[part 2 of 15: package /Cluster]
AUTOSAR XML (schema 4-3-0)
package /Cluster
  can cluster WU_HCP3_CANFD: baudrate=500000, protocol-name=CAN, protocol-version=2.0, bus-off-recovery={bor-counter-l-1-to-l-2=1, bor-time-l-1=0.05, bor-time-l-2=0.2}, can-fd-baudrate=2000000
    can physical channel CHNL: comm-connectors=CN_WU_HCP3_CANFD
      frame KN_Gateway_XIX_WU_HCP3_CANFD: id 0x17F00010, to HCP3_IONode, frame-length=16, can-addressing-mode=EXTENDED, can-frame-rx-behavior=CAN-FD, can-frame-tx-behavior=CAN-FD
        pdu KN_Gateway_XIX_WU_HCP3_CANFD: length=16, transmission-mode-true-timing=cyclic-timing={time-offset=0.0, time-period=0.5}, unused-bit-pattern=0
          signal NM_GW_KompSchutz_XIX_KN_Gateway_XIX_WU_HCP3_CANFD: start 0, 1 bit, little-endian, data-type-policy=OVERRIDE, i-signal-type=PRIMITIVE, init-value=0, base-type=BT_NM_GW_KompSchutz, compu {0=Cx0_inaktiv (CM_NM_GW_KompSchutz_Cx0_inaktiv), 1=Cx1_aktiv (CM_NM_GW_KompSchutz_Cx1_aktiv)}, range raw 0..1, transfer-property=PENDING  # Funktionseinschränung aufgrund Komponentenschutz aktiv
          signal NM_GW_Abschaltstufe_aktiv_XIX_KN_Gateway_XIX_WU_HCP3_CANFD: start 1, 1 bit, little-endian, data-type-policy=OVERRIDE, i-signal-type=PRIMITIVE, init-value=0, base-type=BT_NM_GW_Abschaltstufe_aktiv, compu {1=Cx1_Abschaltstufe_aktiv (CM_NM_GW_Abschaltstufe_aktiv_Cx1_Abschaltstufe_aktiv) (Abschaltstufe aktiv)}, range raw 1, transfer-property=PENDING  # Funktionsabschaltung wegen Abschaltschaltstufe
          signal NM_GW_Transport_Mode_XIX_KN_Gateway_XIX_WU_HCP3_CANFD: start 2, 1 bit, little-endian, data-type-policy=OVERRIDE, i-signal-type=PRIMITIVE, init-value=0, base-type=BT_NM_GW_Transport_Mode, compu {1=Cx1_Transportmodus_aktiv (CM_NM_GW_Transport_Mode_Cx1_Transportmodus_aktiv) (Transportmodus aktiv)}, range raw 1, transfer-property=PENDING  # Funktionseinschränung aufgrund Transport Mode aktiv
          signal Gateway_Nachlauftyp_XIX_KN_Gateway_XIX_WU_HCP3_CANFD: start 4, 4 bit, little-endian, data-type-policy=OVERRIDE, i-signal-type=PRIMITIVE, init-value=2, base-type=BT_Gateway_Nachlauftyp, compu {2=Cx2_Komm_bei_KL15_AUS (CM_Gateway_Nachlauftyp_Cx2_Komm_bei_KL15_AUS), 1=Cx1_Komm_nach_KL15_AUS (CM_Gateway_Nachlauftyp_Cx1_Komm_nach_KL15_AUS), 0=Cx0_Komm_bei_KL15_EIN (CM_Gateway_Nachlauftyp_Cx0_Komm_bei_KL15_EIN)}, range raw 0..2, transfer-property=PENDING, to HCP3_IONode(timeout 5 s)  # Abgebildet wird die von der Hardware vorgegebene Möglichkeit, die Kommunikation nach Klemme 15 = AUS aufrecht zu erhalten. Es wird ein Init-Wert gesendet.
          signal Gateway_SNI_10_XIX_KN_Gateway_XIX_WU_HCP3_CANFD: start 8, 10 bit, little-endian, data-type-policy=OVERRIDE, i-signal-type=PRIMITIVE, init-value=16, base-type=BT_Gateway_SNI_10, compu {phys=raw for raw 0..1023}, range phys 0..1023, raw 0..1023, transfer-property=PENDING  # Source Node-Identifier (SNI) identifiziert den Sender der NM-Botschaft (Knotenadresse) eindeutig im Fahrzeug
          signal KN_Gateway_ECUKnockOut_XIX_KN_Gateway_XIX_WU_HCP3_CANFD: start 18, 2 bit, little-endian, data-type-policy=OVERRIDE, i-signal-type=PRIMITIVE, init-value=0, base-type=BT_KN_Gateway_ECUKnockOut, compu {1=Cx1_Veto_war_aktiv (CM_KN_Gateway_ECUKnockOut_Cx1_Veto_war_aktiv), 3=Cx3_Funktion_deaktiviert (CM_KN_Gateway_ECUKnockOut_Cx3_Funktion_deaktiviert), 0=Cx0_Funktion_nicht_ausgeloest (CM_KN_Gateway_ECUKnockOut_Cx0_Funktion_nicht_ausgeloest), 2=Cx2_Funktion_ausgeloest (CM_KN_Gateway_ECUKnockOut_Cx2_Funktion_ausgeloest)}, range raw 0..3, transfer-property=PENDING  # Ausgabe des ECUKnockout-Status
          signal KN_Gateway_DiagPfad_V12_XIX_KN_Gateway_XIX_WU_HCP3_CANFD: start 20, 1 bit, little-endian, data-type-policy=OVERRIDE, i-signal-type=PRIMITIVE, base-type=BT_KN_Gateway_DiagPfad_V12, compu {0=Cx0_Aktiv (CM_KN_Gateway_DiagPfad_V12_Cx0_Aktiv), 1=Cx1_inaktiv (CM_KN_Gateway_DiagPfad_V12_Cx1_inaktiv)}, range raw 0..1, transfer-property=PENDING  # Kennzeichnung der Diagnosefaehigkeit des BusInterfaces eines Steuergeraetes (Knoten) Umfang LAH 80127 Bei Nutzung des Signal explizit pro angebundenem BusInterface zu setzen
          signal NM_Gateway_Lokalaktiv_XIX_KN_Gateway_XIX_WU_HCP3_CANFD: start 21, 1 bit, little-endian, data-type-policy=OVERRIDE, i-signal-type=PRIMITIVE, init-value=0, base-type=BT_NM_Gateway_Lokalaktiv, compu {1=Cx1_war_lokal_aktiv (CM_NM_Gateway_Lokalaktiv_Cx1_war_lokal_aktiv), 0=Cx0_war_nicht_lokal_aktiv (CM_NM_Gateway_Lokalaktiv_Cx0_war_nicht_lokal_aktiv)}, range raw 0..1, transfer-property=PENDING  # Zeigt an ob das SG nach Klemme15 AUS und nach entsprechender MAX Aktivzeit noch aktiv war.
          signal NM_Gateway_Subsystemaktiv_XIX_KN_Gateway_XIX_WU_HCP3_CANFD: start 22, 1 bit, little-endian, data-type-policy=OVERRIDE, i-signal-type=PRIMITIVE, init-value=0, base-type=BT_NM_Gateway_Subsystemaktiv, compu {0=Cx0_Subsystem_war_nicht_lokalaktiv (CM_NM_Gateway_Subsystemaktiv_Cx0_Subsystem_war_nicht_lokalaktiv), 1=Cx1_war_lokalaktiv (CM_NM_Gateway_Subsystemaktiv_Cx1_war_lokalaktiv)}, range raw 0..1, transfer-property=PENDING  # Zeigt an ob ein Subsystem des SGs nach Klemme15 AUS und nach entsprechender MAX Aktivzeit noch aktiv war
          signal GW_KD_Fehler_XIX_KN_Gateway_XIX_WU_HCP3_CANFD: start 23, 1 bit, little-endian, data-type-policy=OVERRIDE, i-signal-type=PRIMITIVE, init-value=0, base-type=BT_GW_KD_Fehler, compu {0=Cx0_kein_KD_Fehler (CM_GW_KD_Fehler_Cx0_kein_KD_Fehler), 1=Cx1_KD_Fehler (CM_GW_KD_Fehler_Cx1_KD_Fehler)}, range raw 0..1, transfer-property=PENDING  # Kundendienstfehlerbit Gateway zur Anzeige eines im Gateway abgelegten Fehlerspeichereintrages.
          signal KN_Gateway_ECUKnockOutTimer_XIX_KN_Gateway_XIX_WU_HCP3_CANFD: start 24, 6 bit, little-endian, data-type-policy=OVERRIDE, i-signal-type=PRIMITIVE, init-value=15, base-type=BT_KN_Gateway_ECUKnockOutTimer, compu {phys=raw for raw 0..62, 63=Cx3f_ECUKnockOut_deaktiviert (CM_KN_Gateway_ECUKnockOutTimer_Cx3f_ECUKnockOut_deaktiviert); unit Unit_Minut}, range phys 0..62 Unit_Minut, raw 0..63, unit=Unit_Minut, transfer-property=PENDING  # Ausgabe des ECUKnockOut-Timer
          signal KN_Gateway_BusKnockOut_XIX_KN_Gateway_XIX_WU_HCP3_CANFD: start 30, 2 bit, little-endian, data-type-policy=OVERRIDE, i-signal-type=PRIMITIVE, init-value=0, base-type=BT_KN_Gateway_BusKnockOut, compu {2=Cx2_Funktion_ausgeloest (CM_KN_Gateway_BusKnockOut_Cx2_Funktion_ausgeloest), 3=Cx3_Funktion_deaktiviert (CM_KN_Gateway_BusKnockOut_Cx3_Funktion_deaktiviert), 0=Cx0_Funktion_nicht_ausgeloest (CM_KN_Gateway_BusKnockOut_Cx0_Funktion_nicht_ausgeloest), 1=Cx1_Veto_aktiv (CM_KN_Gateway_BusKnockOut_Cx1_Veto_aktiv)}, range raw 0..3, transfer-property=PENDING  # Ausgabe des BusKnockout-Status
          signal KN_Gateway_BusKnockOutTimer_XIX_KN_Gateway_XIX_WU_HCP3_CANFD: start 32, 8 bit, little-endian, data-type-policy=OVERRIDE, i-signal-type=PRIMITIVE, init-value=15, base-type=BT_KN_Gateway_BusKnockOutTimer, compu {phys=raw for raw 0..254, 255=Cxff_BusKnockOut_deaktiviert (CM_KN_Gateway_BusKnockOutTimer_Cxff_BusKnockOut_deaktiviert); unit Unit_Minut}, range phys 0..254 Unit_Minut, raw 0..255, unit=Unit_Minut, transfer-property=PENDING  # Ausgabe des BusKnockOut-Timer
          signal NM_Gateway_FCIB_XIX_KN_Gateway_XIX_WU_HCP3_CANFD: start 40, 56 bit, opaque, data-type-policy=OVERRIDE, i-signal-type=ARRAY, init-value=[65, 0, 0, 70, 0, 0, 0], base-type=BT_NM_Gateway_FCIB, compu {9007199254740992=Cx20000000000000_54_reserved (CM_NM_Gateway_FCIB_Cx20000000000000_54_reserved) (54_<reserved>), 32768=Cx8000_16_InfotainmentDisplay (CM_NM_Gateway_FCIB_Cx8000_16_InfotainmentDisplay), 8=Cx8_04_Basefunction_DrivingAssistance (CM_NM_Gateway_FCIB_Cx8_04_Basefunction_DrivingAssistance), 549755813888=Cx8000000000_40_Diagnosis_Energy (CM_NM_Gateway_FCIB_Cx8000000000_40_Diagnosis_Energy), 8388608=Cx800000_24_ThermoManagement (CM_NM_Gateway_FCIB_Cx800000_24_ThermoManagement), 4=Cx4_03_Basefunction_Chassis (CM_NM_Gateway_FCIB_Cx4_03_Basefunction_Chassis), 17179869184=Cx400000000_35_ExteriorSound (CM_NM_Gateway_FCIB_Cx400000000_35_ExteriorSound), 4096=Cx1000_13_Airbag (CM_NM_Gateway_FCIB_Cx1000_13_Airbag), 1073741824=Cx40000000_31_MultifunctionalSteeringWheel (CM_NM_Gateway_FCIB_Cx40000000_31_MultifunctionalSteeringWheel), 34359738368=Cx800000000_36_Preheater (CM_NM_Gateway_FCIB_Cx800000000_36_Preheater), 68719476736=Cx1000000000_37_HighVoltage_WirelessChargingStation (CM_NM_Gateway_FCIB_Cx1000000000_37_HighVoltage_WirelessChargingStation), 17592186044416=Cx100000000000_45_Diagnosis_Comfort (CM_NM_Gateway_FCIB_Cx100000000000_45_Diagnosis_Comfort), 8796093022208=Cx80000000000_44_Diagnosis_Infotainment (CM_NM_Gateway_FCIB_Cx80000000000_44_Diagnosis_Infotainment), 524288=Cx80000_20_OptionalComfort (CM_NM_Gateway_FCIB_Cx80000_20_OptionalComfort), 33554432=Cx2000000_26_HighVoltage_Charging (CM_NM_Gateway_FCIB_Cx2000000_26_HighVoltage_Charging), 18014398509481984=Cx40000000000000_55_Dimming (CM_NM_Gateway_FCIB_Cx40000000000000_55_Dimming), 16777216=Cx1000000_25_AccessSystemSensors (CM_NM_Gateway_FCIB_Cx1000000_25_AccessSystemSensors), 16=Cx10_05_Basefunction_Infotainment (CM_NM_Gateway_FCIB_Cx10_05_Basefunction_Infotainment), 2147483648=Cx80000000_32_OnlineAccess (CM_NM_Gateway_FCIB_Cx80000000_32_OnlineAccess), 1024=Cx400_11_Chassis (CM_NM_Gateway_FCIB_Cx400_11_Chassis), 536870912=Cx20000000_30_EnergyManagement (CM_NM_Gateway_FCIB_Cx20000000_30_EnergyManagement), 512=Cx200_10_Powertrain (CM_NM_Gateway_FCIB_Cx200_10_Powertrain), 2097152=Cx200000_22_ExteriorLights (CM_NM_Gateway_FCIB_Cx200000_22_ExteriorLights), 35184372088832=Cx200000000000_46_Diagnosis_Light (CM_NM_Gateway_FCIB_Cx200000000000_46_Diagnosis_Light), 281474976710656=Cx1000000000000_49_reserved (CM_NM_Gateway_FCIB_Cx1000000000000_49_reserved) (49_<reserved>), 1=Cx1_01_CarWakeUp (CM_NM_Gateway_FCIB_Cx1_01_CarWakeUp), 65536=Cx10000_17_Audio (CM_NM_Gateway_FCIB_Cx10000_17_Audio), 32=Cx20_06_Basefunction_ComfortLight (CM_NM_Gateway_FCIB_Cx20_06_Basefunction_ComfortLight), 268435456=Cx10000000_29_SteeringColumnLock (CM_NM_Gateway_FCIB_Cx10000000_29_SteeringColumnLock), 2048=Cx800_12_GearSelector (CM_NM_Gateway_FCIB_Cx800_12_GearSelector), 4194304=Cx400000_23_Climate (CM_NM_Gateway_FCIB_Cx400000_23_Climate), 70368744177664=Cx400000000000_47_Diagnosis_ComfortLINs (CM_NM_Gateway_FCIB_Cx400000000000_47_Diagnosis_ComfortLINs), 67108864=Cx4000000_27_Timemaster_Timer (CM_NM_Gateway_FCIB_Cx4000000_27_Timemaster_Timer), 256=Cx100_09_reserved (CM_NM_Gateway_FCIB_Cx100_09_reserved) (09_<reserved>), 1174405185=Cx46000041_InitValueFCIB (CM_NM_Gateway_FCIB_Cx46000041_InitValueFCIB), 140737488355328=Cx800000000000_48_Diagnosis_ClimateTmeLINs (CM_NM_Gateway_FCIB_Cx800000000000_48_Diagnosis_ClimateTmeLINs), 131072=Cx20000_18_VirtualSideMirrors (CM_NM_Gateway_FCIB_Cx20000_18_VirtualSideMirrors), 2=Cx2_02_Basefunction_Powertrain (CM_NM_Gateway_FCIB_Cx2_02_Basefunction_Powertrain), 2199023255552=Cx20000000000_42_Diagnosis_FlexRay (CM_NM_Gateway_FCIB_Cx20000000000_42_Diagnosis_FlexRay), 36028797018963968=Cx80000000000000_56_ChargingStatus (CM_NM_Gateway_FCIB_Cx80000000000000_56_ChargingStatus), 8589934592=Cx200000000_34_GPS_Localization (CM_NM_Gateway_FCIB_Cx200000000_34_GPS_Localization), 134217728=Cx8000000_28_OnboardTester_DataCollector (CM_NM_Gateway_FCIB_Cx8000000_28_OnboardTester_DataCollector), 128=Cx80_08_Basefunction_Connectivity (CM_NM_Gateway_FCIB_Cx80_08_Basefunction_Connectivity), 1099511627776=Cx10000000000_41_Diagnosis_Powertrain (CM_NM_Gateway_FCIB_Cx10000000000_41_Diagnosis_Powertrain), 8192=Cx2000_14_InfotainmentExtensions (CM_NM_Gateway_FCIB_Cx2000_14_InfotainmentExtensions), 4503599627370496=Cx10000000000000_53_Lock_Unlock (CM_NM_Gateway_FCIB_Cx10000000000000_53_Lock_Unlock), 1048576=Cx100000_21_AirSuspension (CM_NM_Gateway_FCIB_Cx100000_21_AirSuspension), 262144=Cx40000_19_Doors_Hatches (CM_NM_Gateway_FCIB_Cx40000_19_Doors_Hatches), 64=Cx40_07_Basefunction_CrossSection (CM_NM_Gateway_FCIB_Cx40_07_Basefunction_CrossSection), 4294967296=Cx100000000_33_ExternalWirelessCommunication (CM_NM_Gateway_FCIB_Cx100000000_33_ExternalWirelessCommunication), 4398046511104=Cx40000000000_43_Diagnosis_DrivingAssistance (CM_NM_Gateway_FCIB_Cx40000000000_43_Diagnosis_DrivingAssistance), 16384=Cx4000_15_InstrumentclusterDisplay (CM_NM_Gateway_FCIB_Cx4000_15_InstrumentclusterDisplay)}, range raw 1..36028797018963968, transfer-property=PENDING, to HCP3_IONode(timeout 5 s)  # FCIB = Funktions-Cluster-Initialisierungs-Bits
          signal Gateway_Matrix_Version_XIX_KN_Gateway_XIX_WU_HCP3_CANFD: start 96, 6 bit, little-endian, data-type-policy=OVERRIDE, i-signal-type=PRIMITIVE, init-value=0, base-type=BT_Gateway_Matrix_Version, compu {phys=raw for raw 0..63; unit Unit_None}, range phys 0..63 Unit_None, raw 0..63, unit=Unit_None, transfer-property=PENDING  # Signal gibt an welche Matrix-Version des Baukasten umgesetzt ist. z.B. V.08.xx, das Signal gibt den Wert für xx an
          signal Gateway_Matrix_Generation_XIX_KN_Gateway_XIX_WU_HCP3_CANFD: start 102, 3 bit, little-endian, data-type-policy=OVERRIDE, i-signal-type=PRIMITIVE, init-value=0, base-type=BT_Gateway_Matrix_Generation, compu {phys=raw for raw 0..7; unit Unit_None}, range phys 0..7 Unit_None, raw 0..7, unit=Unit_None, transfer-property=PENDING  # Signal gibt an welche Matrix-Generation umgesetzt ist
      frame KN_Info_El_XIX_WU_HCP3_CANFD: id 0x17F00073, from HCP3_IONode, frame-length=16, can-addressing-mode=EXTENDED, can-frame-rx-behavior=CAN-FD, can-frame-tx-behavior=CAN-FD
        pdu KN_Info_El_XIX_WU_HCP3_CANFD: length=16, transmission-mode-true-timing=cyclic-timing={time-offset=0.0, time-period=0.5}, unused-bit-pattern=0
          signal Info_El_Nachlauftyp_XIX_KN_Info_El_XIX_WU_HCP3_CANFD: start 4, 4 bit, little-endian, data-type-policy=OVERRIDE, i-signal-type=PRIMITIVE, init-value=2, base-type=BT_Info_El_Nachlauftyp, compu {0=Cx0_Komm_bei_KL15_EIN (CM_Info_El_Nachlauftyp_Cx0_Komm_bei_KL15_EIN), 2=Cx2_Komm_bei_KL15_AUS (CM_Info_El_Nachlauftyp_Cx2_Komm_bei_KL15_AUS), 1=Cx1_Komm_nach_KL15_AUS (CM_Info_El_Nachlauftyp_Cx1_Komm_nach_KL15_AUS)}, range raw 0..2, transfer-property=PENDING  # Abgebildet wird die von der Hardware vorgegebene Möglichkeit, die Kommunikation nach Klemme 15 = AUS aufrecht zu erhalten. Es wird ein Init-Wert gesendet.
          signal Info_El_SNI_10_XIX_KN_Info_El_XIX_WU_HCP3_CANFD: start 8, 10 bit, little-endian, data-type-policy=OVERRIDE, i-signal-type=PRIMITIVE, init-value=115, base-type=BT_Info_El_SNI_10, compu {phys=raw for raw 0..1023}, range phys 0..1023, raw 0..1023, transfer-property=PENDING  # Source Node-Identifier (SNI) identifiziert den Sender der NM-Botschaft (Knotenadresse) eindeutig im Fahrzeug
          signal KN_Info_El_ECUKnockOut_XIX_KN_Info_El_XIX_WU_HCP3_CANFD: start 18, 2 bit, little-endian, data-type-policy=OVERRIDE, i-signal-type=PRIMITIVE, init-value=0, base-type=BT_KN_Info_El_ECUKnockOut, compu {2=Cx2_Funktion_ausgeloest (CM_KN_Info_El_ECUKnockOut_Cx2_Funktion_ausgeloest), 1=Cx1_Veto_war_aktiv (CM_KN_Info_El_ECUKnockOut_Cx1_Veto_war_aktiv), 0=Cx0_Funktion_nicht_ausgeloest (CM_KN_Info_El_ECUKnockOut_Cx0_Funktion_nicht_ausgeloest), 3=Cx3_Funktion_deaktiviert (CM_KN_Info_El_ECUKnockOut_Cx3_Funktion_deaktiviert)}, range raw 0..3, transfer-property=PENDING  # Ausgabe des ECUKnockout-Status
          signal KN_Info_El_DiagPfad_V12_XIX_KN_Info_El_XIX_WU_HCP3_CANFD: start 20, 1 bit, little-endian, data-type-policy=OVERRIDE, i-signal-type=PRIMITIVE, base-type=BT_KN_Info_El_DiagPfad_V12, compu {0=Cx0_Aktiv (CM_KN_Info_El_DiagPfad_V12_Cx0_Aktiv), 1=Cx1_inaktiv (CM_KN_Info_El_DiagPfad_V12_Cx1_inaktiv)}, range raw 0..1, transfer-property=PENDING  # Kennzeichnung der Diagnosefaehigkeit des BusInterfaces eines Steuergeraetes (Knoten) Umfang LAH 80127 Bei Nutzung des Signal explizit pro angebundenem BusInterface zu setzen
          signal Info_El_KD_Fehler_XIX_KN_Info_El_XIX_WU_HCP3_CANFD: start 23, 1 bit, little-endian, data-type-policy=OVERRIDE, i-signal-type=PRIMITIVE, init-value=0, base-type=BT_Info_El_KD_Fehler, compu {0=Cx0_Kein_KD_Fehler (CM_Info_El_KD_Fehler_Cx0_Kein_KD_Fehler), 1=Cx1_KD_Fehler (CM_Info_El_KD_Fehler_Cx1_KD_Fehler)}, range raw 0..1, transfer-property=PENDING  # Bei gesetztem Bit ist mindestens ein Kundendienstfehler eingetragen
          signal KN_Info_El_ECUKnockOutTimer_XIX_KN_Info_El_XIX_WU_HCP3_CANFD: start 24, 6 bit, little-endian, data-type-policy=OVERRIDE, i-signal-type=PRIMITIVE, init-value=15, base-type=BT_KN_Info_El_ECUKnockOutTimer, compu {phys=raw for raw 0..62, 63=Cx3f_ECUKnockOut_deaktiviert (CM_KN_Info_El_ECUKnockOutTimer_Cx3f_ECUKnockOut_deaktiviert); unit Unit_Minut}, range phys 0..62 Unit_Minut, raw 0..63, unit=Unit_Minut, transfer-property=PENDING  # Ausgabe des ECUKnockOut-Timer
          signal KN_Info_El_BusKnockOut_XIX_KN_Info_El_XIX_WU_HCP3_CANFD: start 30, 2 bit, little-endian, data-type-policy=OVERRIDE, i-signal-type=PRIMITIVE, init-value=0, base-type=BT_KN_Info_El_BusKnockOut, compu {0=Cx0_Funktion_nicht_ausgeloest (CM_KN_Info_El_BusKnockOut_Cx0_Funktion_nicht_ausgeloest), 2=Cx2_Funktion_ausgeloest (CM_KN_Info_El_BusKnockOut_Cx2_Funktion_ausgeloest), 1=Cx1_Veto_aktiv (CM_KN_Info_El_BusKnockOut_Cx1_Veto_aktiv), 3=Cx3_Funktion_deaktiviert (CM_KN_Info_El_BusKnockOut_Cx3_Funktion_deaktiviert)}, range raw 0..3, transfer-property=PENDING  # Ausgabe des BusKnockout-Status
          signal KN_Info_El_BusKnockOutTimer_XIX_KN_Info_El_XIX_WU_HCP3_CANFD: start 32, 8 bit, little-endian, data-type-policy=OVERRIDE, i-signal-type=PRIMITIVE, init-value=15, base-type=BT_KN_Info_El_BusKnockOutTimer, compu {phys=raw for raw 0..254, 255=Cxff_BusKnockOut_deaktiviert (CM_KN_Info_El_BusKnockOutTimer_Cxff_BusKnockOut_deaktiviert); unit Unit_Minut}, range phys 0..254 Unit_Minut, raw 0..255, unit=Unit_Minut, transfer-property=PENDING  # Ausgabe des BusKnockOut-Timer
          signal NM_Info_El_FCIB_XIX_KN_Info_El_XIX_WU_HCP3_CANFD: start 40, 56 bit, opaque, data-type-policy=OVERRIDE, i-signal-type=ARRAY, init-value=[17, 0, 0, 0, 0, 0, 0], base-type=BT_NM_Info_El_FCIB, compu {256=Cx100_09_reserved (CM_NM_Info_El_FCIB_Cx100_09_reserved) (09_<reserved>), 16=Cx10_05_Basefunction_Infotainment (CM_NM_Info_El_FCIB_Cx10_05_Basefunction_Infotainment), 4503599627370496=Cx10000000000000_53_Lock_Unlock (CM_NM_Info_El_FCIB_Cx10000000000000_53_Lock_Unlock), 17=Cx11_InitValueFCIB (CM_NM_Info_El_FCIB_Cx11_InitValueFCIB), 536870912=Cx20000000_30_EnergyManagement (CM_NM_Info_El_FCIB_Cx20000000_30_EnergyManagement), 16777216=Cx1000000_25_AccessSystemSensors (CM_NM_Info_El_FCIB_Cx1000000_25_AccessSystemSensors), 1=Cx1_01_CarWakeUp (CM_NM_Info_El_FCIB_Cx1_01_CarWakeUp), 2199023255552=Cx20000000000_42_Diagnosis_FlexRay (CM_NM_Info_El_FCIB_Cx20000000000_42_Diagnosis_FlexRay), 34359738368=Cx800000000_36_Preheater (CM_NM_Info_El_FCIB_Cx800000000_36_Preheater), 268435456=Cx10000000_29_SteeringColumnLock (CM_NM_Info_El_FCIB_Cx10000000_29_SteeringColumnLock), 2048=Cx800_12_GearSelector (CM_NM_Info_El_FCIB_Cx800_12_GearSelector), 128=Cx80_08_Basefunction_Connectivity (CM_NM_Info_El_FCIB_Cx80_08_Basefunction_Connectivity), 4=Cx4_03_Basefunction_Chassis (CM_NM_Info_El_FCIB_Cx4_03_Basefunction_Chassis), 1048576=Cx100000_21_AirSuspension (CM_NM_Info_El_FCIB_Cx100000_21_AirSuspension), 16384=Cx4000_15_InstrumentclusterDisplay (CM_NM_Info_El_FCIB_Cx4000_15_InstrumentclusterDisplay), 2=Cx2_02_Basefunction_Powertrain (CM_NM_Info_El_FCIB_Cx2_02_Basefunction_Powertrain), 134217728=Cx8000000_28_OnboardTester_DataCollector (CM_NM_Info_El_FCIB_Cx8000000_28_OnboardTester_DataCollector), 17179869184=Cx400000000_35_ExteriorSound (CM_NM_Info_El_FCIB_Cx400000000_35_ExteriorSound), 70368744177664=Cx400000000000_47_Diagnosis_ComfortLINs (CM_NM_Info_El_FCIB_Cx400000000000_47_Diagnosis_ComfortLINs), 4194304=Cx400000_23_Climate (CM_NM_Info_El_FCIB_Cx400000_23_Climate), 281474976710656=Cx1000000000000_49_reserved (CM_NM_Info_El_FCIB_Cx1000000000000_49_reserved) (49_<reserved>), 4096=Cx1000_13_Airbag (CM_NM_Info_El_FCIB_Cx1000_13_Airbag), 140737488355328=Cx800000000000_48_Diagnosis_ClimateTmeLINs (CM_NM_Info_El_FCIB_Cx800000000000_48_Diagnosis_ClimateTmeLINs), 36028797018963968=Cx80000000000000_56_ChargingStatus (CM_NM_Info_El_FCIB_Cx80000000000000_56_ChargingStatus), 2147483648=Cx80000000_32_OnlineAccess (CM_NM_Info_El_FCIB_Cx80000000_32_OnlineAccess), 4398046511104=Cx40000000000_43_Diagnosis_DrivingAssistance (CM_NM_Info_El_FCIB_Cx40000000000_43_Diagnosis_DrivingAssistance), 65536=Cx10000_17_Audio (CM_NM_Info_El_FCIB_Cx10000_17_Audio), 17592186044416=Cx100000000000_45_Diagnosis_Comfort (CM_NM_Info_El_FCIB_Cx100000000000_45_Diagnosis_Comfort), 33554432=Cx2000000_26_HighVoltage_Charging (CM_NM_Info_El_FCIB_Cx2000000_26_HighVoltage_Charging), 549755813888=Cx8000000000_40_Diagnosis_Energy (CM_NM_Info_El_FCIB_Cx8000000000_40_Diagnosis_Energy), 4294967296=Cx100000000_33_ExternalWirelessCommunication (CM_NM_Info_El_FCIB_Cx100000000_33_ExternalWirelessCommunication), 262144=Cx40000_19_Doors_Hatches (CM_NM_Info_El_FCIB_Cx40000_19_Doors_Hatches), 9007199254740992=Cx20000000000000_54_reserved (CM_NM_Info_El_FCIB_Cx20000000000000_54_reserved) (54_<reserved>), 18014398509481984=Cx40000000000000_55_Dimming (CM_NM_Info_El_FCIB_Cx40000000000000_55_Dimming), 32768=Cx8000_16_InfotainmentDisplay (CM_NM_Info_El_FCIB_Cx8000_16_InfotainmentDisplay), 524288=Cx80000_20_OptionalComfort (CM_NM_Info_El_FCIB_Cx80000_20_OptionalComfort), 1073741824=Cx40000000_31_MultifunctionalSteeringWheel (CM_NM_Info_El_FCIB_Cx40000000_31_MultifunctionalSteeringWheel), 512=Cx200_10_Powertrain (CM_NM_Info_El_FCIB_Cx200_10_Powertrain), 1024=Cx400_11_Chassis (CM_NM_Info_El_FCIB_Cx400_11_Chassis), 8388608=Cx800000_24_ThermoManagement (CM_NM_Info_El_FCIB_Cx800000_24_ThermoManagement), 32=Cx20_06_Basefunction_ComfortLight (CM_NM_Info_El_FCIB_Cx20_06_Basefunction_ComfortLight), 35184372088832=Cx200000000000_46_Diagnosis_Light (CM_NM_Info_El_FCIB_Cx200000000000_46_Diagnosis_Light), 8589934592=Cx200000000_34_GPS_Localization (CM_NM_Info_El_FCIB_Cx200000000_34_GPS_Localization), 8=Cx8_04_Basefunction_DrivingAssistance (CM_NM_Info_El_FCIB_Cx8_04_Basefunction_DrivingAssistance), 8192=Cx2000_14_InfotainmentExtensions (CM_NM_Info_El_FCIB_Cx2000_14_InfotainmentExtensions), 68719476736=Cx1000000000_37_HighVoltage_WirelessChargingStation (CM_NM_Info_El_FCIB_Cx1000000000_37_HighVoltage_WirelessChargingStation), 67108864=Cx4000000_27_Timemaster_Timer (CM_NM_Info_El_FCIB_Cx4000000_27_Timemaster_Timer), 64=Cx40_07_Basefunction_CrossSection (CM_NM_Info_El_FCIB_Cx40_07_Basefunction_CrossSection), 8796093022208=Cx80000000000_44_Diagnosis_Infotainment (CM_NM_Info_El_FCIB_Cx80000000000_44_Diagnosis_Infotainment), 131072=Cx20000_18_VirtualSideMirrors (CM_NM_Info_El_FCIB_Cx20000_18_VirtualSideMirrors), 2097152=Cx200000_22_ExteriorLights (CM_NM_Info_El_FCIB_Cx200000_22_ExteriorLights), 1099511627776=Cx10000000000_41_Diagnosis_Powertrain (CM_NM_Info_El_FCIB_Cx10000000000_41_Diagnosis_Powertrain)}, range raw 1..36028797018963968, transfer-property=PENDING  # FCIB = Funktions-Cluster-Initialisierungs-Bits
      frame NM_Gateway_XIX_WU_HCP3_CANFD: id 0x1B000010, to HCP3_IONode, frame-length=24, can-addressing-mode=EXTENDED, can-frame-rx-behavior=CAN-FD, can-frame-tx-behavior=CAN-FD, rx-identifier-range={lower-can-id=452984832, upper-can-id=452985855}
        nm pdu NM_Gateway_XIX_WU_HCP3_CANFD: length=24, unused-bit-pattern=0
          signal NM_Gateway_CBV_AWB_XIX_NM_Gateway_XIX_WU_HCP3_CANFD: start 4, 1 bit, little-endian, data-type-policy=OVERRIDE, i-signal-type=PRIMITIVE, init-value=0, base-type=BT_NM_Gateway_CBV_AWB, compu {0=Cx0_Passiver_WakeUp (CM_NM_Gateway_CBV_AWB_Cx0_Passiver_WakeUp), 1=Cx1_Aktiver_WakeUp (CM_NM_Gateway_CBV_AWB_Cx1_Aktiver_WakeUp)}, range raw 0..1, transfer-property=TRIGGERED  # Das Signal ist zu setzen, wenn das SG aktiv den Bus geweckt hat 0 = Passiver_WakeUp = SG hat das Netzwerk nicht aktiv geweckt 1 = Akitiver_WakeUp = SG hat das Netzwerk aktiv geweckt
          signal NM_Gateway_CBV_CRI_XIX_NM_Gateway_XIX_WU_HCP3_CANFD: start 6, 1 bit, little-endian, data-type-policy=OVERRIDE, i-signal-type=PRIMITIVE, init-value=1, base-type=BT_NM_Gateway_CBV_CRI, compu {0=Cx0_NM_ohne_Clusteranforderungen (CM_NM_Gateway_CBV_CRI_Cx0_NM_ohne_Clusteranforderungen), 1=Cx1_NM_mit_Clusteranforderungen (CM_NM_Gateway_CBV_CRI_Cx1_NM_mit_Clusteranforderungen)}, range raw 0..1, transfer-property=TRIGGERED  # Das Signal ist dauerhaft gesetzt, wenn das NM-Layout Cluster- Anforderungen enthält
          signal NM_Gateway_FCAB_XIX_NM_Gateway_XIX_WU_HCP3_CANFD: start 8, 56 bit, opaque, data-type-policy=OVERRIDE, i-signal-type=ARRAY, init-value=7 x 0b00000000, base-type=BT_NM_Gateway_FCAB, compu {36028797018963968=Cx80000000000000_56_ChargingStatus (CM_NM_Gateway_FCAB_Cx80000000000000_56_ChargingStatus), 18014398509481984=Cx40000000000000_55_Dimming (CM_NM_Gateway_FCAB_Cx40000000000000_55_Dimming), 128=Cx80_08_Basefunction_Connectivity (CM_NM_Gateway_FCAB_Cx80_08_Basefunction_Connectivity), 32=Cx20_06_Basefunction_ComfortLight (CM_NM_Gateway_FCAB_Cx20_06_Basefunction_ComfortLight), 268435456=Cx10000000_29_SteeringColumnLock (CM_NM_Gateway_FCAB_Cx10000000_29_SteeringColumnLock), 8388608=Cx800000_24_ThermoManagement (CM_NM_Gateway_FCAB_Cx800000_24_ThermoManagement), 1=Cx1_01_CarWakeUp (CM_NM_Gateway_FCAB_Cx1_01_CarWakeUp), 2=Cx2_02_Basefunction_Powertrain (CM_NM_Gateway_FCAB_Cx2_02_Basefunction_Powertrain), 70368744177664=Cx400000000000_47_Diagnosis_ComfortLINs (CM_NM_Gateway_FCAB_Cx400000000000_47_Diagnosis_ComfortLINs), 256=Cx100_09_reserved (CM_NM_Gateway_FCAB_Cx100_09_reserved) (09_<reserved>), 35184372088832=Cx200000000000_46_Diagnosis_Light (CM_NM_Gateway_FCAB_Cx200000000000_46_Diagnosis_Light), 2097152=Cx200000_22_ExteriorLights (CM_NM_Gateway_FCAB_Cx200000_22_ExteriorLights), 262144=Cx40000_19_Doors_Hatches (CM_NM_Gateway_FCAB_Cx40000_19_Doors_Hatches), 8=Cx8_04_Basefunction_DrivingAssistance (CM_NM_Gateway_FCAB_Cx8_04_Basefunction_DrivingAssistance), 536870912=Cx20000000_30_EnergyManagement (CM_NM_Gateway_FCAB_Cx20000000_30_EnergyManagement), 524288=Cx80000_20_OptionalComfort (CM_NM_Gateway_FCAB_Cx80000_20_OptionalComfort), 8796093022208=Cx80000000000_44_Diagnosis_Infotainment (CM_NM_Gateway_FCAB_Cx80000000000_44_Diagnosis_Infotainment), 9007199254740992=Cx20000000000000_54_reserved (CM_NM_Gateway_FCAB_Cx20000000000000_54_reserved) (54_<reserved>), 32768=Cx8000_16_InfotainmentDisplay (CM_NM_Gateway_FCAB_Cx8000_16_InfotainmentDisplay), 4194304=Cx400000_23_Climate (CM_NM_Gateway_FCAB_Cx400000_23_Climate), 512=Cx200_10_Powertrain (CM_NM_Gateway_FCAB_Cx200_10_Powertrain), 65536=Cx10000_17_Audio (CM_NM_Gateway_FCAB_Cx10000_17_Audio), 0=Cx0_Init (CM_NM_Gateway_FCAB_Cx0_Init), 16777216=Cx1000000_25_AccessSystemSensors (CM_NM_Gateway_FCAB_Cx1000000_25_AccessSystemSensors), 4=Cx4_03_Basefunction_Chassis (CM_NM_Gateway_FCAB_Cx4_03_Basefunction_Chassis), 4398046511104=Cx40000000000_43_Diagnosis_DrivingAssistance (CM_NM_Gateway_FCAB_Cx40000000000_43_Diagnosis_DrivingAssistance), 67108864=Cx4000000_27_Timemaster_Timer (CM_NM_Gateway_FCAB_Cx4000000_27_Timemaster_Timer), 140737488355328=Cx800000000000_48_Diagnosis_ClimateTmeLINs (CM_NM_Gateway_FCAB_Cx800000000000_48_Diagnosis_ClimateTmeLINs), 8589934592=Cx200000000_34_GPS_Localization (CM_NM_Gateway_FCAB_Cx200000000_34_GPS_Localization), 131072=Cx20000_18_VirtualSideMirrors (CM_NM_Gateway_FCAB_Cx20000_18_VirtualSideMirrors), 68719476736=Cx1000000000_37_HighVoltage_WirelessChargingStation (CM_NM_Gateway_FCAB_Cx1000000000_37_HighVoltage_WirelessChargingStation), 1024=Cx400_11_Chassis (CM_NM_Gateway_FCAB_Cx400_11_Chassis), 8192=Cx2000_14_InfotainmentExtensions (CM_NM_Gateway_FCAB_Cx2000_14_InfotainmentExtensions), 4503599627370496=Cx10000000000000_53_Lock_Unlock (CM_NM_Gateway_FCAB_Cx10000000000000_53_Lock_Unlock), 2048=Cx800_12_GearSelector (CM_NM_Gateway_FCAB_Cx800_12_GearSelector), 1048576=Cx100000_21_AirSuspension (CM_NM_Gateway_FCAB_Cx100000_21_AirSuspension), 1099511627776=Cx10000000000_41_Diagnosis_Powertrain (CM_NM_Gateway_FCAB_Cx10000000000_41_Diagnosis_Powertrain), 2199023255552=Cx20000000000_42_Diagnosis_FlexRay (CM_NM_Gateway_FCAB_Cx20000000000_42_Diagnosis_FlexRay), 16=Cx10_05_Basefunction_Infotainment (CM_NM_Gateway_FCAB_Cx10_05_Basefunction_Infotainment), 17592186044416=Cx100000000000_45_Diagnosis_Comfort (CM_NM_Gateway_FCAB_Cx100000000000_45_Diagnosis_Comfort), 4294967296=Cx100000000_33_ExternalWirelessCommunication (CM_NM_Gateway_FCAB_Cx100000000_33_ExternalWirelessCommunication), 64=Cx40_07_Basefunction_CrossSection (CM_NM_Gateway_FCAB_Cx40_07_Basefunction_CrossSection), 2147483648=Cx80000000_32_OnlineAccess (CM_NM_Gateway_FCAB_Cx80000000_32_OnlineAccess), 4096=Cx1000_13_Airbag (CM_NM_Gateway_FCAB_Cx1000_13_Airbag), 1073741824=Cx40000000_31_MultifunctionalSteeringWheel (CM_NM_Gateway_FCAB_Cx40000000_31_MultifunctionalSteeringWheel), 17179869184=Cx400000000_35_ExteriorSound (CM_NM_Gateway_FCAB_Cx400000000_35_ExteriorSound), 549755813888=Cx8000000000_40_Diagnosis_Energy (CM_NM_Gateway_FCAB_Cx8000000000_40_Diagnosis_Energy), 134217728=Cx8000000_28_OnboardTester_DataCollector (CM_NM_Gateway_FCAB_Cx8000000_28_OnboardTester_DataCollector), 34359738368=Cx800000000_36_Preheater (CM_NM_Gateway_FCAB_Cx800000000_36_Preheater), 281474976710656=Cx1000000000000_49_reserved (CM_NM_Gateway_FCAB_Cx1000000000000_49_reserved) (49_<reserved>), 16384=Cx4000_15_InstrumentclusterDisplay (CM_NM_Gateway_FCAB_Cx4000_15_InstrumentclusterDisplay), 33554432=Cx2000000_26_HighVoltage_Charging (CM_NM_Gateway_FCAB_Cx2000000_26_HighVoltage_Charging)}, range raw 0..36028797018963968, transfer-property=TRIGGERED-ON-CHANGE  # FCAB = Funktions-Cluster-Aktiv-Bits
          signal NM_aktiv_ConnectVerbund_UseCase1_XIX_NM_Gateway_XIX_WU_HCP3_CANFD: start 114, 1 bit, little-endian, data-type-policy=OVERRIDE, i-signal-type=PRIMITIVE, init-value=0, base-type=BT_NM_aktiv_ConnectVerbund_UseCase1, compu {0=Cx0_Inaktiv (CM_NM_aktiv_ConnectVerbund_UseCase1_Cx0_Inaktiv), 1=Cx1_Aktiv (CM_NM_aktiv_ConnectVerbund_UseCase1_Cx1_Aktiv)}, range raw 0..1, transfer-property=TRIGGERED  # Die Connect Steuergeräte HCP3, HCP5 und ConMod sind über einen zusätzlichen Wecknachlauf, inkl. Bus Kommunikation und Backend Verbindung aufgeweckt. Der Kunde hat davor die Funktion "Verlängerte Wachphase An" in der HCP3 Goodbye Screen bestätigt. Die Funktion hat Dauer und Max Werte Analog VoKo oder Prädektives VoKo Funktionalität und darf nur aktiv bleiben solange VoKo an ist (NM_aktiv_Scheibenheizung). Um diese Funktionalität zu ermöglichen sind bestehenden Funktionscluster zu steuern
          signal NM_aktiv_ConnectVerbund_UseCase2_XIX_NM_Gateway_XIX_WU_HCP3_CANFD: start 115, 1 bit, little-endian, data-type-policy=OVERRIDE, i-signal-type=PRIMITIVE, init-value=0, base-type=BT_NM_aktiv_ConnectVerbund_UseCase2, compu {1=Cx1_Aktiv (CM_NM_aktiv_ConnectVerbund_UseCase2_Cx1_Aktiv), 0=Cx0_Inaktiv (CM_NM_aktiv_ConnectVerbund_UseCase2_Cx0_Inaktiv)}, range raw 0..1, transfer-property=TRIGGERED  # Die Connect Steuergeräte HCP3, HCP5 und ConMod bleiben über einen zusätzlichen Wecknachlauf wach, inkl. Bus Kommunikation und Backend Verbindung wenn der Kunde die Funktion "Verlängerte Wachphase An" in der HU Goodbye Screen die Funktion bestätigt. Um diese Funktionalität zu ermöglichen sind bestehenden Funktionscluster zu steuern Die HVEM soll zwischen 5-10 Minuten nachlaufen damit die Connect Verbund die NVEM Batterie optimal ausnutzt
          signal NM_aktiv_ConnectVerbund_UseCase3_XIX_NM_Gateway_XIX_WU_HCP3_CANFD: start 116, 1 bit, little-endian, data-type-policy=OVERRIDE, i-signal-type=PRIMITIVE, init-value=0, base-type=BT_NM_aktiv_ConnectVerbund_UseCase3, compu {1=Cx1_Aktiv (CM_NM_aktiv_ConnectVerbund_UseCase3_Cx1_Aktiv), 0=Cx0_Inaktiv (CM_NM_aktiv_ConnectVerbund_UseCase3_Cx0_Inaktiv)}, range raw 0..1, transfer-property=TRIGGERED  # Die ORU Steuergeräte sind länger wach inkl. Bus Kommunikation und Backend Verbindung wenn der Kunde die Funktion in der HU Goodbye Screen die Funktion "Verlängerte Wachphase An" bestätigt hat. Flash Umfänge bei denen den HV-System aus sein muss, darf nicht länger als 30 Minuten ORU Flashzeit. Andere Umfänge dürfen längere ORU Flashzeit (bis 180 Minuten) anfodern. NM_aktivgrund verfügbar NM_aktiv_OnlineRemoteUpdate
          signal NM_aktiv_ConnectVerbund_UseCase4_XIX_NM_Gateway_XIX_WU_HCP3_CANFD: start 117, 1 bit, little-endian, data-type-policy=OVERRIDE, i-signal-type=PRIMITIVE, init-value=0, base-type=BT_NM_aktiv_ConnectVerbund_UseCase4, compu {1=Cx1_Aktiv (CM_NM_aktiv_ConnectVerbund_UseCase4_Cx1_Aktiv), 0=Cx0_Inaktiv (CM_NM_aktiv_ConnectVerbund_UseCase4_Cx0_Inaktiv)}, range raw 0..1, transfer-property=TRIGGERED  # Die Connect Steuergeräte HCP3, HCP5, HCP4 und ConMod werden geweckt und bleiben wach, inkl. Bus Kommunikation und Backend Verbindung wenn der Kunde die Funktion "Verlängerte Wachphase An" in der Head Unit Goodbye Screen bestätigt hat während das Fahrzeug am DC Ladesäule geladen wird. Um diese Funktionalität zu ermöglichen sind bestehenden Funktionscluster zu steuern
          signal NM_aktiv_ConnectVerbund_UseCase5_XIX_NM_Gateway_XIX_WU_HCP3_CANFD: start 118, 1 bit, little-endian, data-type-policy=OVERRIDE, i-signal-type=PRIMITIVE, init-value=0, base-type=BT_NM_aktiv_ConnectVerbund_UseCase5, compu {0=Cx0_Inaktiv (CM_NM_aktiv_ConnectVerbund_UseCase5_Cx0_Inaktiv), 1=Cx1_Aktiv (CM_NM_aktiv_ConnectVerbund_UseCase5_Cx1_Aktiv)}, range raw 0..1, transfer-property=TRIGGERED  # Die Connect Steuergeräte HCP3, HCP5 und ConMod sind über einen zusätzlichen Wecknachlauf, inkl. Bus Kommunikation und Backend Verbindung aufgeweckt. Der Kunde hat davor die Funktion "Verlängerte Wachphase An" in der HCP3 Goodbye Screen bestätigt. Um diese Funktionalität zu ermöglichen sind bestehenden Funktionscluster zu steuern
          signal NM_aktiv_ConnectVerbund_UseCase6_XIX_NM_Gateway_XIX_WU_HCP3_CANFD: start 119, 1 bit, little-endian, data-type-policy=OVERRIDE, i-signal-type=PRIMITIVE, init-value=0, base-type=BT_NM_aktiv_ConnectVerbund_UseCase6, compu {1=Cx1_Aktiv (CM_NM_aktiv_ConnectVerbund_UseCase6_Cx1_Aktiv), 0=Cx0_Inaktiv (CM_NM_aktiv_ConnectVerbund_UseCase6_Cx0_Inaktiv)}, range raw 0..1, transfer-property=TRIGGERED  # Die Connect Steuergeräte HCP3, HCP5 und ConMod sind über einen zusätzlichen Wecknachlauf, inkl. Bus Kommunikation und Backend Verbindung aufgeweckt während das Fahrzeug am AC Ladesäule geladen wird. Trigger ist eine Anfrage über die App/Backend ins Auto. Der Kunde hat davor die Funktion "Verlängerte Wachphase An" in der HCP3 Goodbye Screen bestätigt. Um diese Funktionalität zu ermöglichen sind bestehenden Funktionscluster zu steuern
          signal NM_aktiv_AutomotiveEdge_1_XIX_NM_Gateway_XIX_WU_HCP3_CANFD: start 120, 1 bit, little-endian, data-type-policy=OVERRIDE, i-signal-type=PRIMITIVE, init-value=0, base-type=BT_NM_aktiv_AutomotiveEdge_1, compu {1=Cx1_Aktiv (CM_NM_aktiv_AutomotiveEdge_1_Cx1_Aktiv), 0=Cx0_Inaktiv (CM_NM_aktiv_AutomotiveEdge_1_Cx0_Inaktiv)}, range raw 0..1, transfer-property=TRIGGERED  # Vorhalt VNSM_UsrId und NM-Aktivgrund-Signal für künftig möglichen Funktionshub ohne erforderlichen K-Matrix Update
          signal NM_aktiv_AutomotiveEdge_2_XIX_NM_Gateway_XIX_WU_HCP3_CANFD: start 121, 1 bit, little-endian, data-type-policy=OVERRIDE, i-signal-type=PRIMITIVE, init-value=0, base-type=BT_NM_aktiv_AutomotiveEdge_2, compu {1=Cx1_Aktiv (CM_NM_aktiv_AutomotiveEdge_2_Cx1_Aktiv), 0=Cx0_Inaktiv (CM_NM_aktiv_AutomotiveEdge_2_Cx0_Inaktiv)}, range raw 0..1, transfer-property=TRIGGERED  # Vorhalt VNSM_UsrId und NM-Aktivgrund-Signal für künftig möglichen Funktionshub ohne erforderlichen K-Matrix Update
          signal NM_aktiv_AutomotiveEdge_3_XIX_NM_Gateway_XIX_WU_HCP3_CANFD: start 122, 1 bit, little-endian, data-type-policy=OVERRIDE, i-signal-type=PRIMITIVE, init-value=0, base-type=BT_NM_aktiv_AutomotiveEdge_3, compu {0=Cx0_Inaktiv (CM_NM_aktiv_AutomotiveEdge_3_Cx0_Inaktiv), 1=Cx1_Aktiv (CM_NM_aktiv_AutomotiveEdge_3_Cx1_Aktiv)}, range raw 0..1, transfer-property=TRIGGERED  # Vorhalt VNSM_UsrId und NM-Aktivgrund-Signal für künftig möglichen Funktionshub ohne erforderlichen K-Matrix Update
          signal NM_aktiv_AutomotiveEdge_4_XIX_NM_Gateway_XIX_WU_HCP3_CANFD: start 123, 1 bit, little-endian, data-type-policy=OVERRIDE, i-signal-type=PRIMITIVE, init-value=0, base-type=BT_NM_aktiv_AutomotiveEdge_4, compu {0=Cx0_Inaktiv (CM_NM_aktiv_AutomotiveEdge_4_Cx0_Inaktiv), 1=Cx1_Aktiv (CM_NM_aktiv_AutomotiveEdge_4_Cx1_Aktiv)}, range raw 0..1, transfer-property=TRIGGERED  # Vorhalt VNSM_UsrId und NM-Aktivgrund-Signal für künftig möglichen Funktionshub ohne erforderlichen K-Matrix Update
          signal NM_aktiv_AutomotiveEdge_5_XIX_NM_Gateway_XIX_WU_HCP3_CANFD: start 124, 1 bit, little-endian, data-type-policy=OVERRIDE, i-signal-type=PRIMITIVE, init-value=0, base-type=BT_NM_aktiv_AutomotiveEdge_5, compu {1=Cx1_Aktiv (CM_NM_aktiv_AutomotiveEdge_5_Cx1_Aktiv), 0=Cx0_Inaktiv (CM_NM_aktiv_AutomotiveEdge_5_Cx0_Inaktiv)}, range raw 0..1, transfer-property=TRIGGERED  # Vorhalt VNSM_UsrId und NM-Aktivgrund-Signal für künftig möglichen Funktionshub ohne erforderlichen K-Matrix Update
          signal NM_aktiv_MVEM_Fremdladung_XIX_NM_Gateway_XIX_WU_HCP3_CANFD: start 125, 1 bit, little-endian, data-type-policy=OVERRIDE, i-signal-type=PRIMITIVE, init-value=0, base-type=BT_NM_aktiv_MVEM_Fremdladung, compu {0=Cx0_Inaktiv (CM_NM_aktiv_MVEM_Fremdladung_Cx0_Inaktiv), 1=Cx1_Aktiv (CM_NM_aktiv_MVEM_Fremdladung_Cx1_Aktiv)}, range raw 0..1, transfer-property=TRIGGERED  # Nach Ausschalten der Kl.15 soll bei 12V-Fremdladungsfreigabe durch das NvEM das MV-Netz noch aktiv gehalten werden oder bei ausgeschalteter Kl.15 aktiviert werden, dazu muss der HCP5 wach sein, der DcDc-Wandler und das BMS mit den jeweiligen Bussen. - 12V-Fremdladung (Fremdladegerät an der 12V-Batterie), damit die 48V-Batterie über den DcDc-Wandler noch geladen werden kann => wachhalten/aufwecken
          signal NM_Gateway_SNI_10_XIX_NM_Gateway_XIX_WU_HCP3_CANFD: start 128, 10 bit, little-endian, data-type-policy=OVERRIDE, i-signal-type=PRIMITIVE, init-value=16, base-type=BT_NM_Gateway_SNI_10, compu {16=Cx10_Gateway_SNI (CM_NM_Gateway_SNI_10_Cx10_Gateway_SNI)}, range raw 16, transfer-property=TRIGGERED  # Source Node-Identifier (SNI) identifiziert den Sender der NM-Botschaft (Knotenadresse) eindeutig im Fahrzeug
          signal NM_Gateway_NM_State_XIX_NM_Gateway_XIX_WU_HCP3_CANFD: start 144, 6 bit, little-endian, data-type-policy=OVERRIDE, i-signal-type=PRIMITIVE, init-value=0, base-type=BT_NM_Gateway_NM_State, compu {8=Cx8_NM_NO_aus_RS (CM_NM_Gateway_NM_State_Cx8_NM_NO_aus_RS), 1=Cx1_NM_RM_aus_BSM (CM_NM_Gateway_NM_State_Cx1_NM_RM_aus_BSM), 4=Cx4_NM_NO_aus_RM (CM_NM_Gateway_NM_State_Cx4_NM_NO_aus_RM), 0=Cx0_Init (CM_NM_Gateway_NM_State_Cx0_Init), 2=Cx2_NM_RM_aus_PBSM (CM_NM_Gateway_NM_State_Cx2_NM_RM_aus_PBSM), 16=Cx10_reserved (CM_NM_Gateway_NM_State_Cx10_reserved), 32=Cx20_reserved (CM_NM_Gateway_NM_State_Cx20_reserved)}, range raw 0..32, transfer-property=TRIGGERED  # 1 = Zustand Repeat Message (<-- Bus-Sleep Mode) 2 = Zustand Repeat Message (<-- Prepare Bus-Sleep Mode) 4 = Zustand Normal Operation (<-- Repeat Message) 8 = Zustand Normal Operation (<-- Ready Sleep)
          signal NM_Gateway_UDS_CC_XIX_NM_Gateway_XIX_WU_HCP3_CANFD: start 151, 1 bit, little-endian, data-type-policy=OVERRIDE, i-signal-type=PRIMITIVE, init-value=0, base-type=BT_NM_Gateway_UDS_CC, compu {0=Cx0_Inaktiv (CM_NM_Gateway_UDS_CC_Cx0_Inaktiv), 1=Cx1_CC_aktiv (CM_NM_Gateway_UDS_CC_Cx1_CC_aktiv)}, range raw 0..1, transfer-property=TRIGGERED  # Funktionseinschränkung aufgrund aktivem UDS-Communication Control, siehe VW80124
          signal NM_Gateway_Wakeup_V12_XIX_NM_Gateway_XIX_WU_HCP3_CANFD: start 152, 8 bit, little-endian, data-type-policy=OVERRIDE, i-signal-type=PRIMITIVE, init-value=0, base-type=BT_NM_Gateway_Wakeup_V12, compu {16=Cx10_WU_ConMod_CANFD (CM_NM_Gateway_Wakeup_V12_Cx10_WU_ConMod_CANFD), 168=Cxa8_AutomotiveEdge_1 (CM_NM_Gateway_Wakeup_V12_Cxa8_AutomotiveEdge_1), 9=Cx9_Buswakeup_HCP5_CANFD02 (CM_NM_Gateway_Wakeup_V12_Cx9_Buswakeup_HCP5_CANFD02), 167=Cxa7_Gefahreninfo (CM_NM_Gateway_Wakeup_V12_Cxa7_Gefahreninfo), 128=Cx80_VNSM_Anforderung (CM_NM_Gateway_Wakeup_V12_Cx80_VNSM_Anforderung), 139=Cx8b_Ladevorbedingung_pruefen (CM_NM_Gateway_Wakeup_V12_Cx8b_Ladevorbedingung_pruefen), 175=Cxaf_WarnblinkerStatusAenderung (CM_NM_Gateway_Wakeup_V12_Cxaf_WarnblinkerStatusAenderung), 148=Cx94_Key_Authentifiz_SMS (CM_NM_Gateway_Wakeup_V12_Cx94_Key_Authentifiz_SMS), 154=Cx9a_E3_SW_Plattform_5 (CM_NM_Gateway_Wakeup_V12_Cx9a_E3_SW_Plattform_5), 169=Cxa9_AutomotiveEdge_2 (CM_NM_Gateway_Wakeup_V12_Cxa9_AutomotiveEdge_2), 137=Cx89_Niveauverstellung_Anfordern (CM_NM_Gateway_Wakeup_V12_Cx89_Niveauverstellung_Anfordern), 172=Cxac_AutomotiveEdge_5 (CM_NM_Gateway_Wakeup_V12_Cxac_AutomotiveEdge_5), 162=Cxa2_SOC_Abfrage (CM_NM_Gateway_Wakeup_V12_Cxa2_SOC_Abfrage), 171=Cxab_AutomotiveEdge_4 (CM_NM_Gateway_Wakeup_V12_Cxab_AutomotiveEdge_4), 6=Cx6_Buswakeup_WU_HCP3_CANFD (CM_NM_Gateway_Wakeup_V12_Cx6_Buswakeup_WU_HCP3_CANFD), 134=Cx86_Start_HV_Grundladen (CM_NM_Gateway_Wakeup_V12_Cx86_Start_HV_Grundladen), 8=Cx8_Buswakeup_HCP5_CANFD01 (CM_NM_Gateway_Wakeup_V12_Cx8_Buswakeup_HCP5_CANFD01), 170=Cxaa_AutomotiveEdge_3 (CM_NM_Gateway_Wakeup_V12_Cxaa_AutomotiveEdge_3), 12=Cxc_Buswakeup_HCP5_CANFD05 (CM_NM_Gateway_Wakeup_V12_Cxc_Buswakeup_HCP5_CANFD05), 136=Cx88_Erw_HV_Laden_Planen (CM_NM_Gateway_Wakeup_V12_Cx88_Erw_HV_Laden_Planen), 138=Cx8a_MOD_Update_Ladevorgang (CM_NM_Gateway_Wakeup_V12_Cx8a_MOD_Update_Ladevorgang), 0=Cx0_Peripherie_Wakeup_Ursache_nicht_bekannt (CM_NM_Gateway_Wakeup_V12_Cx0_Peripherie_Wakeup_Ursache_nicht_bekannt), 156=Cx9c_Remote_Lock_Unlock (CM_NM_Gateway_Wakeup_V12_Cx9c_Remote_Lock_Unlock), 152=Cx98_E3_SW_Plattform_3 (CM_NM_Gateway_Wakeup_V12_Cx98_E3_SW_Plattform_3), 173=Cxad_RemoteVehicleTracking (CM_NM_Gateway_Wakeup_V12_Cxad_RemoteVehicleTracking), 158=Cx9e_OnlineRemoteUpdate (CM_NM_Gateway_Wakeup_V12_Cx9e_OnlineRemoteUpdate), 13=Cxd_Buswakeup_HCP5_CANFD06 (CM_NM_Gateway_Wakeup_V12_Cxd_Buswakeup_HCP5_CANFD06), 155=Cx9b_Remote_Honk_Flash (CM_NM_Gateway_Wakeup_V12_Cx9b_Remote_Honk_Flash), 131=Cx83_Timer_pTMM_abgelaufen (CM_NM_Gateway_Wakeup_V12_Cx83_Timer_pTMM_abgelaufen), 18=Cx12_Buswakeup_Diag_ETH (CM_NM_Gateway_Wakeup_V12_Cx12_Buswakeup_Diag_ETH), 161=Cxa1_VehicleStatusReport_Daten_Erfassen (CM_NM_Gateway_Wakeup_V12_Cxa1_VehicleStatusReport_Daten_Erfassen), 14=Cxe_reserviert (CM_NM_Gateway_Wakeup_V12_Cxe_reserviert), 133=Cx85_Ladezustand (CM_NM_Gateway_Wakeup_V12_Cx85_Ladezustand), 11=Cxb_Buswakeup_HCP5_CANFD04 (CM_NM_Gateway_Wakeup_V12_Cxb_Buswakeup_HCP5_CANFD04), 166=Cxa6_RemoteStart (CM_NM_Gateway_Wakeup_V12_Cxa6_RemoteStart), 151=Cx97_E3_SW_Plattform_2 (CM_NM_Gateway_Wakeup_V12_Cx97_E3_SW_Plattform_2), 132=Cx84_Batteriekonditionierung (CM_NM_Gateway_Wakeup_V12_Cx84_Batteriekonditionierung), 4=Cx4_Buswakeup_WU_HCP1_CANFD (CM_NM_Gateway_Wakeup_V12_Cx4_Buswakeup_WU_HCP1_CANFD), 160=Cxa0_Displayanzeige (CM_NM_Gateway_Wakeup_V12_Cxa0_Displayanzeige), 142=Cx8e_SubbusSteuerung_HCP5 (CM_NM_Gateway_Wakeup_V12_Cx8e_SubbusSteuerung_HCP5), 165=Cxa5_Abschaltstufe (CM_NM_Gateway_Wakeup_V12_Cxa5_Abschaltstufe), 140=Cx8c_NiedervoltEnergieMgmt (CM_NM_Gateway_Wakeup_V12_Cx8c_NiedervoltEnergieMgmt), 164=Cxa4_Ladeanforderung_Erweitert (CM_NM_Gateway_Wakeup_V12_Cxa4_Ladeanforderung_Erweitert), 5=Cx5_Buswakeup_WU_HCP2_CANFD (CM_NM_Gateway_Wakeup_V12_Cx5_Buswakeup_WU_HCP2_CANFD), 153=Cx99_E3_SW_Plattform_4 (CM_NM_Gateway_Wakeup_V12_Cx99_E3_SW_Plattform_4), 146=Cx92_Ladeanforderung (CM_NM_Gateway_Wakeup_V12_Cx92_Ladeanforderung), 141=Cx8d_Timer_HVLM_abgelaufen (CM_NM_Gateway_Wakeup_V12_Cx8d_Timer_HVLM_abgelaufen), 157=Cx9d_Remote_PreKlimatisierung (CM_NM_Gateway_Wakeup_V12_Cx9d_Remote_PreKlimatisierung), 150=Cx96_E3_SW_Plattform_1 (CM_NM_Gateway_Wakeup_V12_Cx96_E3_SW_Plattform_1), 143=Cx8f_CommunicationControl (CM_NM_Gateway_Wakeup_V12_Cx8f_CommunicationControl), 10=Cxa_Buswakeup_HCP5_CAN03 (CM_NM_Gateway_Wakeup_V12_Cxa_Buswakeup_HCP5_CAN03), 135=Cx87_Erw_HV_Laden_Anfordern (CM_NM_Gateway_Wakeup_V12_Cx87_Erw_HV_Laden_Anfordern), 7=Cx7_Buswakeup_WU_HCP4_CANFD (CM_NM_Gateway_Wakeup_V12_Cx7_Buswakeup_WU_HCP4_CANFD), 2=Cx2_KL15_HW (CM_NM_Gateway_Wakeup_V12_Cx2_KL15_HW), 145=Cx91_HV_Anforderung (CM_NM_Gateway_Wakeup_V12_Cx91_HV_Anforderung), 17=Cx11_Buswakeup_Diag_CANFD (CM_NM_Gateway_Wakeup_V12_Cx11_Buswakeup_Diag_CANFD), 144=Cx90_Ladezugang_ansteuern (CM_NM_Gateway_Wakeup_V12_Cx90_Ladezugang_ansteuern), 163=Cxa3_LHW_eventAirBagDeployment (CM_NM_Gateway_Wakeup_V12_Cxa3_LHW_eventAirBagDeployment), 3=Cx3_KL30_Reset (CM_NM_Gateway_Wakeup_V12_Cx3_KL30_Reset), 159=Cx9f_OnlineRemoteUpdate_PrePost (CM_NM_Gateway_Wakeup_V12_Cx9f_OnlineRemoteUpdate_PrePost), 147=Cx93_HV_Aktivieren (CM_NM_Gateway_Wakeup_V12_Cx93_HV_Aktivieren), 174=Cxae_OnlinePannenruf (CM_NM_Gateway_Wakeup_V12_Cxae_OnlinePannenruf), 129=Cx81_Timer_TME_abgelaufen (CM_NM_Gateway_Wakeup_V12_Cx81_Timer_TME_abgelaufen), 1=Cx1_Bus_Wakeup (CM_NM_Gateway_Wakeup_V12_Cx1_Bus_Wakeup), 130=Cx82_Timer_ELF_abgelaufen (CM_NM_Gateway_Wakeup_V12_Cx82_Timer_ELF_abgelaufen), 176=Cxb0_ConnectVerbund_UseCase1 (CM_NM_Gateway_Wakeup_V12_Cxb0_ConnectVerbund_UseCase1), 181=Cxb5_ConnectVerbund_UseCase6 (CM_NM_Gateway_Wakeup_V12_Cxb5_ConnectVerbund_UseCase6), 178=Cxb2_ConnectVerbund_UseCase3 (CM_NM_Gateway_Wakeup_V12_Cxb2_ConnectVerbund_UseCase3), 180=Cxb4_ConnectVerbund_UseCase5 (CM_NM_Gateway_Wakeup_V12_Cxb4_ConnectVerbund_UseCase5), 179=Cxb3_ConnectVerbund_UseCase4 (CM_NM_Gateway_Wakeup_V12_Cxb3_ConnectVerbund_UseCase4), 177=Cxb1_ConnectVerbund_UseCase2 (CM_NM_Gateway_Wakeup_V12_Cxb1_ConnectVerbund_UseCase2)}, range raw 0..181, transfer-property=TRIGGERED  # enthält die Weckursache; stehen mehrere Weckursachen parallel an, dann muss der kleinste Wert übertragen werden
          signal NM_Gateway_NM_aktiv_KL15_XIX_NM_Gateway_XIX_WU_HCP3_CANFD: start 160, 1 bit, little-endian, data-type-policy=OVERRIDE, i-signal-type=PRIMITIVE, init-value=0, base-type=BT_NM_Gateway_NM_aktiv_KL15, compu {0=Cx0_Inaktiv (CM_NM_Gateway_NM_aktiv_KL15_Cx0_Inaktiv), 1=Cx1_KL15_EIN (CM_NM_Gateway_NM_aktiv_KL15_Cx1_KL15_EIN)}, range raw 0..1, transfer-property=TRIGGERED  # Steuergerät hat KL15-EIN erkannt
          signal NM_Gateway_NM_aktiv_Diag_XIX_NM_Gateway_XIX_WU_HCP3_CANFD: start 161, 1 bit, little-endian, data-type-policy=OVERRIDE, i-signal-type=PRIMITIVE, init-value=0, base-type=BT_NM_Gateway_NM_aktiv_Diag, compu {1=Cx1_Diagnose_aktiv (CM_NM_Gateway_NM_aktiv_Diag_Cx1_Diagnose_aktiv), 0=Cx0_Inaktiv (CM_NM_Gateway_NM_aktiv_Diag_Cx0_Inaktiv)}, range raw 0..1, transfer-property=TRIGGERED  # Diagnose befindet sich nach VW80124 in einer NonDefaultDiagnostic-Session, z.B. ExtendedDiagnostic-Session
          signal NM_Gateway_NM_aktiv_Tmin_XIX_NM_Gateway_XIX_WU_HCP3_CANFD: start 162, 1 bit, little-endian, data-type-policy=OVERRIDE, i-signal-type=PRIMITIVE, init-value=0, base-type=BT_NM_Gateway_NM_aktiv_Tmin, compu {1=Cx1_Mindestaktivzeit (CM_NM_Gateway_NM_aktiv_Tmin_Cx1_Mindestaktivzeit), 0=Cx0_Inaktiv (CM_NM_Gateway_NM_aktiv_Tmin_Cx0_Inaktiv)}, range raw 0..1, transfer-property=TRIGGERED  # Mindestaktivzeit ist noch nicht abgelaufen (bei jedem Weckereignis wird die Mindestaktivzeit neu gestartet)
          signal NM_Gateway_NM_aktiv_CABaktiv_XIX_NM_Gateway_XIX_WU_HCP3_CANFD: start 163, 1 bit, little-endian, data-type-policy=OVERRIDE, i-signal-type=PRIMITIVE, init-value=0, base-type=BT_NM_Gateway_NM_aktiv_CABaktiv, compu {1=Cx1_Cluster_Min_Req_TimeOfVNSM (CM_NM_Gateway_NM_aktiv_CABaktiv_Cx1_Cluster_Min_Req_TimeOfVNSM), 0=Cx0_Inaktiv (CM_NM_Gateway_NM_aktiv_CABaktiv_Cx0_Inaktiv)}, range raw 0..1, transfer-property=TRIGGERED  # Nachlauf aufgrund Funktionscluster Anforderung
          signal NM_aktiv_Gefahreninfo_XIX_NM_Gateway_XIX_WU_HCP3_CANFD: start 164, 1 bit, little-endian, data-type-policy=OVERRIDE, i-signal-type=PRIMITIVE, init-value=0, base-type=BT_NM_aktiv_Gefahreninfo, compu {1=Cx1_aktiv (CM_NM_aktiv_Gefahreninfo_Cx1_aktiv), 0=Cx0_inaktiv (CM_NM_aktiv_Gefahreninfo_Cx0_inaktiv)}, range raw 0..1, transfer-property=TRIGGERED  # Nach dem Ausschalten der Zündung soll eine Veränderung der Position des FZGs, bzw. eine Bewegung des FZGs erkannt werden und ein zuvor detektiertes Pannen oder Unfall Event gecanncelt werden. Das versenden des Cancel-Events ans Backend muss noch sichergestellt sein. Allerdings tritt der Fall nur auf, wenn davor ein Unfall oder eine Panne detektiert wurde, also sehr selten.
          signal NM_aktiv_MVEM_Pos_RSG_XIX_NM_Gateway_XIX_WU_HCP3_CANFD: start 165, 1 bit, little-endian, data-type-policy=OVERRIDE, i-signal-type=PRIMITIVE, init-value=0, base-type=BT_NM_aktiv_MVEM_Pos_RSG, compu {0=Cx0_Inaktiv (CM_NM_aktiv_MVEM_Pos_RSG_Cx0_Inaktiv), 1=Cx1_Aktiv (CM_NM_aktiv_MVEM_Pos_RSG_Cx1_Aktiv)}, range raw 0..1, transfer-property=TRIGGERED  # Nach Ausschalten der Kl.15 soll der HCP5 noch für eine gewisse Zeit wachgehalten werden für Stalling Help/Positionierung vom RSG .
          signal NM_aktiv_Timer_abgelaufen_XIX_NM_Gateway_XIX_WU_HCP3_CANFD: start 166, 1 bit, little-endian, data-type-policy=OVERRIDE, i-signal-type=PRIMITIVE, init-value=0, base-type=BT_NM_aktiv_Timer_abgelaufen, compu {0=Cx0_Inaktiv (CM_NM_aktiv_Timer_abgelaufen_Cx0_Inaktiv), 1=Cx1_Aktiv (CM_NM_aktiv_Timer_abgelaufen_Cx1_Aktiv)}, range raw 0..1, transfer-property=TRIGGERED  # Timer des Basisdienst Zeitmaster::Timemaster_OBD hat ausgelöst
          signal NM_aktiv_Batteriekonditionierung_XIX_NM_Gateway_XIX_WU_HCP3_CANFD: start 167, 1 bit, little-endian, data-type-policy=OVERRIDE, i-signal-type=PRIMITIVE, init-value=0, base-type=BT_NM_aktiv_Batteriekonditionierung, compu {1=Cx1_Aktiv (CM_NM_aktiv_Batteriekonditionierung_Cx1_Aktiv), 0=Cx0_Inaktiv (CM_NM_aktiv_Batteriekonditionierung_Cx0_Inaktiv)}, range raw 0..1, transfer-property=TRIGGERED  # Zur Reduzierung der Ladezeit, Steigerung der Abfahrtsperfomance und Erhöhung der Reichweite durch Nutzung der HV-Batterie als Wärmequelle muss die HV-Batterie in einen Temperaturbereich konditioniert werden. Das prädiktive Thermomanagement ermittelt mittels Ladeplanung bzw. Abfahrtimer die notwendige Konditionierungsdauer und stellt in der Timerverwaltung einen Weckevorgang ein.
          signal NM_aktiv_HV_Laden_XIX_NM_Gateway_XIX_WU_HCP3_CANFD: start 168, 1 bit, little-endian, data-type-policy=OVERRIDE, i-signal-type=PRIMITIVE, init-value=0, base-type=BT_NM_aktiv_HV_Laden, compu {1=Cx1_Aktiv (CM_NM_aktiv_HV_Laden_Cx1_Aktiv), 0=Cx0_Inaktiv (CM_NM_aktiv_HV_Laden_Cx0_Inaktiv)}, range raw 0..1, transfer-property=TRIGGERED  # CMS-SWC fordert AC/DC-Laden
          signal NM_aktiv_Backend_KomGW_XIX_NM_Gateway_XIX_WU_HCP3_CANFD: start 169, 1 bit, little-endian, data-type-policy=OVERRIDE, i-signal-type=PRIMITIVE, init-value=0, base-type=BT_NM_aktiv_Backend_KomGW, compu {1=Cx1_Aktiv (CM_NM_aktiv_Backend_KomGW_Cx1_Aktiv), 0=Cx0_Inaktiv (CM_NM_aktiv_Backend_KomGW_Cx0_Inaktiv)}, range raw 0..1, transfer-property=TRIGGERED  # Der Nachlauf wird benötigt um eine Online Kommunikation zwischen dem Fahrzeug und dem Backend zu ermöglichen.
          signal NM_aktiv_Erw_HV_Ladefunktion_XIX_NM_Gateway_XIX_WU_HCP3_CANFD: start 170, 1 bit, little-endian, data-type-policy=OVERRIDE, i-signal-type=PRIMITIVE, init-value=0, base-type=BT_NM_aktiv_Erw_HV_Ladefunktion, compu {0=Cx0_Inaktiv (CM_NM_aktiv_Erw_HV_Ladefunktion_Cx0_Inaktiv), 1=Cx1_Aktiv (CM_NM_aktiv_Erw_HV_Ladefunktion_Cx1_Aktiv)}, range raw 0..1, transfer-property=TRIGGERED  # Anhand von Eingaben durch den Kunden wie z.b. einer Abfahrtszeit oder aufgrund von Preisleistungsinformationen werden Ladepläne berechnet und Zeitversetzt ggf. mit Unterbrechungen geladen.
          signal NM_aktiv_E3_SW_Plattform_1_XIX_NM_Gateway_XIX_WU_HCP3_CANFD: start 171, 1 bit, little-endian, data-type-policy=OVERRIDE, i-signal-type=PRIMITIVE, init-value=0, base-type=BT_NM_aktiv_E3_SW_Plattform_1, compu {1=Cx1_Aktiv (CM_NM_aktiv_E3_SW_Plattform_1_Cx1_Aktiv), 0=Cx0_Inaktiv (CM_NM_aktiv_E3_SW_Plattform_1_Cx0_Inaktiv)}, range raw 0..1, transfer-property=TRIGGERED  # Busaktivität wird durch Applikation 1 auf der E3 SW Plattform angefordert
          signal NM_aktiv_E3_SW_Plattform_2_XIX_NM_Gateway_XIX_WU_HCP3_CANFD: start 172, 1 bit, little-endian, data-type-policy=OVERRIDE, i-signal-type=PRIMITIVE, init-value=0, base-type=BT_NM_aktiv_E3_SW_Plattform_2, compu {0=Cx0_Inaktiv (CM_NM_aktiv_E3_SW_Plattform_2_Cx0_Inaktiv), 1=Cx1_Aktiv (CM_NM_aktiv_E3_SW_Plattform_2_Cx1_Aktiv)}, range raw 0..1, transfer-property=TRIGGERED  # Busaktivität wird durch Applikation 2 auf der E3 SW Plattform angefordert
          signal NM_aktiv_E3_SW_Plattform_3_XIX_NM_Gateway_XIX_WU_HCP3_CANFD: start 173, 1 bit, little-endian, data-type-policy=OVERRIDE, i-signal-type=PRIMITIVE, init-value=0, base-type=BT_NM_aktiv_E3_SW_Plattform_3, compu {0=Cx0_Inaktiv (CM_NM_aktiv_E3_SW_Plattform_3_Cx0_Inaktiv), 1=Cx1_Aktiv (CM_NM_aktiv_E3_SW_Plattform_3_Cx1_Aktiv)}, range raw 0..1, transfer-property=TRIGGERED  # Busaktivität wird durch Applikation 3 auf der E3 SW Plattform angefordert
          signal NM_aktiv_E3_SW_Plattform_4_XIX_NM_Gateway_XIX_WU_HCP3_CANFD: start 174, 1 bit, little-endian, data-type-policy=OVERRIDE, i-signal-type=PRIMITIVE, init-value=0, base-type=BT_NM_aktiv_E3_SW_Plattform_4, compu {0=Cx0_Inaktiv (CM_NM_aktiv_E3_SW_Plattform_4_Cx0_Inaktiv), 1=Cx1_Aktiv (CM_NM_aktiv_E3_SW_Plattform_4_Cx1_Aktiv)}, range raw 0..1, transfer-property=TRIGGERED  # Busaktivität wird durch Applikation 4 auf der E3 SW Plattform angefordert
          signal NM_aktiv_E3_SW_Plattform_5_XIX_NM_Gateway_XIX_WU_HCP3_CANFD: start 175, 1 bit, little-endian, data-type-policy=OVERRIDE, i-signal-type=PRIMITIVE, init-value=0, base-type=BT_NM_aktiv_E3_SW_Plattform_5, compu {1=Cx1_Aktiv (CM_NM_aktiv_E3_SW_Plattform_5_Cx1_Aktiv), 0=Cx0_Inaktiv (CM_NM_aktiv_E3_SW_Plattform_5_Cx0_Inaktiv)}, range raw 0..1, transfer-property=TRIGGERED  # Busaktivität wird durch Applikation 5 auf der E3 SW Plattform angefordert
          signal NM_aktiv_Key_Authentifiz_SMS_XIX_NM_Gateway_XIX_WU_HCP3_CANFD: start 176, 1 bit, little-endian, data-type-policy=OVERRIDE, i-signal-type=PRIMITIVE, init-value=0, base-type=BT_NM_aktiv_Key_Authentifiz_SMS, compu {0=Cx0_Inaktiv (CM_NM_aktiv_Key_Authentifiz_SMS_Cx0_Inaktiv), 1=Cx1_Aktiv (CM_NM_aktiv_Key_Authentifiz_SMS_Cx1_Aktiv)}, range raw 0..1, transfer-property=TRIGGERED  # Im Rahmen der Funktion MDK 2.0 müssen zu bestimmten Zeitpunkten Daten mit dem Backend ausgetauscht werden, um z.B. digitale Schlüssel im Fahrzeug zu löschen oder Zertifikate und Konfigurationsdaten zu aktualisieren
          signal NM_aktiv_HVK_XIX_NM_Gateway_XIX_WU_HCP3_CANFD: start 177, 1 bit, little-endian, data-type-policy=OVERRIDE, i-signal-type=PRIMITIVE, init-value=0, base-type=BT_NM_aktiv_HVK, compu {0=Cx0_Inaktiv (CM_NM_aktiv_HVK_Cx0_Inaktiv), 1=Cx1_Aktiv (CM_NM_aktiv_HVK_Cx1_Aktiv)}, range raw 0..1, transfer-property=TRIGGERED  # Der HV-Koordinator stellt den Fahrzeugfunktionen ein aktives HV-System im benötigten Betriebszustand zur Verfügung. Da es insbesondere für HV-Laden und für die Vorkonditionierung HV-Betriebszustände ohne KL15 Ein gibt, muss der Hochvolt-Koordinator benötigte Funktionen und HV-Komponenten aktiv anfordern.
          signal NM_aktiv_HVLM_XIX_NM_Gateway_XIX_WU_HCP3_CANFD: start 178, 1 bit, little-endian, data-type-policy=OVERRIDE, i-signal-type=PRIMITIVE, init-value=0, base-type=BT_NM_aktiv_HVLM, compu {0=Cx0_Inaktiv (CM_NM_aktiv_HVLM_Cx0_Inaktiv), 1=Cx1_Aktiv (CM_NM_aktiv_HVLM_Cx1_Aktiv)}, range raw 0..1, transfer-property=TRIGGERED  # HV-Lademanager bzw CMS-SWC fordert AC/DC-Laden
          signal NM_aktiv_NVEM_XIX_NM_Gateway_XIX_WU_HCP3_CANFD: start 179, 1 bit, little-endian, data-type-policy=OVERRIDE, i-signal-type=PRIMITIVE, init-value=0, base-type=BT_NM_aktiv_NVEM, compu {1=Cx1_Aktiv (CM_NM_aktiv_NVEM_Cx1_Aktiv), 0=Cx0_Inaktiv (CM_NM_aktiv_NVEM_Cx0_Inaktiv)}, range raw 0..1, transfer-property=TRIGGERED  # Niedervolt-Energiemanagement startet bei Unterschreitung eines bestimmten Ladungsinhalts der Niedervoltbatteri selbstständig den Nachlade-Prozess.
          signal NM_aktiv_OnlineRemoteUpdate_XIX_NM_Gateway_XIX_WU_HCP3_CANFD: start 180, 1 bit, little-endian, data-type-policy=OVERRIDE, i-signal-type=PRIMITIVE, init-value=0, base-type=BT_NM_aktiv_OnlineRemoteUpdate, compu {1=Cx1_Aktiv (CM_NM_aktiv_OnlineRemoteUpdate_Cx1_Aktiv), 0=Cx0_Inaktiv (CM_NM_aktiv_OnlineRemoteUpdate_Cx0_Inaktiv)}, range raw 0..1, transfer-property=TRIGGERED  # Im ORU Fall muss nach Kundenzustimmung des Updates geweckt wecken, um Vorbedinungungen für das Update zu prüfen sowie die Verbindung zu den betroffenen Steuergeräten aufzubauen und aufrechtzuerhalten.
          signal NM_aktiv_RemoteDiensteGW_XIX_NM_Gateway_XIX_WU_HCP3_CANFD: start 181, 1 bit, little-endian, data-type-policy=OVERRIDE, i-signal-type=PRIMITIVE, init-value=0, base-type=BT_NM_aktiv_RemoteDiensteGW, compu {1=Cx1_Aktiv (CM_NM_aktiv_RemoteDiensteGW_Cx1_Aktiv), 0=Cx0_Inaktiv (CM_NM_aktiv_RemoteDiensteGW_Cx0_Inaktiv)}, range raw 0..1, transfer-property=TRIGGERED  # Das Fahrzeug wird bei einem Smart-Phone-App Aufruf über die ConMod für einen Job geweckt. Der empfangene Job wird an das BCM bzw TME gesendet, welche die weiteren Services anbieten.
          signal NM_aktiv_SubbusSteuerung_HCP5_XIX_NM_Gateway_XIX_WU_HCP3_CANFD: start 182, 1 bit, little-endian, data-type-policy=OVERRIDE, i-signal-type=PRIMITIVE, init-value=0, base-type=BT_NM_aktiv_SubbusSteuerung_HCP5, compu {0=Cx0_Inaktiv (CM_NM_aktiv_SubbusSteuerung_HCP5_Cx0_Inaktiv), 1=Cx1_Aktiv (CM_NM_aktiv_SubbusSteuerung_HCP5_Cx1_Aktiv)}, range raw 0..1, transfer-property=TRIGGERED  # Steuerung des MFL_CAN sowie der Ethernet-Links HCP5_MFK_ETH, HCP5_MRR_ETH und HCP5_xView_ETH
          signal NM_aktiv_VehicleStatReport_Main_XIX_NM_Gateway_XIX_WU_HCP3_CANFD: start 183, 1 bit, little-endian, data-type-policy=OVERRIDE, i-signal-type=PRIMITIVE, init-value=0, base-type=BT_NM_aktiv_VehicleStatReport_Main, compu {1=Cx1_Aktiv (CM_NM_aktiv_VehicleStatReport_Main_Cx1_Aktiv), 0=Cx0_Inaktiv (CM_NM_aktiv_VehicleStatReport_Main_Cx0_Inaktiv)}, range raw 0..1, transfer-property=TRIGGERED  # Die Funktion zeigt Daten wie Türen und Fensterstatus oder Reichweiten in der App oder dem Portal an.
          signal NM_aktiv_Remote_Unlock_Lock_XIX_NM_Gateway_XIX_WU_HCP3_CANFD: start 184, 1 bit, little-endian, data-type-policy=OVERRIDE, i-signal-type=PRIMITIVE, init-value=0, base-type=BT_NM_aktiv_Remote_Unlock_Lock, compu {1=Cx1_Aktiv (CM_NM_aktiv_Remote_Unlock_Lock_Cx1_Aktiv), 0=Cx0_Inaktiv (CM_NM_aktiv_Remote_Unlock_Lock_Cx0_Inaktiv)}, range raw 0..1, transfer-property=TRIGGERED  # Über Smartphone App kann Nutzer ferngesteuert die Türen ver- und entriegeln: Fahrzeug wird für einen solchen Job geweckt über Online-Verbindung (conMod > HCP5; abgedeckt durch CoreServices Wakeup 85.3); empfangener Job wird von HCP5 an HCP4 gesendet (dieser Weck-/ Nachlaufgrund); HCP4 führt die Lock/Unlock Funktionalität dann aus, braucht dazu Backend-Kommunikation (HCP5 + ConMod), Türsteuergeräte, Zentralverriegelung und Powertrain (HCP1 + Gearbox) (weiterer Antrag/ Update von 67.2 )
          signal NM_aktiv_HVEM_XIX_NM_Gateway_XIX_WU_HCP3_CANFD: start 185, 1 bit, little-endian, data-type-policy=OVERRIDE, i-signal-type=PRIMITIVE, init-value=0, base-type=BT_NM_aktiv_HVEM, compu {0=Cx0_Inaktiv (CM_NM_aktiv_HVEM_Cx0_Inaktiv), 1=Cx1_Aktiv (CM_NM_aktiv_HVEM_Cx1_Aktiv)}, range raw 0..1, transfer-property=TRIGGERED  # Das Hochvolt-Energiemanagement (HVEM) ist für die Verteilung von Leistung und Energie in allen Betriebszuständen im HV-System zuständig.
          signal NM_aktiv_Call_XIX_NM_Gateway_XIX_WU_HCP3_CANFD: start 186, 1 bit, little-endian, data-type-policy=OVERRIDE, i-signal-type=PRIMITIVE, init-value=0, base-type=BT_NM_aktiv_Call, compu {0=Cx0_Inaktiv (CM_NM_aktiv_Call_Cx0_Inaktiv), 1=Cx1_Aktiv (CM_NM_aktiv_Call_Cx1_Aktiv)}, range raw 0..1, transfer-property=TRIGGERED  # Wird ein eCall oder Online Pannenruf durchgeführt und ist der Anruf zum Notruf oder Pannenruf Callcenter bereits aufgebaut, darf beim Ausschalten der KL15 der HCP3, ConMod und HCP5 nicht schlafen gehen
          signal NM_aktiv_RemoteStart_XIX_NM_Gateway_XIX_WU_HCP3_CANFD: start 187, 1 bit, little-endian, data-type-policy=OVERRIDE, i-signal-type=PRIMITIVE, init-value=0, base-type=BT_NM_aktiv_RemoteStart, compu {0=Cx0_Inaktiv (CM_NM_aktiv_RemoteStart_Cx0_Inaktiv), 1=Cx1_Aktiv (CM_NM_aktiv_RemoteStart_Cx1_Aktiv)}, range raw 0..1, transfer-property=TRIGGERED  # Zur Ausführung des Remote Motorstarts wird über den MOD eine Aktivierung durch den Fahrzeughalter über Smartphone getriggert
          signal NM_aktiv_Ladezustand_XIX_NM_Gateway_XIX_WU_HCP3_CANFD: start 188, 1 bit, little-endian, data-type-policy=OVERRIDE, i-signal-type=PRIMITIVE, init-value=0, base-type=BT_NM_aktiv_Ladezustand, compu {1=Cx1_Aktiv (CM_NM_aktiv_Ladezustand_Cx1_Aktiv), 0=Cx0_Inaktiv (CM_NM_aktiv_Ladezustand_Cx0_Inaktiv)}, range raw 0..1, transfer-property=TRIGGERED  # Über die App kann der Nutzer ferngesteuert zwischen Sofort und Zeitversetzten Laden wechseln. Weiterhin sendet das Fahrzeug wärend aktivem Ladevorgang zyklisch Updates zum Ladeverlauf.
          signal NM_aktiv_RemoteVehicleTracking_XIX_NM_Gateway_XIX_WU_HCP3_CANFD: start 189, 1 bit, little-endian, data-type-policy=OVERRIDE, i-signal-type=PRIMITIVE, init-value=0, base-type=BT_NM_aktiv_RemoteVehicleTracking, compu {1=Cx1_Aktiv (CM_NM_aktiv_RemoteVehicleTracking_Cx1_Aktiv), 0=Cx0_Inaktiv (CM_NM_aktiv_RemoteVehicleTracking_Cx0_Inaktiv)}, range raw 0..1, transfer-property=TRIGGERED  # Der RVT ist ein Diebstahlschutz, der remote das gestohlene Fahrzeug von einem Callcenter tracken kann. Dazu muss der Bus aufgeweckt werden.
          signal NM_aktiv_WarnblinkerInfo_XIX_NM_Gateway_XIX_WU_HCP3_CANFD: start 190, 1 bit, little-endian, data-type-policy=OVERRIDE, i-signal-type=PRIMITIVE, init-value=0, base-type=BT_NM_aktiv_WarnblinkerInfo, compu {0=Cx0_Inaktiv (CM_NM_aktiv_WarnblinkerInfo_Cx0_Inaktiv), 1=Cx1_Aktiv (CM_NM_aktiv_WarnblinkerInfo_Cx1_Aktiv)}, range raw 0..1, transfer-property=TRIGGERED  # - Der chinesische LTE-V2X Standard erfordert BSM Nachrichten. Das "Vehicle event flag" ist ein verpflichtender Teil dieser BSM Nachricht. Da die ConMod das nicht befüllen kann, soll diese SWC "LHWSenderChinaVehicleEventFlags" die Berechnung dieser Vehicle Event Flags übernehmen. Die Zusammensetzung und das Aussenden der vollständigen BSM-Nachrichten erfolgt nachgehend in der ConMod. - Eines dieser Vehicle Event Flags beschreibt das Verhalten bei aktiviertem Warnblinker. Ist der Warnblinker aktiviert sollen BSMs mit entsprechenden event flags auch bei inaktiver Klemme15 versendet werden. Hierfür ist ein Wecken der ConMod notwendig.
          signal NM_aktiv_NVEM2_XIX_NM_Gateway_XIX_WU_HCP3_CANFD: start 191, 1 bit, little-endian, data-type-policy=OVERRIDE, i-signal-type=PRIMITIVE, init-value=0, base-type=BT_NM_aktiv_NVEM2, compu {1=Cx1_Aktiv (CM_NM_aktiv_NVEM2_Cx1_Aktiv), 0=Cx0_Inaktiv (CM_NM_aktiv_NVEM2_Cx0_Inaktiv)}, range raw 0..1, transfer-property=TRIGGERED  # Niedervoltenergiemanagement 2 zur Sicherstellung der Versorgung sicherheitsrelevanter Verbraucher.
      frame NM_Info_El_XIX_WU_HCP3_CANFD: id 0x1B000073, from HCP3_IONode, frame-length=24, can-addressing-mode=EXTENDED, can-frame-rx-behavior=CAN-FD, can-frame-tx-behavior=CAN-FD, rx-identifier-range={lower-can-id=452984832, upper-can-id=452985855}
        nm pdu NM_Info_El_XIX_WU_HCP3_CANFD: length=24, unused-bit-pattern=0
          signal NM_Info_El_CBV_AWB_XIX_NM_Info_El_XIX_WU_HCP3_CANFD: start 4, 1 bit, little-endian, data-type-policy=OVERRIDE, i-signal-type=PRIMITIVE, init-value=0, base-type=BT_NM_Info_El_CBV_AWB, compu {1=Cx1_Aktiver_WakeUp (CM_NM_Info_El_CBV_AWB_Cx1_Aktiver_WakeUp), 0=Cx0_Passiver_WakeUp (CM_NM_Info_El_CBV_AWB_Cx0_Passiver_WakeUp)}, range raw 0..1, transfer-property=TRIGGERED  # Das Signal ist zu setzen, wenn das SG aktiv den Bus geweckt hat 0 = Passiver_WakeUp = SG hat das Netzwerk nicht aktiv geweckt 1 = Akitiver_WakeUp = SG hat das Netzwerk aktiv geweckt
          signal NM_Info_El_CBV_CRI_XIX_NM_Info_El_XIX_WU_HCP3_CANFD: start 6, 1 bit, little-endian, data-type-policy=OVERRIDE, i-signal-type=PRIMITIVE, init-value=1, base-type=BT_NM_Info_El_CBV_CRI, compu {0=Cx0_NM_ohne_Clusteranforderungen (CM_NM_Info_El_CBV_CRI_Cx0_NM_ohne_Clusteranforderungen), 1=Cx1_NM_mit_Clusteranforderungen (CM_NM_Info_El_CBV_CRI_Cx1_NM_mit_Clusteranforderungen)}, range raw 0..1, transfer-property=TRIGGERED  # Das Signal ist dauerhaft gesetzt, wenn das NM-Layout Cluster- Anforderungen enthält
          signal NM_Info_El_FCAB_XIX_NM_Info_El_XIX_WU_HCP3_CANFD: start 8, 56 bit, opaque, data-type-policy=OVERRIDE, i-signal-type=ARRAY, init-value=7 x 0b00000000, base-type=BT_NM_Info_El_FCAB, compu {34359738368=Cx800000000_36_Preheater (CM_NM_Info_El_FCAB_Cx800000000_36_Preheater), 131072=Cx20000_18_VirtualSideMirrors (CM_NM_Info_El_FCAB_Cx20000_18_VirtualSideMirrors), 140737488355328=Cx800000000000_48_Diagnosis_ClimateTmeLINs (CM_NM_Info_El_FCAB_Cx800000000000_48_Diagnosis_ClimateTmeLINs), 36028797018963968=Cx80000000000000_56_ChargingStatus (CM_NM_Info_El_FCAB_Cx80000000000000_56_ChargingStatus), 549755813888=Cx8000000000_40_Diagnosis_Energy (CM_NM_Info_El_FCAB_Cx8000000000_40_Diagnosis_Energy), 134217728=Cx8000000_28_OnboardTester_DataCollector (CM_NM_Info_El_FCAB_Cx8000000_28_OnboardTester_DataCollector), 18014398509481984=Cx40000000000000_55_Dimming (CM_NM_Info_El_FCAB_Cx40000000000000_55_Dimming), 1024=Cx400_11_Chassis (CM_NM_Info_El_FCAB_Cx400_11_Chassis), 9007199254740992=Cx20000000000000_54_reserved (CM_NM_Info_El_FCAB_Cx20000000000000_54_reserved) (54_<reserved>), 2=Cx2_02_Basefunction_Powertrain (CM_NM_Info_El_FCAB_Cx2_02_Basefunction_Powertrain), 17592186044416=Cx100000000000_45_Diagnosis_Comfort (CM_NM_Info_El_FCAB_Cx100000000000_45_Diagnosis_Comfort), 262144=Cx40000_19_Doors_Hatches (CM_NM_Info_El_FCAB_Cx40000_19_Doors_Hatches), 16384=Cx4000_15_InstrumentclusterDisplay (CM_NM_Info_El_FCAB_Cx4000_15_InstrumentclusterDisplay), 70368744177664=Cx400000000000_47_Diagnosis_ComfortLINs (CM_NM_Info_El_FCAB_Cx400000000000_47_Diagnosis_ComfortLINs), 8=Cx8_04_Basefunction_DrivingAssistance (CM_NM_Info_El_FCAB_Cx8_04_Basefunction_DrivingAssistance), 2048=Cx800_12_GearSelector (CM_NM_Info_El_FCAB_Cx800_12_GearSelector), 65536=Cx10000_17_Audio (CM_NM_Info_El_FCAB_Cx10000_17_Audio), 68719476736=Cx1000000000_37_HighVoltage_WirelessChargingStation (CM_NM_Info_El_FCAB_Cx1000000000_37_HighVoltage_WirelessChargingStation), 128=Cx80_08_Basefunction_Connectivity (CM_NM_Info_El_FCAB_Cx80_08_Basefunction_Connectivity), 1=Cx1_01_CarWakeUp (CM_NM_Info_El_FCAB_Cx1_01_CarWakeUp), 536870912=Cx20000000_30_EnergyManagement (CM_NM_Info_El_FCAB_Cx20000000_30_EnergyManagement), 2199023255552=Cx20000000000_42_Diagnosis_FlexRay (CM_NM_Info_El_FCAB_Cx20000000000_42_Diagnosis_FlexRay), 524288=Cx80000_20_OptionalComfort (CM_NM_Info_El_FCAB_Cx80000_20_OptionalComfort), 67108864=Cx4000000_27_Timemaster_Timer (CM_NM_Info_El_FCAB_Cx4000000_27_Timemaster_Timer), 512=Cx200_10_Powertrain (CM_NM_Info_El_FCAB_Cx200_10_Powertrain), 35184372088832=Cx200000000000_46_Diagnosis_Light (CM_NM_Info_El_FCAB_Cx200000000000_46_Diagnosis_Light), 8796093022208=Cx80000000000_44_Diagnosis_Infotainment (CM_NM_Info_El_FCAB_Cx80000000000_44_Diagnosis_Infotainment), 0=Cx0_Init (CM_NM_Info_El_FCAB_Cx0_Init), 8388608=Cx800000_24_ThermoManagement (CM_NM_Info_El_FCAB_Cx800000_24_ThermoManagement), 268435456=Cx10000000_29_SteeringColumnLock (CM_NM_Info_El_FCAB_Cx10000000_29_SteeringColumnLock), 17179869184=Cx400000000_35_ExteriorSound (CM_NM_Info_El_FCAB_Cx400000000_35_ExteriorSound), 32=Cx20_06_Basefunction_ComfortLight (CM_NM_Info_El_FCAB_Cx20_06_Basefunction_ComfortLight), 4503599627370496=Cx10000000000000_53_Lock_Unlock (CM_NM_Info_El_FCAB_Cx10000000000000_53_Lock_Unlock), 8192=Cx2000_14_InfotainmentExtensions (CM_NM_Info_El_FCAB_Cx2000_14_InfotainmentExtensions), 2147483648=Cx80000000_32_OnlineAccess (CM_NM_Info_El_FCAB_Cx80000000_32_OnlineAccess), 64=Cx40_07_Basefunction_CrossSection (CM_NM_Info_El_FCAB_Cx40_07_Basefunction_CrossSection), 16=Cx10_05_Basefunction_Infotainment (CM_NM_Info_El_FCAB_Cx10_05_Basefunction_Infotainment), 1073741824=Cx40000000_31_MultifunctionalSteeringWheel (CM_NM_Info_El_FCAB_Cx40000000_31_MultifunctionalSteeringWheel), 16777216=Cx1000000_25_AccessSystemSensors (CM_NM_Info_El_FCAB_Cx1000000_25_AccessSystemSensors), 8589934592=Cx200000000_34_GPS_Localization (CM_NM_Info_El_FCAB_Cx200000000_34_GPS_Localization), 1048576=Cx100000_21_AirSuspension (CM_NM_Info_El_FCAB_Cx100000_21_AirSuspension), 1099511627776=Cx10000000000_41_Diagnosis_Powertrain (CM_NM_Info_El_FCAB_Cx10000000000_41_Diagnosis_Powertrain), 4194304=Cx400000_23_Climate (CM_NM_Info_El_FCAB_Cx400000_23_Climate), 4294967296=Cx100000000_33_ExternalWirelessCommunication (CM_NM_Info_El_FCAB_Cx100000000_33_ExternalWirelessCommunication), 32768=Cx8000_16_InfotainmentDisplay (CM_NM_Info_El_FCAB_Cx8000_16_InfotainmentDisplay), 4=Cx4_03_Basefunction_Chassis (CM_NM_Info_El_FCAB_Cx4_03_Basefunction_Chassis), 2097152=Cx200000_22_ExteriorLights (CM_NM_Info_El_FCAB_Cx200000_22_ExteriorLights), 256=Cx100_09_reserved (CM_NM_Info_El_FCAB_Cx100_09_reserved) (09_<reserved>), 33554432=Cx2000000_26_HighVoltage_Charging (CM_NM_Info_El_FCAB_Cx2000000_26_HighVoltage_Charging), 4096=Cx1000_13_Airbag (CM_NM_Info_El_FCAB_Cx1000_13_Airbag), 4398046511104=Cx40000000000_43_Diagnosis_DrivingAssistance (CM_NM_Info_El_FCAB_Cx40000000000_43_Diagnosis_DrivingAssistance), 281474976710656=Cx1000000000000_49_reserved (CM_NM_Info_El_FCAB_Cx1000000000000_49_reserved) (49_<reserved>)}, range raw 0..36028797018963968, transfer-property=TRIGGERED-ON-CHANGE  # FCAB = Funktions-Cluster-Aktiv-Bits
          signal NM_Info_El_SNI_10_XIX_NM_Info_El_XIX_WU_HCP3_CANFD: start 128, 10 bit, little-endian, data-type-policy=OVERRIDE, i-signal-type=PRIMITIVE, init-value=115, base-type=BT_NM_Info_El_SNI_10, compu {115=Cx73_Info_El_SNI (CM_NM_Info_El_SNI_10_Cx73_Info_El_SNI)}, range raw 115, transfer-property=TRIGGERED  # Source Node-Identifier (SNI) identifiziert den Sender der NM-Botschaft (Knotenadresse) eindeutig im Fahrzeug
          signal NM_Info_El_NM_State_XIX_NM_Info_El_XIX_WU_HCP3_CANFD: start 144, 6 bit, little-endian, data-type-policy=OVERRIDE, i-signal-type=PRIMITIVE, init-value=0, base-type=BT_NM_Info_El_NM_State, compu {8=Cx8_NM_NO_aus_RS (CM_NM_Info_El_NM_State_Cx8_NM_NO_aus_RS), 2=Cx2_NM_RM_aus_PBSM (CM_NM_Info_El_NM_State_Cx2_NM_RM_aus_PBSM), 0=Cx0_Init (CM_NM_Info_El_NM_State_Cx0_Init), 4=Cx4_NM_NO_aus_RM (CM_NM_Info_El_NM_State_Cx4_NM_NO_aus_RM), 32=Cx20_reserved (CM_NM_Info_El_NM_State_Cx20_reserved), 1=Cx1_NM_RM_aus_BSM (CM_NM_Info_El_NM_State_Cx1_NM_RM_aus_BSM), 16=Cx10_reserved (CM_NM_Info_El_NM_State_Cx10_reserved)}, range raw 0..32, transfer-property=TRIGGERED  # 1 = Zustand Repeat Message (<-- Bus-Sleep Mode) 2 = Zustand Repeat Message (<-- Prepare Bus-Sleep Mode) 4 = Zustand Normal Operation (<-- Repeat Message) 8 = Zustand Normal Operation (<-- Ready Sleep)
          signal NM_Info_El_UDS_CC_XIX_NM_Info_El_XIX_WU_HCP3_CANFD: start 151, 1 bit, little-endian, data-type-policy=OVERRIDE, i-signal-type=PRIMITIVE, init-value=0, base-type=BT_NM_Info_El_UDS_CC, compu {0=Cx0_Inaktiv (CM_NM_Info_El_UDS_CC_Cx0_Inaktiv), 1=Cx1_CC_aktiv (CM_NM_Info_El_UDS_CC_Cx1_CC_aktiv)}, range raw 0..1, transfer-property=TRIGGERED  # Funktionseinschränkung aufgrund aktivem UDS-Communication Control, siehe VW80124
          signal NM_Info_El_Wakeup_V12_XIX_NM_Info_El_XIX_WU_HCP3_CANFD: start 152, 8 bit, little-endian, data-type-policy=OVERRIDE, i-signal-type=PRIMITIVE, init-value=0, base-type=BT_NM_Info_El_Wakeup_V12, compu {132=Cx84_IVIPartition_3 (CM_NM_Info_El_Wakeup_V12_Cx84_IVIPartition_3), 131=Cx83_IVIPartition_2 (CM_NM_Info_El_Wakeup_V12_Cx83_IVIPartition_2), 129=Cx81_ScreenUpdate (CM_NM_Info_El_Wakeup_V12_Cx81_ScreenUpdate), 135=Cx87_Systempartition_3 (CM_NM_Info_El_Wakeup_V12_Cx87_Systempartition_3), 2=Cx2_KL15_HW (CM_NM_Info_El_Wakeup_V12_Cx2_KL15_HW), 130=Cx82_IVIPartition_1 (CM_NM_Info_El_Wakeup_V12_Cx82_IVIPartition_1), 136=Cx88_User_Anmeldung (CM_NM_Info_El_Wakeup_V12_Cx88_User_Anmeldung), 0=Cx0_Peripherie_Wakeup_Ursache_nicht_bekannt (CM_NM_Info_El_Wakeup_V12_Cx0_Peripherie_Wakeup_Ursache_nicht_bekannt), 137=Cx89_BAP_Kommunikation_Klima (CM_NM_Info_El_Wakeup_V12_Cx89_BAP_Kommunikation_Klima), 1=Cx1_Bus_Wakeup (CM_NM_Info_El_Wakeup_V12_Cx1_Bus_Wakeup), 167=Cxa7_SOK_Master_Anforderung (CM_NM_Info_El_Wakeup_V12_Cxa7_SOK_Master_Anforderung), 4=Cx4_Buswakeup_WU_HCP3_CANFD (CM_NM_Info_El_Wakeup_V12_Cx4_Buswakeup_WU_HCP3_CANFD), 134=Cx86_Systempartition_2 (CM_NM_Info_El_Wakeup_V12_Cx86_Systempartition_2), 5=Cx5_Buswakeup_HCP3_CANFD01 (CM_NM_Info_El_Wakeup_V12_Cx5_Buswakeup_HCP3_CANFD01), 6=Cx6_Buswakeup_HCP3_CANFD02 (CM_NM_Info_El_Wakeup_V12_Cx6_Buswakeup_HCP3_CANFD02), 133=Cx85_Systempartition_1 (CM_NM_Info_El_Wakeup_V12_Cx85_Systempartition_1), 128=Cx80_VNSM_Anforderung (CM_NM_Info_El_Wakeup_V12_Cx80_VNSM_Anforderung)}, range raw 0..167, transfer-property=TRIGGERED  # enthält die Weckursache; stehen mehrere Weckursachen parallel an, dann muss der kleinste Wert übertragen werden
          signal NM_Info_El_NM_aktiv_KL15_XIX_NM_Info_El_XIX_WU_HCP3_CANFD: start 160, 1 bit, little-endian, data-type-policy=OVERRIDE, i-signal-type=PRIMITIVE, init-value=0, base-type=BT_NM_Info_El_NM_aktiv_KL15, compu {1=Cx1_KL15_EIN (CM_NM_Info_El_NM_aktiv_KL15_Cx1_KL15_EIN), 0=Cx0_Inaktiv (CM_NM_Info_El_NM_aktiv_KL15_Cx0_Inaktiv)}, range raw 0..1, transfer-property=TRIGGERED  # Steuergerät hat KL15-EIN erkannt
          signal NM_Info_El_NM_aktiv_Diag_XIX_NM_Info_El_XIX_WU_HCP3_CANFD: start 161, 1 bit, little-endian, data-type-policy=OVERRIDE, i-signal-type=PRIMITIVE, init-value=0, base-type=BT_NM_Info_El_NM_aktiv_Diag, compu {1=Cx1_Diagnose_aktiv (CM_NM_Info_El_NM_aktiv_Diag_Cx1_Diagnose_aktiv), 0=Cx0_Inaktiv (CM_NM_Info_El_NM_aktiv_Diag_Cx0_Inaktiv)}, range raw 0..1, transfer-property=TRIGGERED  # Diagnose befindet sich nach VW80124 in einer NonDefaultDiagnostic-Session, z.B. ExtendedDiagnostic-Session
          signal NM_Info_El_NM_aktiv_Tmin_XIX_NM_Info_El_XIX_WU_HCP3_CANFD: start 162, 1 bit, little-endian, data-type-policy=OVERRIDE, i-signal-type=PRIMITIVE, init-value=0, base-type=BT_NM_Info_El_NM_aktiv_Tmin, compu {1=Cx1_Mindestaktivzeit (CM_NM_Info_El_NM_aktiv_Tmin_Cx1_Mindestaktivzeit), 0=Cx0_Inaktiv (CM_NM_Info_El_NM_aktiv_Tmin_Cx0_Inaktiv)}, range raw 0..1, transfer-property=TRIGGERED  # Mindestaktivzeit ist noch nicht abgelaufen (bei jedem Weckereignis wird die Mindestaktivzeit neu gestartet)
          signal NM_Info_El_NM_aktiv_CABaktiv_XIX_NM_Info_El_XIX_WU_HCP3_CANFD: start 163, 1 bit, little-endian, data-type-policy=OVERRIDE, i-signal-type=PRIMITIVE, init-value=0, base-type=BT_NM_Info_El_NM_aktiv_CABaktiv, compu {1=Cx1_Cluster_Min_Req_TimeOfVNSM (CM_NM_Info_El_NM_aktiv_CABaktiv_Cx1_Cluster_Min_Req_TimeOfVNSM), 0=Cx0_Inaktiv (CM_NM_Info_El_NM_aktiv_CABaktiv_Cx0_Inaktiv)}, range raw 0..1, transfer-property=TRIGGERED  # Nachlauf aufgrund Funktionscluster Anforderung
          signal NM_aktiv_GoodbyeScreen_XIX_NM_Info_El_XIX_WU_HCP3_CANFD: start 164, 1 bit, little-endian, data-type-policy=OVERRIDE, i-signal-type=PRIMITIVE, init-value=0, base-type=BT_NM_aktiv_GoodbyeScreen, compu {1=Cx1_Aktiv (CM_NM_aktiv_GoodbyeScreen_Cx1_Aktiv), 0=Cx0_Inaktiv (CM_NM_aktiv_GoodbyeScreen_Cx0_Inaktiv)}, range raw 0..1, transfer-property=TRIGGERED  # Der Goodbye-Screen wird im Infotainment beim wechsel von KL15=ON zu KL15=OFF aufgeschalten und beinhaltet unterschiedliche Informationen die beim Aussteigen von Relevanz sind.
          signal NM_aktiv_SysPartition_1_XIX_NM_Info_El_XIX_WU_HCP3_CANFD: start 165, 1 bit, little-endian, data-type-policy=OVERRIDE, i-signal-type=PRIMITIVE, init-value=0, base-type=BT_NM_aktiv_SysPartition_1, compu {1=Cx1_Aktiv (CM_NM_aktiv_SysPartition_1_Cx1_Aktiv), 0=Cx0_Inaktiv (CM_NM_aktiv_SysPartition_1_Cx0_Inaktiv)}, range raw 0..1, transfer-property=TRIGGERED  # Vorhalt VNSM_UsrId und NM-Aktivgrund-Signal für künftig möglichen Funktionshub ohne erforderlichen K-Matrix Update
          signal NM_aktiv_SysPartition_2_XIX_NM_Info_El_XIX_WU_HCP3_CANFD: start 166, 1 bit, little-endian, data-type-policy=OVERRIDE, i-signal-type=PRIMITIVE, init-value=0, base-type=BT_NM_aktiv_SysPartition_2, compu {0=Cx0_Inaktiv (CM_NM_aktiv_SysPartition_2_Cx0_Inaktiv), 1=Cx1_Aktiv (CM_NM_aktiv_SysPartition_2_Cx1_Aktiv)}, range raw 0..1, transfer-property=PENDING  # Vorhalt VNSM_UsrId und NM-Aktivgrund-Signal für künftig möglichen Funktionshub ohne erforderlichen K-Matrix Update
          signal NM_aktiv_SysPartition_3_XIX_NM_Info_El_XIX_WU_HCP3_CANFD: start 167, 1 bit, little-endian, data-type-policy=OVERRIDE, i-signal-type=PRIMITIVE, init-value=0, base-type=BT_NM_aktiv_SysPartition_3, compu {0=Cx0_Inaktiv (CM_NM_aktiv_SysPartition_3_Cx0_Inaktiv), 1=Cx1_Aktiv (CM_NM_aktiv_SysPartition_3_Cx1_Aktiv)}, range raw 0..1, transfer-property=TRIGGERED  # Vorhalt VNSM_UsrId und NM-Aktivgrund-Signal für künftig möglichen Funktionshub ohne erforderlichen K-Matrix Update
          signal NM_aktiv_IVIPartition_1_XIX_NM_Info_El_XIX_WU_HCP3_CANFD: start 168, 1 bit, little-endian, data-type-policy=OVERRIDE, i-signal-type=PRIMITIVE, init-value=0, base-type=BT_NM_aktiv_IVIPartition_1, compu {0=Cx0_Inaktiv (CM_NM_aktiv_IVIPartition_1_Cx0_Inaktiv), 1=Cx1_Aktiv (CM_NM_aktiv_IVIPartition_1_Cx1_Aktiv)}, range raw 0..1, transfer-property=TRIGGERED  # Vorhalt VNSM_UsrId und NM-Aktivgrund-Signal für künftig möglichen Funktionshub ohne erforderlichen K-Matrix Update
          signal NM_aktiv_IVIPartition_2_XIX_NM_Info_El_XIX_WU_HCP3_CANFD: start 169, 1 bit, little-endian, data-type-policy=OVERRIDE, i-signal-type=PRIMITIVE, init-value=0, base-type=BT_NM_aktiv_IVIPartition_2, compu {0=Cx0_Inaktiv (CM_NM_aktiv_IVIPartition_2_Cx0_Inaktiv), 1=Cx1_Aktiv (CM_NM_aktiv_IVIPartition_2_Cx1_Aktiv)}, range raw 0..1, transfer-property=TRIGGERED  # Vorhalt VNSM_UsrId und NM-Aktivgrund-Signal für künftig möglichen Funktionshub ohne erforderlichen K-Matrix Update
          signal NM_aktiv_IVIPartition_3_XIX_NM_Info_El_XIX_WU_HCP3_CANFD: start 170, 1 bit, little-endian, data-type-policy=OVERRIDE, i-signal-type=PRIMITIVE, base-type=BT_NM_aktiv_IVIPartition_3, compu {0=Cx0_Inaktiv (CM_NM_aktiv_IVIPartition_3_Cx0_Inaktiv), 1=Cx1_Aktiv (CM_NM_aktiv_IVIPartition_3_Cx1_Aktiv)}, range raw 0..1, transfer-property=PENDING  # Vorhalt VNSM_UsrId und NM-Aktivgrund-Signal für künftig möglichen Funktionshub ohne erforderlichen K-Matrix Update
          signal NM_aktiv_Internetverbindung_XIX_NM_Info_El_XIX_WU_HCP3_CANFD: start 171, 1 bit, little-endian, data-type-policy=OVERRIDE, i-signal-type=PRIMITIVE, init-value=0, base-type=BT_NM_aktiv_Internetverbindung, compu {0=Cx0_Inaktiv (CM_NM_aktiv_Internetverbindung_Cx0_Inaktiv), 1=Cx1_Aktiv (CM_NM_aktiv_Internetverbindung_Cx1_Aktiv)}, range raw 0..1, transfer-property=TRIGGERED  # Nach Klemme 15 aus wird eine Anbindung an die ConMod benötigt, um Internet-Funktionalitäten sicherzustellen.
          signal NM_aktiv_Tankinhalt_ermitteln_XIX_NM_Info_El_XIX_WU_HCP3_CANFD: start 172, 1 bit, little-endian, data-type-policy=OVERRIDE, i-signal-type=PRIMITIVE, init-value=0, base-type=BT_NM_aktiv_Tankinhalt_ermitteln, compu {1=Cx1_Aktiv (CM_NM_aktiv_Tankinhalt_ermitteln_Cx1_Aktiv), 0=Cx0_Inaktiv (CM_NM_aktiv_Tankinhalt_ermitteln_Cx0_Inaktiv)}, range raw 0..1, transfer-property=TRIGGERED  # Der Tankalgorithmus bildet für die Nachtankerkennung beginnend mit Fahrzeugstillstand einen Referenzwert aus mindestens 8 gültigen Tankfüllstands- Messwerten. Fällt der Vorgang unmittelbar in eine KL15 Aus -phase, so muss der Bus wachgehalten werden bis die Referenzwertbildung abgeschlossen ist.
          signal NM_aktiv_SOK_Master_Anf_Info_El_XIX_NM_Info_El_XIX_WU_HCP3_CANFD: start 173, 1 bit, little-endian, data-type-policy=OVERRIDE, i-signal-type=PRIMITIVE, init-value=0, base-type=BT_NM_aktiv_SOK_Master_Anf_Info_El, compu {0=Cx0_Inaktiv (CM_NM_aktiv_SOK_Master_Anf_Info_El_Cx0_Inaktiv), 1=Cx1_Aktiv (CM_NM_aktiv_SOK_Master_Anf_Info_El_Cx1_Aktiv)}, range raw 0..1, transfer-property=TRIGGERED  # Für die korrekte Funktionsweise von SOK wird der sog. SOK Zeimtaster auf dem HCP5 µC benötigt.
          signal NM_aktiv_User_Anmeldung_XIX_NM_Info_El_XIX_WU_HCP3_CANFD: start 174, 1 bit, little-endian, data-type-policy=OVERRIDE, i-signal-type=PRIMITIVE, init-value=0, base-type=BT_NM_aktiv_User_Anmeldung, compu {0=Cx0_Inaktiv (CM_NM_aktiv_User_Anmeldung_Cx0_Inaktiv), 1=Cx1_Aktiv (CM_NM_aktiv_User_Anmeldung_Cx1_Aktiv)}, range raw 0..1, transfer-property=TRIGGERED  # Zur Nutzung des Nutzerlogins bzw. der Nutzerumschaltung auch bei KL15 Aus ist es notwendig, dass die beteiligten Steuergeräte wie HCP4, HCP5 und als Wecker HCP3 aufgeweckt und wachgehalten werden.
          signal NM_aktiv_Innenraumerlebnis_XIX_NM_Info_El_XIX_WU_HCP3_CANFD: start 175, 1 bit, little-endian, data-type-policy=OVERRIDE, i-signal-type=PRIMITIVE, init-value=0, base-type=BT_NM_aktiv_Innenraumerlebnis, compu {1=Cx1_Aktiv (CM_NM_aktiv_Innenraumerlebnis_Cx1_Aktiv), 0=Cx0_Inaktiv (CM_NM_aktiv_Innenraumerlebnis_Cx0_Inaktiv)}, range raw 0..1, transfer-property=TRIGGERED  # Erlebnis Innenraum (Inszenierungsmaster-App im HCP3) schaltet verschiedene Komfortfunktionen möglichst harmonisch zusammen um dem Kunden den Fahrzeuginnenraum zu inszenieren. Dabei überstimmt die Funktion für die Dauer der Inszenierung die Kundeneinstellungen, z.B. im Ambientelicht und am Ende der Inszenierung stellt die Funktion wieder die letzte Kundeneinstellung ein.
          signal NM_aktiv_BAP_Kommunikation_SYS_XIX_NM_Info_El_XIX_WU_HCP3_CANFD: start 176, 1 bit, little-endian, data-type-policy=OVERRIDE, i-signal-type=PRIMITIVE, init-value=0, base-type=BT_NM_aktiv_BAP_Kommunikation_SYS, compu {1=Cx1_Aktiv (CM_NM_aktiv_BAP_Kommunikation_SYS_Cx1_Aktiv), 0=Cx0_Inaktiv (CM_NM_aktiv_BAP_Kommunikation_SYS_Cx0_Inaktiv)}, range raw 0..1, transfer-property=PENDING  # Die Native BAP Business Logik ist eine SW Komponente die im HCP3 für die BAP Kommunikation zuständig ist. Da es funktionen gibt gibt die eine BAP Kommunikation bei KL15=OFF benötigen (Klima, TME) muss diese SW Komponente die Möglichkeit haben CABs anzufragen/wecken/wachzuhalten um die BAP Kommuniation für die betroffenen Funktionen auch bei KL15=OFF zu ermöglichen.
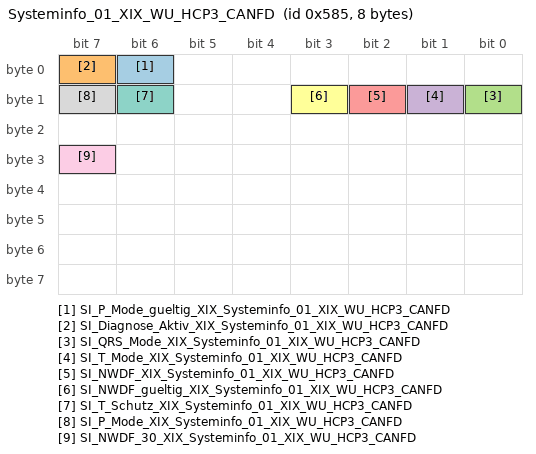
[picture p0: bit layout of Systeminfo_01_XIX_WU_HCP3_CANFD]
      frame Systeminfo_01_XIX_WU_HCP3_CANFD: id 0x585, to HCP3_IONode, frame-length=8, can-addressing-mode=STANDARD, can-frame-rx-behavior=CAN-FD, can-frame-tx-behavior=CAN-FD
        pdu Systeminfo_01_XIX_WU_HCP3_CANFD: length=8, minimum-delay=0.01, transmission-mode-true-timing={cyclic-timing={time-offset=0.0, time-period=1.0}, event-controlled-timing={number-of-repetitions=0, repetition-period=0.0}}, unused-bit-pattern=0  # MQB, MLBevo
          signal SI_P_Mode_gueltig_XIX_Systeminfo_01_XIX_WU_HCP3_CANFD: start 6, 1 bit, little-endian, data-type-policy=OVERRIDE, i-signal-type=PRIMITIVE, init-value=0, base-type=BT_SI_P_Mode_gueltig, compu {1=Cx1_zentraler_Produktionsmode (CM_SI_P_Mode_gueltig_Cx1_zentraler_Produktionsmode), 0=Cx0_dezentraler_Produktionsmode (CM_SI_P_Mode_gueltig_Cx0_dezentraler_Produktionsmode)}, range raw 0..1, transfer-property=PENDING, to HCP3_IONode(timeout 5 s)  # zeigt an, ob es sich um ein Fahrzeug mit zentraler oder dezentraler Steu-erung des Produktionsmodes handelt Siehe Q-LAH Produktionsmode (LAH.DUM.907.AS)
          signal SI_Diagnose_Aktiv_XIX_Systeminfo_01_XIX_WU_HCP3_CANFD: start 7, 1 bit, little-endian, data-type-policy=OVERRIDE, i-signal-type=PRIMITIVE, init-value=0, base-type=BT_SI_Diagnose_Aktiv, compu {0=Cx0_inaktiv (CM_SI_Diagnose_Aktiv_Cx0_inaktiv), 1=Cx1_aktiv (CM_SI_Diagnose_Aktiv_Cx1_aktiv)}, range raw 0..1, transfer-property=PENDING  # Gibt an ob Diagnose-Botschaften empfangen werden und somit eine Diagnose aktiv ist. MQB: Gibt an ob Diagnose-Bus Botschaften empfangen werden und somit eine Diagnose aktiv ist.
          signal SI_QRS_Mode_XIX_Systeminfo_01_XIX_WU_HCP3_CANFD: start 8, 1 bit, little-endian, data-type-policy=OVERRIDE, i-signal-type=PRIMITIVE, init-value=0, base-type=BT_SI_QRS_Mode, compu {0=Cx0_QRS_Messmodus_nicht_aktiv (CM_SI_QRS_Mode_Cx0_QRS_Messmodus_nicht_aktiv), 1=Cx1_QRS_Messmodus_aktiv (CM_SI_QRS_Mode_Cx1_QRS_Messmodus_aktiv)}, range raw 0..1, transfer-property=PENDING, to HCP3_IONode(timeout 5 s)  # Messmodus Quick-Ruhestrom
          signal SI_T_Mode_XIX_Systeminfo_01_XIX_WU_HCP3_CANFD: start 9, 1 bit, little-endian, data-type-policy=OVERRIDE, i-signal-type=PRIMITIVE, init-value=0, base-type=BT_SI_T_Mode, compu {0=Cx0_Transportmodus_nicht_aktiv (CM_SI_T_Mode_Cx0_Transportmodus_nicht_aktiv), 1=Cx1_Transportmodus_aktiv (CM_SI_T_Mode_Cx1_Transportmodus_aktiv)}, range raw 0..1, transfer-property=PENDING, to HCP3_IONode(timeout 5 s)  # 0x0: Transportmodus nicht aktiv 0x1: Transportmodus aktiv
          signal SI_NWDF_XIX_Systeminfo_01_XIX_WU_HCP3_CANFD: start 10, 1 bit, little-endian, data-type-policy=OVERRIDE, i-signal-type=PRIMITIVE, init-value=0, base-type=BT_SI_NWDF, compu {1=Cx1_Ueberwachung_freigegeben (CM_SI_NWDF_Cx1_Ueberwachung_freigegeben), 0=Cx0_Ueberwachung_nicht_freigegeben (CM_SI_NWDF_Cx0_Ueberwachung_nicht_freigegeben)}, range raw 0..1, transfer-property=TRIGGERED-ON-CHANGE-WITHOUT-REPETITION, to HCP3_IONode(timeout 5 s)  # Netzwerk-Diagnose Freigebe zur zentralen Aktivierung der Netzwerkdiagnose
          signal SI_NWDF_gueltig_XIX_Systeminfo_01_XIX_WU_HCP3_CANFD: start 11, 1 bit, little-endian, data-type-policy=OVERRIDE, i-signal-type=PRIMITIVE, init-value=1, base-type=BT_SI_NWDF_gueltig, compu {0=Cx0_NWDF_wird_nicht_unterstuetzt (CM_SI_NWDF_gueltig_Cx0_NWDF_wird_nicht_unterstuetzt), 1=Cx1_NWDF_wird_unterstuetzt (CM_SI_NWDF_gueltig_Cx1_NWDF_wird_unterstuetzt)}, range raw 0..1, transfer-property=PENDING, to HCP3_IONode(timeout 5 s)  # Gültigkeitsbit zu SI_NWDF gemäß Lastenheft: Zentrale Aktivierung Netzwerkdiagnose
          signal SI_T_Schutz_XIX_Systeminfo_01_XIX_WU_HCP3_CANFD: start 14, 1 bit, little-endian, data-type-policy=OVERRIDE, i-signal-type=PRIMITIVE, init-value=0, base-type=BT_SI_T_Schutz, compu {0=Cx0_Transportschutz_nicht_aktiv (CM_SI_T_Schutz_Cx0_Transportschutz_nicht_aktiv), 1=Cx1_Transportschutz_aktiv (CM_SI_T_Schutz_Cx1_Transportschutz_aktiv)}, range raw 0..1, transfer-property=PENDING, to HCP3_IONode(timeout 5 s)  # Transportschutz-Signal, das bei Transportmodus und Motorlauf aktiv bleibt 0x0: Transportschutz nicht aktiv 0x1: Transportschutz aktiv
          signal SI_P_Mode_XIX_Systeminfo_01_XIX_WU_HCP3_CANFD: start 15, 1 bit, little-endian, data-type-policy=OVERRIDE, i-signal-type=PRIMITIVE, init-value=0, base-type=BT_SI_P_Mode, compu {0=Cx0_inaktiv (CM_SI_P_Mode_Cx0_inaktiv), 1=Cx1_aktiv (CM_SI_P_Mode_Cx1_aktiv)}, range raw 0..1, transfer-property=PENDING, to HCP3_IONode(timeout 5 s)  # Zentrale Steuerung des Produktionsmodes gemäß Q-LAH-Produktionsmode (LAH.DUM.907.AS)
          signal SI_NWDF_30_XIX_Systeminfo_01_XIX_WU_HCP3_CANFD: start 31, 1 bit, little-endian, data-type-policy=OVERRIDE, i-signal-type=PRIMITIVE, init-value=0, base-type=BT_SI_NWDF_30, compu {0=Cx0_Ueberwachung_nicht_freigegeben (CM_SI_NWDF_30_Cx0_Ueberwachung_nicht_freigegeben), 1=Cx1_Ueberwachung_freigegeben (CM_SI_NWDF_30_Cx1_Ueberwachung_freigegeben)}, range raw 0..1, transfer-property=TRIGGERED-ON-CHANGE-WITHOUT-REPETITION, to HCP3_IONode(timeout 5 s)  # Netzwerk-Diagnose Freigabe zur zentralen Aktivierung der Netzwerkdiagnose (keine Ausblendbedingung aktiv)
  can cluster HCP3_CANFD01: baudrate=500000, protocol-name=CAN, protocol-version=2.0, bus-off-recovery={bor-counter-l-1-to-l-2=1, bor-time-l-1=0.05, bor-time-l-2=0.2}, can-fd-baudrate=1000000
    can physical channel CHNL: comm-connectors=CN_HCP3_CANFD01
      frame ARC_HUD_Req_FD_XIX_HCP3_CANFD01: id 0x1C403B1B, from HCP3_IONode, frame-length=64, can-addressing-mode=EXTENDED, can-frame-rx-behavior=CAN-FD, can-frame-tx-behavior=CAN-FD
        n pdu ARC_HUD_Req_FD_XIX_HCP3_CANFD01: length=64
      frame ARC_HUD_Resp_FD_XIX_HCP3_CANFD01: id 0x1C423B1B, to HCP3_IONode, frame-length=64, can-addressing-mode=EXTENDED, can-frame-rx-behavior=CAN-FD, can-frame-tx-behavior=CAN-FD
        n pdu ARC_HUD_Resp_FD_XIX_HCP3_CANFD01: length=64
      frame CID_01_XIX_HCP3_CANFD01: id 0x1A55556C, to HCP3_IONode, frame-length=48, can-addressing-mode=EXTENDED, can-frame-rx-behavior=CAN-FD, can-frame-tx-behavior=CAN-FD
        pdu CID_01_XIX_HCP3_CANFD01: length=48, minimum-delay=0.04, transmission-mode-true-timing={cyclic-timing={time-offset=0.0, time-period=1.0}, event-controlled-timing={number-of-repetitions=0, repetition-period=0.0}}, unused-bit-pattern=0
          signal CID_LVDS_Status_XIX_CID_01_XIX_HCP3_CANFD01: start 12, 1 bit, little-endian, data-type-policy=OVERRIDE, i-signal-type=PRIMITIVE, init-value=0, base-type=BT_CID_LVDS_Status, compu {0=Cx0_LVDS_Unlocked (CM_CID_LVDS_Status_Cx0_LVDS_Unlocked), 1=Cx1_LVDS_Lock (CM_CID_LVDS_Status_Cx1_LVDS_Lock)}, range raw 0..1, transfer-property=TRIGGERED-ON-CHANGE-WITHOUT-REPETITION, to HCP3_IONode(timeout 5 s)  # Statussignal im CID LVDS_Lock= 1 Ein valides Videosignal zum Anzeigen liegt an LVDS_Unlocked = 0 kein Videosignal liegt an
          signal CID_State_XIX_CID_01_XIX_HCP3_CANFD01: start 13, 3 bit, little-endian, data-type-policy=OVERRIDE, i-signal-type=PRIMITIVE, init-value=0, base-type=BT_CID_State, compu {1=Cx1_Disp_On (CM_CID_State_Cx1_Disp_On), 2=Cx2_LowPow (CM_CID_State_Cx2_LowPow), 0=Cx0_Disp_Off (CM_CID_State_Cx0_Disp_Off)}, range raw 0..2, transfer-property=TRIGGERED-ON-CHANGE-WITHOUT-REPETITION, to HCP3_IONode(timeout 5 s)  # Power state des CID
          signal CID_PCB_Temp_Error_XIX_CID_01_XIX_HCP3_CANFD01: start 16, 1 bit, little-endian, data-type-policy=OVERRIDE, i-signal-type=PRIMITIVE, init-value=0, base-type=BT_CID_PCB_Temp_Error, invalid-value=Invalid_CID_PCB_Temp_Error_XIX_CID_01_XIX_HCP3_CANFD01:1, compu {1=Cx1_Fehler (CM_CID_PCB_Temp_Error_Cx1_Fehler), 0=Cx0_normal (CM_CID_PCB_Temp_Error_Cx0_normal)}, range raw 0..1, transfer-property=TRIGGERED-ON-CHANGE-WITHOUT-REPETITION, to HCP3_IONode(timeout 5 s)  # Display unit has detected a temperature error of the PCB
          signal CID_Temp_Error_XIX_CID_01_XIX_HCP3_CANFD01: start 17, 1 bit, little-endian, data-type-policy=OVERRIDE, i-signal-type=PRIMITIVE, init-value=0, base-type=BT_CID_Temp_Error, invalid-value=Invalid_CID_Temp_Error_XIX_CID_01_XIX_HCP3_CANFD01:1, compu {1=Cx1_Fehler (CM_CID_Temp_Error_Cx1_Fehler), 0=Cx0_normal (CM_CID_Temp_Error_Cx0_normal)}, range raw 0..1, transfer-property=TRIGGERED-ON-CHANGE-WITHOUT-REPETITION, to HCP3_IONode(timeout 5 s)  # Display unit has detected a temperature error of the display panel
          signal CID_HDCP_Status_XIX_CID_01_XIX_HCP3_CANFD01: start 18, 1 bit, little-endian, data-type-policy=OVERRIDE, i-signal-type=PRIMITIVE, init-value=0, base-type=BT_CID_HDCP_Status, invalid-value=Invalid_CID_HDCP_Status_XIX_CID_01_XIX_HCP3_CANFD01:1, compu {1=Cx1_Fehler (CM_CID_HDCP_Status_Cx1_Fehler), 0=Cx0_Kein_Fehler (CM_CID_HDCP_Status_Cx0_Kein_Fehler)}, range raw 0..1, transfer-property=TRIGGERED-ON-CHANGE-WITHOUT-REPETITION, to HCP3_IONode(timeout 5 s)  # Current status of HDCP
          signal CID_SystemMode_XIX_CID_01_XIX_HCP3_CANFD01: start 19, 1 bit, little-endian, data-type-policy=OVERRIDE, i-signal-type=PRIMITIVE, init-value=0, base-type=BT_CID_SystemMode, compu {0=Cx0_bootloader (CM_CID_SystemMode_Cx0_bootloader), 1=Cx1_applikation (CM_CID_SystemMode_Cx1_applikation)}, range raw 0..1, transfer-property=TRIGGERED-ON-CHANGE-WITHOUT-REPETITION, to HCP3_IONode(timeout 5 s)  # Current system mode
          signal CID_LVDS_Errorstate_XIX_CID_01_XIX_HCP3_CANFD01: start 20, 2 bit, little-endian, data-type-policy=OVERRIDE, i-signal-type=PRIMITIVE, init-value=0, base-type=BT_CID_LVDS_Errorstate, compu {1=Cx1_SW_error (CM_CID_LVDS_Errorstate_Cx1_SW_error), 0=Cx0_no_error (CM_CID_LVDS_Errorstate_Cx0_no_error), 2=Cx2_HW_error (CM_CID_LVDS_Errorstate_Cx2_HW_error)}, range raw 0..2, transfer-property=PENDING, to HCP3_IONode(timeout 5 s)  # CID_LVDS_Errorstate = 0 no error detected CID_LVDS_Errorstate = 1 SW error detected CID_LVDS_Errorstate = 2 HW error detected
          signal CID_CL30_Overvolt_Error_XIX_CID_01_XIX_HCP3_CANFD01: start 22, 1 bit, little-endian, data-type-policy=OVERRIDE, i-signal-type=PRIMITIVE, init-value=0, base-type=BT_CID_CL30_Overvolt_Error, invalid-value=Invalid_CID_CL30_Overvolt_Error_XIX_CID_01_XIX_HCP3_CANFD01:1, compu {1=Cx1_Fehler (CM_CID_CL30_Overvolt_Error_Cx1_Fehler), 0=Cx0_normal (CM_CID_CL30_Overvolt_Error_Cx0_normal)}, range raw 0..1, transfer-property=TRIGGERED-ON-CHANGE-WITHOUT-REPETITION, to HCP3_IONode(timeout 5 s)  # Display unit detected overvoltage error
          signal CID_CL30_Undervolt_Error_XIX_CID_01_XIX_HCP3_CANFD01: start 23, 1 bit, little-endian, data-type-policy=OVERRIDE, i-signal-type=PRIMITIVE, init-value=0, base-type=BT_CID_CL30_Undervolt_Error, invalid-value=Invalid_CID_CL30_Undervolt_Error_XIX_CID_01_XIX_HCP3_CANFD01:1, compu {1=Cx1_Fehler (CM_CID_CL30_Undervolt_Error_Cx1_Fehler), 0=Cx0_normal (CM_CID_CL30_Undervolt_Error_Cx0_normal)}, range raw 0..1, transfer-property=TRIGGERED-ON-CHANGE-WITHOUT-REPETITION, to HCP3_IONode(timeout 5 s)  # Display unit detected undervoltage error
          signal CID_CL_30F_XIX_CID_01_XIX_HCP3_CANFD01: start 24, 8 bit, little-endian, data-type-policy=OVERRIDE, i-signal-type=PRIMITIVE, init-value=254, base-type=BT_CID_CL_30F, invalid-value=Invalid_CID_CL_30F_XIX_CID_01_XIX_HCP3_CANFD01:255, compu {phys=raw*0.1 for raw 0..253, 255=Cxff_Fehler (CM_CID_CL_30F_Cxff_Fehler), 254=Cxfe_Init (CM_CID_CL_30F_Cxfe_Init); unit Unit_Volt}, range phys 0..25.3 Unit_Volt, raw 0..255, unit=Unit_Volt, transfer-property=PENDING, to HCP3_IONode(timeout 5 s)  # Measured supply voltage of the display unit in volt
          signal CID_FanSpeed_XIX_CID_01_XIX_HCP3_CANFD01: start 32, 7 bit, little-endian, data-type-policy=OVERRIDE, i-signal-type=PRIMITIVE, init-value=126, base-type=BT_CID_FanSpeed, invalid-value=Invalid_CID_FanSpeed_XIX_CID_01_XIX_HCP3_CANFD01:127, compu {phys=raw for raw 0..100, 127=Cx7f_Fehler (CM_CID_FanSpeed_Cx7f_Fehler), 126=Cx7e_Init (CM_CID_FanSpeed_Cx7e_Init); unit Unit_PerCent}, range phys 0..100 Unit_PerCent, raw 0..127, unit=Unit_PerCent, transfer-property=PENDING, to HCP3_IONode(timeout 5 s)  # Speed of fan in display unit
          signal CID_Photosensor_XIX_CID_01_XIX_HCP3_CANFD01: start 39, 9 bit, little-endian, data-type-policy=OVERRIDE, i-signal-type=PRIMITIVE, init-value=510, base-type=BT_CID_Photosensor, invalid-value=Invalid_CID_Photosensor_XIX_CID_01_XIX_HCP3_CANFD01:511, compu {phys=raw*0.25 for raw 1..400, 511=Cx1ff_Fehler (CM_CID_Photosensor_Cx1ff_Fehler), 0=Cx0_Sensor_unbeleuchtet (CM_CID_Photosensor_Cx0_Sensor_unbeleuchtet), 510=Cx1fe_Initialwert (CM_CID_Photosensor_Cx1fe_Initialwert); unit Unit_PerCent}, range phys 0.25..100 Unit_PerCent, raw 0..511, unit=Unit_PerCent, transfer-property=PENDING, to HCP3_IONode(timeout 5 s)  # Measured value photosensor of the display unit (PCM or CDR) logarithmically distorted (see description of functions Nightdesign - according to Audi Spec) PCM/CDR_Signal
          signal CID_DispDerating_XIX_CID_01_XIX_HCP3_CANFD01: start 48, 8 bit, little-endian, data-type-policy=OVERRIDE, i-signal-type=PRIMITIVE, init-value=254, base-type=BT_CID_DispDerating, invalid-value=Invalid_CID_DispDerating_XIX_CID_01_XIX_HCP3_CANFD01:255, compu {phys=raw for raw 0..100, 255=Cxff_Fehler (CM_CID_DispDerating_Cxff_Fehler), 254=Cxfe_Init (CM_CID_DispDerating_Cxfe_Init); unit Unit_PerCent}, range phys 0..100 Unit_PerCent, raw 0..255, unit=Unit_PerCent, transfer-property=PENDING, to HCP3_IONode(timeout 5 s)  # Limitation of power dissipation depending on the temperature
          signal CID_TempSensor_XIX_CID_01_XIX_HCP3_CANFD01: start 56, 8 bit, little-endian, data-type-policy=OVERRIDE, i-signal-type=PRIMITIVE, init-value=254, base-type=BT_CID_TempSensor, invalid-value=Invalid_CID_TempSensor_XIX_CID_01_XIX_HCP3_CANFD01:255, compu {phys=raw-55 for raw 0..182, 255=Cxff_Fehler (CM_CID_TempSensor_Cxff_Fehler), 254=Cxfe_Init (CM_CID_TempSensor_Cxfe_Init); unit Unit_DegreCelsi}, range phys -55..127 Unit_DegreCelsi, raw 0..255, unit=Unit_DegreCelsi, transfer-property=PENDING, to HCP3_IONode(timeout 5 s)  # Display Unit current temperatur of the displaypanel
          signal CID_TempSensorMax_XIX_CID_01_XIX_HCP3_CANFD01: start 64, 8 bit, little-endian, data-type-policy=OVERRIDE, i-signal-type=PRIMITIVE, init-value=254, base-type=BT_CID_TempSensorMax, invalid-value=Invalid_CID_TempSensorMax_XIX_CID_01_XIX_HCP3_CANFD01:255, compu {phys=raw-55 for raw 0..182, 255=Cxff_Fehler (CM_CID_TempSensorMax_Cxff_Fehler), 254=Cxfe_Init (CM_CID_TempSensorMax_Cxfe_Init); unit Unit_DegreCelsi}, range phys -55..127 Unit_DegreCelsi, raw 0..255, unit=Unit_DegreCelsi, transfer-property=PENDING, to HCP3_IONode(timeout 5 s)  # Stored maximum sensor temperature of the display panel. Value remains over quiescent current
          signal CID_PCB_TempSensor_XIX_CID_01_XIX_HCP3_CANFD01: start 72, 8 bit, little-endian, data-type-policy=OVERRIDE, i-signal-type=PRIMITIVE, init-value=254, base-type=BT_CID_PCB_TempSensor, invalid-value=Invalid_CID_PCB_TempSensor_XIX_CID_01_XIX_HCP3_CANFD01:255, compu {phys=raw-55 for raw 0..182, 255=Cxff_Fehler (CM_CID_PCB_TempSensor_Cxff_Fehler), 254=Cxfe_Init (CM_CID_PCB_TempSensor_Cxfe_Init); unit Unit_DegreCelsi}, range phys -55..127 Unit_DegreCelsi, raw 0..255, unit=Unit_DegreCelsi, transfer-property=PENDING, to HCP3_IONode(timeout 5 s)  # Display Unit current temperatur of the PCB
          signal CID_PCB_TempSensorMax_XIX_CID_01_XIX_HCP3_CANFD01: start 80, 8 bit, little-endian, data-type-policy=OVERRIDE, i-signal-type=PRIMITIVE, init-value=254, base-type=BT_CID_PCB_TempSensorMax, invalid-value=Invalid_CID_PCB_TempSensorMax_XIX_CID_01_XIX_HCP3_CANFD01:255, compu {phys=raw-55 for raw 0..182, 255=Cxff_Fehler (CM_CID_PCB_TempSensorMax_Cxff_Fehler), 254=Cxfe_Init (CM_CID_PCB_TempSensorMax_Cxfe_Init); unit Unit_DegreCelsi}, range phys -55..127 Unit_DegreCelsi, raw 0..255, unit=Unit_DegreCelsi, transfer-property=PENDING, to HCP3_IONode(timeout 5 s)  # Stored maximum sensor temperature of the PCB (display unit). Value remains over quiescent current
          signal CID_OperatingTime_min_XIX_CID_01_XIX_HCP3_CANFD01: start 88, 8 bit, little-endian, data-type-policy=OVERRIDE, i-signal-type=PRIMITIVE, init-value=254, base-type=BT_CID_OperatingTime_min, invalid-value=Invalid_CID_OperatingTime_min_XIX_CID_01_XIX_HCP3_CANFD01:255, compu {phys=raw for raw 0..59, 255=Cxff_Fehler (CM_CID_OperatingTime_min_Cxff_Fehler), 254=Cxfe_Init (CM_CID_OperatingTime_min_Cxfe_Init); unit Unit_Minut}, range phys 0..59 Unit_Minut, raw 0..255, unit=Unit_Minut, transfer-property=PENDING, to HCP3_IONode(timeout 5 s)  # Display Unit operatingtime minutes share
          signal CID_OperatingTime_hr_XIX_CID_01_XIX_HCP3_CANFD01: start 96, 16 bit, little-endian, data-type-policy=OVERRIDE, i-signal-type=PRIMITIVE, init-value=65534, base-type=BT_CID_OperatingTime_hr, invalid-value=Invalid_CID_OperatingTime_hr_XIX_CID_01_XIX_HCP3_CANFD01:65535, compu {phys=raw for raw 0..65533, 65535=Cxffff_Fehler (CM_CID_OperatingTime_hr_Cxffff_Fehler), 65534=Cxfffe_Init (CM_CID_OperatingTime_hr_Cxfffe_Init); unit Unit_Hours}, range phys 0..65533 Unit_Hours, raw 0..65535, unit=Unit_Hours, transfer-property=PENDING, to HCP3_IONode(timeout 5 s)  # Display Unit operatingtime hours share
          signal CID_VW_SL_Spare_Part_Nr_Index_XIX_CID_01_XIX_HCP3_CANFD01: start 112, 16 bit, little-endian, data-type-policy=OVERRIDE, i-signal-type=PRIMITIVE, init-value=45, base-type=BT_CID_VW_SL_Spare_Part_Nr_Index, compu {phys=raw for raw 0..65534, 65535=Cxffff_Error (CM_CID_VW_SL_Spare_Part_Nr_Index_Cxffff_Error); unit Unit_None}, range phys 0..65534 Unit_None, raw 0..65535, unit=Unit_None, transfer-property=PENDING, to HCP3_IONode(timeout 5 s)  # Index der VW/Audi-Teilenummern des CID gemäß der VW 80127= Teilenummer gemäß Kennung Teilnummer aus DID F187 VW SparePartNumber
          signal CID_VW_SL_App_SW_Version_Nr_XIX_CID_01_XIX_HCP3_CANFD01: start 128, 32 bit, little-endian, data-type-policy=OVERRIDE, i-signal-type=PRIMITIVE, init-value=45, base-type=BT_CID_VW_SL_App_SW_Version_Nr, compu {phys=raw for raw 0..4294967294, 4294967295=Cxffffffff_Error (CM_CID_VW_SL_App_SW_Version_Nr_Cxffffffff_Error); unit Unit_None}, range phys 0..4294967294 Unit_None, raw 0..4294967295, unit=Unit_None, transfer-property=PENDING, to HCP3_IONode(timeout 5 s)  # SW-Version des CID gemäß VW80127= Entspricht Software-Version gemäß der DID F189 VW Software Version Number
          signal CID_VW_SL_HW_Version_Nr_XIX_CID_01_XIX_HCP3_CANFD01: start 160, 24 bit, little-endian, data-type-policy=OVERRIDE, i-signal-type=PRIMITIVE, init-value=45, base-type=BT_CID_VW_SL_HW_Version_Nr, compu {phys=raw for raw 0..16777214, 16777215=Cxffffff_Error (CM_CID_VW_SL_HW_Version_Nr_Cxffffff_Error); unit Unit_None}, range phys 0..16777214 Unit_None, raw 0..16777215, unit=Unit_None, transfer-property=PENDING, to HCP3_IONode(timeout 5 s)  # Slave-Hardware des CID gemäß VW80127= Entspricht Kennung Hardware Version gemäß DID F1A3 VW ECU Hardware Version Number
          signal CID_VW_SL_Spare_Part_Nr_EndNr_XIX_CID_01_XIX_HCP3_CANFD01: start 184, 24 bit, little-endian, data-type-policy=OVERRIDE, i-signal-type=PRIMITIVE, init-value=45, base-type=BT_CID_VW_SL_Spare_Part_Nr_EndNr, compu {phys=raw for raw 0..16777214, 16777215=Cxffffff_Error (CM_CID_VW_SL_Spare_Part_Nr_EndNr_Cxffffff_Error); unit Unit_None}, range phys 0..16777214 Unit_None, raw 0..16777215, unit=Unit_None, transfer-property=PENDING, to HCP3_IONode(timeout 5 s)  # Endnummer der VW/Audi-Teilenummern des CID gemäß der VW 80127= Teilenummer gemäß Kennung Teilnummer aus DID F187 VW SparePartNumber
          signal CID_VW_SL_Spare_Part_Nr_MittelNr_XIX_CID_01_XIX_HCP3_CANFD01: start 208, 24 bit, little-endian, data-type-policy=OVERRIDE, i-signal-type=PRIMITIVE, init-value=45, base-type=BT_CID_VW_SL_Spare_Part_Nr_MittelNr, compu {phys=raw for raw 0..16777214, 16777215=Cxffffff_Error (CM_CID_VW_SL_Spare_Part_Nr_MittelNr_Cxffffff_Error); unit Unit_None}, range phys 0..16777214 Unit_None, raw 0..16777215, unit=Unit_None, transfer-property=PENDING, to HCP3_IONode(timeout 5 s)  # Mittelnummer der VW/Audi-Teilenummern des CID gemäß der VW 80127= Teilenummer gemäß Kennung Teilnummer aus DID F187 VW SparePartNumber
          signal CID_VW_SL_Spare_Part_Nr_TMA_XIX_CID_01_XIX_HCP3_CANFD01: start 232, 24 bit, little-endian, data-type-policy=OVERRIDE, i-signal-type=PRIMITIVE, init-value=45, base-type=BT_CID_VW_SL_Spare_Part_Nr_TMA, compu {phys=raw for raw 0..16777214, 16777215=Cxffffff_Error (CM_CID_VW_SL_Spare_Part_Nr_TMA_Cxffffff_Error); unit Unit_None}, range phys 0..16777214 Unit_None, raw 0..16777215, unit=Unit_None, transfer-property=PENDING, to HCP3_IONode(timeout 5 s)  # TMA der VW/Audi-Teilenummern des CID gemäß der VW 80127= Teilenummer gemäß Kennung Teilnummer aus DID F187 VW SparePartNumber
          signal CID_Touch_Errorstate_XIX_CID_01_XIX_HCP3_CANFD01: start 256, 2 bit, little-endian, data-type-policy=OVERRIDE, i-signal-type=PRIMITIVE, init-value=0, base-type=BT_CID_Touch_Errorstate, compu {0=Cx0_no_error (CM_CID_Touch_Errorstate_Cx0_no_error), 1=Cx1_SW_error (CM_CID_Touch_Errorstate_Cx1_SW_error), 2=Cx2_HW_error (CM_CID_Touch_Errorstate_Cx2_HW_error)}, range raw 0..2, transfer-property=PENDING, to HCP3_IONode(timeout 5 s)  # CID_Touch_Errorstate = 0 no error detected CID_Touch_Errorstate = 1 SW error detected CID_Touch_Errorstate = 2 HW error detected
          signal CID_Haptik_Errorstate_XIX_CID_01_XIX_HCP3_CANFD01: start 258, 2 bit, little-endian, data-type-policy=OVERRIDE, i-signal-type=PRIMITIVE, init-value=0, base-type=BT_CID_Haptik_Errorstate, compu {2=Cx2_HW_error (CM_CID_Haptik_Errorstate_Cx2_HW_error), 0=Cx0_no_error (CM_CID_Haptik_Errorstate_Cx0_no_error), 1=Cx1_SW_error (CM_CID_Haptik_Errorstate_Cx1_SW_error)}, range raw 0..2, transfer-property=PENDING, to HCP3_IONode(timeout 5 s)  # CID_Haptik_Errorstate = 0 no error detected CID_Haptik_Errorstate = 1 SW error detected CID_Haptik_Errorstate = 2 HW error detected
          signal CID_LVDS_Splitter_Errorstate_XIX_CID_01_XIX_HCP3_CANFD01: start 260, 2 bit, little-endian, data-type-policy=OVERRIDE, i-signal-type=PRIMITIVE, init-value=0, base-type=BT_CID_LVDS_Splitter_Errorstate, compu {2=Cx2_HW_error (CM_CID_LVDS_Splitter_Errorstate_Cx2_HW_error), 0=Cx0_no_error (CM_CID_LVDS_Splitter_Errorstate_Cx0_no_error), 1=Cx1_SW_error (CM_CID_LVDS_Splitter_Errorstate_Cx1_SW_error)}, range raw 0..2, transfer-property=PENDING, to HCP3_IONode(timeout 5 s)  # CID_LVDS_Splitter_Errorstate = 0 no error detected CID_LVDS_Splitter_Errorstate = 1 SW error detected CID_LVDS_Splitter_Errorstate = 2 HW error detected
          signal CID_ShutterFoil_Errorstate_XIX_CID_01_XIX_HCP3_CANFD01: start 262, 2 bit, little-endian, data-type-policy=OVERRIDE, i-signal-type=PRIMITIVE, init-value=0, base-type=BT_CID_ShutterFoil_Errorstate, compu {2=Cx2_HW_error (CM_CID_ShutterFoil_Errorstate_Cx2_HW_error), 1=Cx1_SW_error (CM_CID_ShutterFoil_Errorstate_Cx1_SW_error), 0=Cx0_no_error (CM_CID_ShutterFoil_Errorstate_Cx0_no_error)}, range raw 0..2, transfer-property=PENDING, to HCP3_IONode(timeout 5 s)  # CID_ShutterFoil_Errorstate = 0 no error detected CID_ShutterFoil_Errorstate = 1 SW error detected CID_ShutterFoil_Errorstate = 2 HW error detected
          signal CID_Proximity_Errorstate_XIX_CID_01_XIX_HCP3_CANFD01: start 264, 2 bit, little-endian, data-type-policy=OVERRIDE, i-signal-type=PRIMITIVE, init-value=0, base-type=BT_CID_Proximity_Errorstate, compu {1=Cx1_SW_error (CM_CID_Proximity_Errorstate_Cx1_SW_error), 2=Cx2_HW_error (CM_CID_Proximity_Errorstate_Cx2_HW_error), 0=Cx0_no_error (CM_CID_Proximity_Errorstate_Cx0_no_error)}, range raw 0..2, transfer-property=PENDING, to HCP3_IONode(timeout 5 s)  # CID_Proximity_Errorstate = 0 no error detected CID_Proximity_Errorstate = 1 SW error detected CID_Proximity_Errorstate = 2 HW error detected
          signal CID_Slider_Errorstate_XIX_CID_01_XIX_HCP3_CANFD01: start 266, 2 bit, little-endian, data-type-policy=OVERRIDE, i-signal-type=PRIMITIVE, init-value=0, base-type=BT_CID_Slider_Errorstate, compu {1=Cx1_SW_error (CM_CID_Slider_Errorstate_Cx1_SW_error), 0=Cx0_no_error (CM_CID_Slider_Errorstate_Cx0_no_error), 2=Cx2_HW_error (CM_CID_Slider_Errorstate_Cx2_HW_error)}, range raw 0..2, transfer-property=PENDING, to HCP3_IONode(timeout 5 s)  # CID_Slider_Errorstate = 0 no error detected CID_Slider_Errorstate = 1 SW error detected CID_Slider_Errorstate = 2 HW error detected
          signal CID_Backlight_ShortCircuit_XIX_CID_01_XIX_HCP3_CANFD01: start 268, 1 bit, little-endian, data-type-policy=OVERRIDE, i-signal-type=PRIMITIVE, init-value=0, base-type=BT_CID_Backlight_ShortCircuit, invalid-value=Invalid_CID_Backlight_ShortCircuit_XIX_CID_01_XIX_HCP3_CANFD01:1, compu {1=Cx1_Fehler (CM_CID_Backlight_ShortCircuit_Cx1_Fehler), 0=Cx0_normal (CM_CID_Backlight_ShortCircuit_Cx0_normal)}, range raw 0..1, transfer-property=TRIGGERED-ON-CHANGE-WITHOUT-REPETITION, to HCP3_IONode(timeout 5 s)  # Backlight has a short circuit
          signal CID_Backlight_OpenCircuit_XIX_CID_01_XIX_HCP3_CANFD01: start 269, 1 bit, little-endian, data-type-policy=OVERRIDE, i-signal-type=PRIMITIVE, init-value=0, base-type=BT_CID_Backlight_OpenCircuit, invalid-value=Invalid_CID_Backlight_OpenCircuit_XIX_CID_01_XIX_HCP3_CANFD01:1, compu {1=Cx1_Fehler (CM_CID_Backlight_OpenCircuit_Cx1_Fehler), 0=Cx0_normal (CM_CID_Backlight_OpenCircuit_Cx0_normal)}, range raw 0..1, transfer-property=TRIGGERED-ON-CHANGE-WITHOUT-REPETITION, to HCP3_IONode(timeout 5 s)  # With current measurements, at least one LED line is broken
          signal CID_SW_inconsistent_XIX_CID_01_XIX_HCP3_CANFD01: start 270, 1 bit, little-endian, data-type-policy=OVERRIDE, i-signal-type=PRIMITIVE, init-value=0, base-type=BT_CID_SW_inconsistent, invalid-value=Invalid_CID_SW_inconsistent_XIX_CID_01_XIX_HCP3_CANFD01:1, compu {1=Cx1_Fehler (CM_CID_SW_inconsistent_Cx1_Fehler), 0=Cx0_Kein_Fehler (CM_CID_SW_inconsistent_Cx0_Kein_Fehler)}, range raw 0..1, transfer-property=PENDING, to HCP3_IONode(timeout 5 s)  # SW_inconsistent = 1 SW Status is inconsistent - error SW_inconsistent = 0 no error - SW is consistent
          signal CID_EEPROM_Error_XIX_CID_01_XIX_HCP3_CANFD01: start 271, 1 bit, little-endian, data-type-policy=OVERRIDE, i-signal-type=PRIMITIVE, init-value=0, base-type=BT_CID_EEPROM_Error, invalid-value=Invalid_CID_EEPROM_Error_XIX_CID_01_XIX_HCP3_CANFD01:1, compu {1=Cx1_Fehler (CM_CID_EEPROM_Error_Cx1_Fehler), 0=Cx0_normal (CM_CID_EEPROM_Error_Cx0_normal)}, range raw 0..1, transfer-property=TRIGGERED-ON-CHANGE-WITHOUT-REPETITION, to HCP3_IONode(timeout 5 s)  # EEPROM error detected
          signal CID_Touchstate_XIX_CID_01_XIX_HCP3_CANFD01: start 272, 1 bit, little-endian, data-type-policy=OVERRIDE, i-signal-type=PRIMITIVE, init-value=0, base-type=BT_CID_Touchstate, compu {1=Cx1_touched (CM_CID_Touchstate_Cx1_touched), 0=Cx0_not_touched (CM_CID_Touchstate_Cx0_not_touched)}, range raw 0..1, transfer-property=TRIGGERED-ON-CHANGE-WITHOUT-REPETITION, to HCP3_IONode(timeout 5 s)  # This signal provides the current touchstate of the touchscreen (not_touched/touched).
          signal CID_HID_FetchAll_XIX_CID_01_XIX_HCP3_CANFD01: start 273, 1 bit, little-endian, data-type-policy=OVERRIDE, i-signal-type=PRIMITIVE, init-value=0, base-type=BT_CID_HID_FetchAll, compu {0=Cx0_Init (CM_CID_HID_FetchAll_Cx0_Init), 1=Cx1_Done (CM_CID_HID_FetchAll_Cx1_Done)}, range raw 0..1, transfer-property=TRIGGERED-ON-CHANGE-WITHOUT-REPETITION, to HCP3_IONode(timeout 5 s)  # HID command FetchAll received and answered
          signal CID_Input_Errorstate_XIX_CID_01_XIX_HCP3_CANFD01: start 274, 1 bit, little-endian, data-type-policy=OVERRIDE, i-signal-type=PRIMITIVE, init-value=0, base-type=BT_CID_Input_Errorstate, invalid-value=Invalid_CID_Input_Errorstate_XIX_CID_01_XIX_HCP3_CANFD01:1, compu {1=Cx1_Fehler (CM_CID_Input_Errorstate_Cx1_Fehler), 0=Cx0_normal (CM_CID_Input_Errorstate_Cx0_normal)}, range raw 0..1, transfer-property=TRIGGERED-ON-CHANGE-WITHOUT-REPETITION  # Display unit has detected an error which could lead to no or incorrect user inputs
          signal CID_Image_Errorstate_XIX_CID_01_XIX_HCP3_CANFD01: start 275, 1 bit, little-endian, data-type-policy=OVERRIDE, i-signal-type=PRIMITIVE, init-value=0, base-type=BT_CID_Image_Errorstate, invalid-value=Invalid_CID_Image_Errorstate_XIX_CID_01_XIX_HCP3_CANFD01:1, compu {1=Cx1_Fehler (CM_CID_Image_Errorstate_Cx1_Fehler), 0=Cx0_normal (CM_CID_Image_Errorstate_Cx0_normal)}, range raw 0..1, transfer-property=TRIGGERED-ON-CHANGE-WITHOUT-REPETITION  # Display unit has detected an error which could lead to no or incorrect image display.
          signal CID_Input_ErrorState_TNCTOC_XIX_CID_01_XIX_HCP3_CANFD01: start 276, 1 bit, little-endian, data-type-policy=OVERRIDE, i-signal-type=PRIMITIVE, init-value=1, base-type=BT_CID_Input_ErrorState_TNCTOC, compu {0=Cx0_completed (CM_CID_Input_ErrorState_TNCTOC_Cx0_completed), 1=Cx1_not_completed (CM_CID_Input_ErrorState_TNCTOC_Cx1_not_completed)}, range raw 0..1, transfer-property=PENDING  # TestNotCompletedThisOperationCycle for signal CID_Input_ErrorState
      frame CID_DispCtrlCID_Req_FD_XIX_HCP3_CANFD01: id 0x1CD02268, to HCP3_IONode, frame-length=64, can-addressing-mode=EXTENDED, can-frame-rx-behavior=CAN-FD, can-frame-tx-behavior=CAN-FD
        n pdu CID_DispCtrlCID_Req_FD_XIX_HCP3_CANFD01: length=64
      frame CID_DispCtrlCID_Resp_FD_XIX_HCP3_CANFD01: id 0x1CD22268, from HCP3_IONode, frame-length=64, can-addressing-mode=EXTENDED, can-frame-rx-behavior=CAN-FD, can-frame-tx-behavior=CAN-FD
        n pdu CID_DispCtrlCID_Resp_FD_XIX_HCP3_CANFD01: length=64
      frame CID_DispInpCID_Req_FD_XIX_HCP3_CANFD01: id 0x1CD0226B, to HCP3_IONode, frame-length=64, can-addressing-mode=EXTENDED, can-frame-rx-behavior=CAN-FD, can-frame-tx-behavior=CAN-FD
        n pdu CID_DispInpCID_Req_FD_XIX_HCP3_CANFD01: length=64
      frame CID_DispInpCID_Resp_FD_XIX_HCP3_CANFD01: id 0x1CD2226B, from HCP3_IONode, frame-length=64, can-addressing-mode=EXTENDED, can-frame-rx-behavior=CAN-FD, can-frame-tx-behavior=CAN-FD
        n pdu CID_DispInpCID_Resp_FD_XIX_HCP3_CANFD01: length=64
      frame CID_KeyInpCID_Req_FD_XIX_HCP3_CANFD01: id 0x1CD0226E, to HCP3_IONode, frame-length=64, can-addressing-mode=EXTENDED, can-frame-rx-behavior=CAN-FD, can-frame-tx-behavior=CAN-FD
        n pdu CID_KeyInpCID_Req_FD_XIX_HCP3_CANFD01: length=64
      frame CID_KeyInpCID_Resp_FD_XIX_HCP3_CANFD01: id 0x1CD2226E, from HCP3_IONode, frame-length=64, can-addressing-mode=EXTENDED, can-frame-rx-behavior=CAN-FD, can-frame-tx-behavior=CAN-FD
        n pdu CID_KeyInpCID_Resp_FD_XIX_HCP3_CANFD01: length=64
      frame CID_VA_Communication_Init_XIX_HCP3_CANFD01: id 0x16A9558A, to HCP3_IONode, frame-length=20, can-addressing-mode=EXTENDED, can-frame-rx-behavior=CAN-FD, can-frame-tx-behavior=CAN-FD
        pdu CID_VA_Communication_Init_XIX_HCP3_CANFD01: length=20, minimum-delay=0.1, transmission-mode-true-timing={cyclic-timing={time-offset=0.0, time-period=1.0}, event-controlled-timing={number-of-repetitions=0, repetition-period=0.0}}, unused-bit-pattern=0
          signal CID_VA_Communication_Init_XIX_CID_VA_Communication_Init_XIX_HCP3_CANFD01: start 0, 136 bit, opaque, data-type-policy=OVERRIDE, i-signal-type=ARRAY, init-value=17 x 0, base-type=BT_CID_VA_Communication_Init, implementation-data-type=CID_VA_Communication_Init, transfer-property=TRIGGERED-ON-CHANGE-WITHOUT-REPETITION, to HCP3_IONode(timeout 5 s)  # This data channel is used for display video authentication of CID.
      frame CID_VA_Communication_Init_Ack_XIX_HCP3_CANFD01: id 0x16A95566, to HCP3_IONode, frame-length=20, can-addressing-mode=EXTENDED, can-frame-rx-behavior=CAN-FD, can-frame-tx-behavior=CAN-FD
        pdu CID_VA_Communication_Init_Ack_XIX_HCP3_CANFD01: length=20, minimum-delay=0.1, transmission-mode-true-timing={cyclic-timing={time-offset=0.0, time-period=1.0}, event-controlled-timing={number-of-repetitions=0, repetition-period=0.0}}, unused-bit-pattern=0
          signal CID_VA_Communication_Init_Ack_XIX_CID_VA_Communication_Init_Ack_XIX_HCP3_CANFD01: start 0, 136 bit, opaque, data-type-policy=OVERRIDE, i-signal-type=ARRAY, init-value=17 x 0, base-type=BT_CID_VA_Communication_Init_Ack, implementation-data-type=CID_VA_Communication_Init_Ack, transfer-property=TRIGGERED-ON-CHANGE-WITHOUT-REPETITION, to HCP3_IONode(timeout 5 s)  # Init communication acknowledge of video-authentication for CID
      frame CID_VA_Response_XIX_HCP3_CANFD01: id 0x16A95567, to HCP3_IONode, frame-length=64, can-addressing-mode=EXTENDED, can-frame-rx-behavior=CAN-FD, can-frame-tx-behavior=CAN-FD
        pdu CID_VA_Response_XIX_HCP3_CANFD01: length=64, minimum-delay=0.1, transmission-mode-true-timing={cyclic-timing={time-offset=0.0, time-period=1.0}, event-controlled-timing={number-of-repetitions=0, repetition-period=0.0}}, unused-bit-pattern=0
          signal CID_VA_Response_XIX_CID_VA_Response_XIX_HCP3_CANFD01: start 0, 512 bit, opaque, data-type-policy=OVERRIDE, i-signal-type=ARRAY, init-value=64 x 0, base-type=BT_CID_VA_Response, implementation-data-type=CID_VA_Response, transfer-property=TRIGGERED-ON-CHANGE-WITHOUT-REPETITION, to HCP3_IONode(timeout 5 s)  # Video-authentication response from CID
      frame ClampControl_01_XIX_HCP3_CANFD01: id 0x12DD54FE, from HCP3_IONode, frame-length=8, can-addressing-mode=EXTENDED, can-frame-rx-behavior=CAN-FD, can-frame-tx-behavior=CAN-FD
        pdu ClampControl_01_XIX_HCP3_CANFD01: length=8, minimum-delay=0.01, transmission-mode-true-timing={cyclic-timing={time-offset=0.0, time-period=0.1}, event-controlled-timing={number-of-repetitions=0, repetition-period=0.0}}, unused-bit-pattern=0
          signal ClampControl_01_CRC_XIX_ClampControl_01_XIX_HCP3_CANFD01: start 0, 8 bit, little-endian, data-type-policy=OVERRIDE, i-signal-type=PRIMITIVE, init-value=0, base-type=BT_ClampControl_01_CRC, compu {phys=raw for raw 0..255}, range phys 0..255, raw 0..255, transfer-property=TRIGGERED-ON-CHANGE  # Für MLB: Berechnung siehe Lastenheft "Kommunikationsabsicherung für FlexRay und CAN" Ab MQB und MLBevo: Berechnung siehe Lastenheft "End-to-End Kommunikationsabsicherung" Endwerte siehe Begleitdokument "S-PDU Kennungsfolgen"
          signal ClampControl_01_BZ_XIX_ClampControl_01_XIX_HCP3_CANFD01: start 8, 4 bit, little-endian, data-type-policy=OVERRIDE, i-signal-type=PRIMITIVE, init-value=0, base-type=BT_ClampControl_01_BZ, compu {phys=raw for raw 0..15}, range phys 0..15, raw 0..15, transfer-property=TRIGGERED-ON-CHANGE  # 4bit Botschaftszähler, wird mit jeder Sendebotschaft inkrementiert
          signal KST_Warn_P1_ZAT_def_XIX_ClampControl_01_XIX_HCP3_CANFD01: start 12, 1 bit, little-endian, data-type-policy=OVERRIDE, i-signal-type=PRIMITIVE, init-value=0, base-type=BT_KST_Warn_P1_ZAT_def, compu {1=Cx1_defekt (CM_KST_Warn_P1_ZAT_def_Cx1_defekt), 0=Cx0_nicht_defekt (CM_KST_Warn_P1_ZAT_def_Cx0_nicht_defekt)}, range raw 0..1, transfer-property=TRIGGERED-ON-CHANGE  # Kombi Prio Warnung Klemmensteuerung Zündschloß defekt, Service aufsuchen!
          signal KST_Warn_P2_ZAT_def_XIX_ClampControl_01_XIX_HCP3_CANFD01: start 13, 1 bit, little-endian, data-type-policy=OVERRIDE, i-signal-type=PRIMITIVE, init-value=0, base-type=BT_KST_Warn_P2_ZAT_def, compu {1=Cx1_defekt (CM_KST_Warn_P2_ZAT_def_Cx1_defekt), 0=Cx0_nicht_defekt (CM_KST_Warn_P2_ZAT_def_Cx0_nicht_defekt)}, range raw 0..1, transfer-property=TRIGGERED-ON-CHANGE  # Kombi Prio Warnung Klemmensteuerung Zündschloß defekt!
          signal KST_Deaktivierungs_Trigger_XIX_ClampControl_01_XIX_HCP3_CANFD01: start 14, 2 bit, little-endian, data-type-policy=OVERRIDE, i-signal-type=PRIMITIVE, init-value=0, base-type=BT_KST_Deaktivierungs_Trigger, compu {0=Cx0_KEINE_DEAKTIVIERUNG_ERFOLGT_0 (CM_KST_Deaktivierungs_Trigger_Cx0_KEINE_DEAKTIVIERUNG_ERFOLGT_0), 1=Cx1_DEAKTIVIERUNG_UEBER_ZAT_1 (CM_KST_Deaktivierungs_Trigger_Cx1_DEAKTIVIERUNG_UEBER_ZAT_1), 2=Cx2_DEAKTIVIERUNG_VEREINFACHT_VLK_2 (CM_KST_Deaktivierungs_Trigger_Cx2_DEAKTIVIERUNG_VEREINFACHT_VLK_2)}, range raw 0..2, transfer-property=TRIGGERED-ON-CHANGE  # Ausgabe des Deaktivierungstriggers für Funktionen mit Goodbye-Szenario zur Unterscheidung zwischen manueller und automatischer Deaktivierung bei Fzg.-Verlassen
          signal KST_Kl_S_XIX_ClampControl_01_XIX_HCP3_CANFD01: start 16, 1 bit, little-endian, data-type-policy=OVERRIDE, i-signal-type=PRIMITIVE, init-value=0, base-type=BT_KST_Kl_S, compu {0=Cx0_aus (CM_KST_Kl_S_Cx0_aus), 1=Cx1_S_Kontakt_ein (CM_KST_Kl_S_Cx1_S_Kontakt_ein)}, range raw 0..1, transfer-property=TRIGGERED-ON-CHANGE  # Klemme S: S-Kontakt (Schluessel steckt)
          signal KST_KL_15_XIX_ClampControl_01_XIX_HCP3_CANFD01: start 17, 1 bit, little-endian, data-type-policy=OVERRIDE, i-signal-type=PRIMITIVE, init-value=0, base-type=BT_KST_KL_15, compu {0=Cx0_aus (CM_KST_KL_15_Cx0_aus), 1=Cx1_ein (CM_KST_KL_15_Cx1_ein)}, range raw 0..1, transfer-property=TRIGGERED-ON-CHANGE  # Klemme 15: Zuendung (SW-Kl.15)
          signal KST_Kl_50_Startanforderung_XIX_ClampControl_01_XIX_HCP3_CANFD01: start 18, 1 bit, little-endian, data-type-policy=OVERRIDE, i-signal-type=PRIMITIVE, init-value=0, base-type=BT_KST_Kl_50_Startanforderung, compu {1=Cx1_KL50_ein_Startwunsch_Fahrer (CM_KST_Kl_50_Startanforderung_Cx1_KL50_ein_Startwunsch_Fahrer), 0=Cx0_aus (CM_KST_Kl_50_Startanforderung_Cx0_aus)}, range raw 0..1, transfer-property=TRIGGERED-ON-CHANGE  # Klemme 50: Startwunsch Fahrer
          signal KST_Sonderzustand_Status_XIX_ClampControl_01_XIX_HCP3_CANFD01: start 19, 2 bit, little-endian, data-type-policy=OVERRIDE, i-signal-type=PRIMITIVE, init-value=0, base-type=BT_KST_Sonderzustand_Status, invalid-value=Invalid_KST_Sonderzustand_Status_XIX_ClampControl_01_XIX_HCP3_CANFD01:3, compu {3=Cx3_Fehler (CM_KST_Sonderzustand_Status_Cx3_Fehler), 0=Cx0_Init (CM_KST_Sonderzustand_Status_Cx0_Init), 1=Cx1_Uebergang_neue_Anforderung (CM_KST_Sonderzustand_Status_Cx1_Uebergang_neue_Anforderung), 2=Cx2_Aktiv (CM_KST_Sonderzustand_Status_Cx2_Aktiv)}, range raw 0..3, transfer-property=TRIGGERED-ON-CHANGE  # Hiermit wird signalisiert, dass eine Sonderfunktion aktiv ist und die Klemme 15 durch diese angefordert wurde bzw. ein Übergang von Sonderfunktionen stattfindet
          signal KST_Ausstiegswunsch_Status_XIX_ClampControl_01_XIX_HCP3_CANFD01: start 21, 1 bit, little-endian, data-type-policy=OVERRIDE, i-signal-type=PRIMITIVE, init-value=0, base-type=BT_KST_Ausstiegswunsch_Status, compu {1=Cx1_AUSSTIEGSWUNSCH_AKTIV_1 (CM_KST_Ausstiegswunsch_Status_Cx1_AUSSTIEGSWUNSCH_AKTIV_1), 0=Cx0_KEIN_AUSSTIEGSWUNSCH_AKTIV_0 (CM_KST_Ausstiegswunsch_Status_Cx0_KEIN_AUSSTIEGSWUNSCH_AKTIV_0)}, range raw 0..1, transfer-property=TRIGGERED-ON-CHANGE  # Ausstiegswunsch über den Funktionen mit Goodbye-Szenario zentral getriggert werden können.
          signal KST_BulbCheckReq_XIX_ClampControl_01_XIX_HCP3_CANFD01: start 23, 1 bit, little-endian, data-type-policy=OVERRIDE, i-signal-type=PRIMITIVE, init-value=0, base-type=BT_KST_BulbCheckReq, compu {0=Cx0_Keine_Anfrage (CM_KST_BulbCheckReq_Cx0_Keine_Anfrage), 1=Cx1_Anfrage (CM_KST_BulbCheckReq_Cx1_Anfrage)}, range raw 0..1, transfer-property=TRIGGERED-ON-CHANGE  # Signal fordert eine Lampenaufprüfung (Bulb Check) an.
          signal KST_Kl_X_XIX_ClampControl_01_XIX_HCP3_CANFD01: start 24, 1 bit, little-endian, data-type-policy=OVERRIDE, i-signal-type=PRIMITIVE, init-value=0, base-type=BT_KST_Kl_X, compu {0=Cx0_aus (CM_KST_Kl_X_Cx0_aus), 1=Cx1_ein (CM_KST_Kl_X_Cx1_ein)}, range raw 0..1, transfer-property=TRIGGERED-ON-CHANGE  # Ausgabe der Klemme 75 aus Kompatibilitätsgründen für COP-Übernahmen aus MEB.
          signal KST_Ausparken_Betrieb_XIX_ClampControl_01_XIX_HCP3_CANFD01: start 25, 1 bit, little-endian, data-type-policy=OVERRIDE, i-signal-type=PRIMITIVE, init-value=0, base-type=BT_KST_Ausparken_Betrieb, compu {0=Cx0_kein_Betrieb (CM_KST_Ausparken_Betrieb_Cx0_kein_Betrieb), 1=Cx1_Ausparkvorgang_aktiv (CM_KST_Ausparken_Betrieb_Cx1_Ausparkvorgang_aktiv)}, range raw 0..1, transfer-property=TRIGGERED-ON-CHANGE  # Anforderung zur erneuten Lampenaufprüfung und Anzeige von Warnhinweisen nach einem pilotierten Ausparkvorgang (Trigger: fallende Flanke)
          signal KST_Fahrerhinweis_1_XIX_ClampControl_01_XIX_HCP3_CANFD01: start 26, 1 bit, little-endian, data-type-policy=OVERRIDE, i-signal-type=PRIMITIVE, init-value=0, base-type=BT_KST_Fahrerhinweis_1, compu {0=Cx0_inaktiv (CM_KST_Fahrerhinweis_1_Cx0_inaktiv), 1=Cx1_aktiv (CM_KST_Fahrerhinweis_1_Cx1_aktiv)}, range raw 0..1, transfer-property=TRIGGERED-ON-CHANGE  # Signalisierung Fahrerhinweis 1 der Klemmensteuerung an das Kombi
          signal KST_Fahrerhinweis_2_XIX_ClampControl_01_XIX_HCP3_CANFD01: start 27, 1 bit, little-endian, data-type-policy=OVERRIDE, i-signal-type=PRIMITIVE, init-value=0, base-type=BT_KST_Fahrerhinweis_2, compu {0=Cx0_inaktiv (CM_KST_Fahrerhinweis_2_Cx0_inaktiv), 1=Cx1_aktiv (CM_KST_Fahrerhinweis_2_Cx1_aktiv)}, range raw 0..1, transfer-property=TRIGGERED-ON-CHANGE  # Signalisierung Fahrerhinweis 2 der Klemmensteuerung an das Kombi
          signal KST_Fahrerhinweis_3_XIX_ClampControl_01_XIX_HCP3_CANFD01: start 28, 1 bit, little-endian, data-type-policy=OVERRIDE, i-signal-type=PRIMITIVE, init-value=0, base-type=BT_KST_Fahrerhinweis_3, compu {0=Cx0_inaktiv (CM_KST_Fahrerhinweis_3_Cx0_inaktiv), 1=Cx1_aktiv (CM_KST_Fahrerhinweis_3_Cx1_aktiv)}, range raw 0..1, transfer-property=TRIGGERED-ON-CHANGE  # Signalisierung Fahrerhinweis 3 der Klemmensteuerung an das Kombi
          signal KST_Fahrerhinweis_4_XIX_ClampControl_01_XIX_HCP3_CANFD01: start 29, 1 bit, little-endian, data-type-policy=OVERRIDE, i-signal-type=PRIMITIVE, init-value=0, base-type=BT_KST_Fahrerhinweis_4, compu {0=Cx0_inaktiv (CM_KST_Fahrerhinweis_4_Cx0_inaktiv), 1=Cx1_aktiv (CM_KST_Fahrerhinweis_4_Cx1_aktiv)}, range raw 0..1, transfer-property=TRIGGERED-ON-CHANGE  # Signalisierung Fahrerhinweis 4 der Klemmensteuerung an das Kombi
          signal KST_Fahrerhinweis_5_XIX_ClampControl_01_XIX_HCP3_CANFD01: start 30, 1 bit, little-endian, data-type-policy=OVERRIDE, i-signal-type=PRIMITIVE, init-value=0, base-type=BT_KST_Fahrerhinweis_5, compu {0=Cx0_inaktiv (CM_KST_Fahrerhinweis_5_Cx0_inaktiv), 1=Cx1_aktiv (CM_KST_Fahrerhinweis_5_Cx1_aktiv)}, range raw 0..1, transfer-property=TRIGGERED-ON-CHANGE  # Anzeigesignal für RemoteStart
          signal KST_Fahrerhinweis_6_XIX_ClampControl_01_XIX_HCP3_CANFD01: start 31, 1 bit, little-endian, data-type-policy=OVERRIDE, i-signal-type=PRIMITIVE, init-value=0, base-type=BT_KST_Fahrerhinweis_6, compu {0=Cx0_inaktiv (CM_KST_Fahrerhinweis_6_Cx0_inaktiv), 1=Cx1_aktiv (CM_KST_Fahrerhinweis_6_Cx1_aktiv)}, range raw 0..1, transfer-property=TRIGGERED-ON-CHANGE  # Signal aktiviert die Kombi-Anzeigeinstrumente (Drehzahl, Tankinhalt, Kühlmitteltemperatur) während aktiviertem RemoteStart-Betrieb
          signal KST_Txt_Panikabschaltung_XIX_ClampControl_01_XIX_HCP3_CANFD01: start 34, 1 bit, little-endian, data-type-policy=OVERRIDE, i-signal-type=PRIMITIVE, init-value=0, base-type=BT_KST_Txt_Panikabschaltung, compu {0=Cx0_Aus (CM_KST_Txt_Panikabschaltung_Cx0_Aus), 1=Cx1_Ein (CM_KST_Txt_Panikabschaltung_Cx1_Ein)}, range raw 0..1, transfer-property=TRIGGERED-ON-CHANGE  # Text: 'Notabschaltung''
          signal KST_Anf_Klemmenfreigabe_ELV_XIX_ClampControl_01_XIX_HCP3_CANFD01: start 41, 1 bit, little-endian, data-type-policy=OVERRIDE, i-signal-type=PRIMITIVE, init-value=0, base-type=BT_KST_Anf_Klemmenfreigabe_ELV, compu {0=Cx0_nicht_angefordert (CM_KST_Anf_Klemmenfreigabe_ELV_Cx0_nicht_angefordert), 1=Cx1_angefordert (CM_KST_Anf_Klemmenfreigabe_ELV_Cx1_angefordert)}, range raw 0..1, transfer-property=TRIGGERED-ON-CHANGE  # Klemmensteuerung fordert Klemmen-Freigabe durch die ELV an.
          signal KST_aut_Abschaltung_Zuendung_XIX_ClampControl_01_XIX_HCP3_CANFD01: start 42, 1 bit, little-endian, data-type-policy=OVERRIDE, i-signal-type=PRIMITIVE, init-value=0, base-type=BT_KST_aut_Abschaltung_Zuendung, compu {1=Cx1_Zuendung_wird_bei_Verl_deaktiviert (CM_KST_aut_Abschaltung_Zuendung_Cx1_Zuendung_wird_bei_Verl_deaktiviert), 0=Cx0_Zuendung_wird_bei_Verl_nicht_deaktiviert (CM_KST_aut_Abschaltung_Zuendung_Cx0_Zuendung_wird_bei_Verl_nicht_deaktiviert)}, range raw 0..1, transfer-property=TRIGGERED-ON-CHANGE  # Falls bei eingeschalteter Zündung das Abblendlicht aktiv war, muss nach der automatischen Abschaltung der Kl_15 & Kl_S, dass Standlicht aktiv bleiben. Das Signal sendet die Information, dass eine automatische Abschaltung der Kl_15 und Kl_S erfogt.
          signal KST_StPtAcvReq_XIX_ClampControl_01_XIX_HCP3_CANFD01: start 43, 2 bit, little-endian, data-type-policy=OVERRIDE, i-signal-type=PRIMITIVE, init-value=0, base-type=BT_KST_StPtAcvReq, compu {0=Cx0_NoActivationRequest (CM_KST_StPtAcvReq_Cx0_NoActivationRequest), 2=Cx2_CurrentActivationRequest (CM_KST_StPtAcvReq_Cx2_CurrentActivationRequest), 1=Cx1_StoredActivationRequest (CM_KST_StPtAcvReq_Cx1_StoredActivationRequest)}, range raw 0..2, transfer-property=TRIGGERED-ON-CHANGE  # ZAT-activation-demand
          signal KST_StPtDeacReq_XIX_ClampControl_01_XIX_HCP3_CANFD01: start 45, 1 bit, little-endian, data-type-policy=OVERRIDE, i-signal-type=PRIMITIVE, init-value=0, base-type=BT_KST_StPtDeacReq, compu {0=Cx0_NoRequest (CM_KST_StPtDeacReq_Cx0_NoRequest), 1=Cx1_RequestDeactivatePowertrain (CM_KST_StPtDeacReq_Cx1_RequestDeactivatePowertrain)}, range raw 0..1, transfer-property=TRIGGERED-ON-CHANGE  # Anforderung Deaktivierung des Antriebsstrangs durch Klemmensteuerung
          signal KST_ZAT_betaetigt_XIX_ClampControl_01_XIX_HCP3_CANFD01: start 46, 1 bit, little-endian, data-type-policy=OVERRIDE, i-signal-type=PRIMITIVE, init-value=0, base-type=BT_KST_ZAT_betaetigt, compu {0=Cx0_Aus (CM_KST_ZAT_betaetigt_Cx0_Aus), 1=Cx1_Ein (CM_KST_ZAT_betaetigt_Cx1_Ein)}, range raw 0..1, transfer-property=TRIGGERED-ON-CHANGE  # Zündanlass-Taster (ZAT) betätigt
          signal KST_ComfortReadyStatus_XIX_ClampControl_01_XIX_HCP3_CANFD01: start 47, 1 bit, little-endian, data-type-policy=OVERRIDE, i-signal-type=PRIMITIVE, init-value=0, base-type=BT_KST_ComfortReadyStatus, compu {1=Cx1_ComfortReadyStatus_ein (CM_KST_ComfortReadyStatus_Cx1_ComfortReadyStatus_ein), 0=Cx0_aus (CM_KST_ComfortReadyStatus_Cx0_aus)}, range raw 0..1, transfer-property=TRIGGERED-ON-CHANGE  # Zustand des ComfortReadyStatus über den Komfortfunktionen aktiviert werden können.
          signal KST_Sonderzustand_Anforderung_XIX_ClampControl_01_XIX_HCP3_CANFD01: start 48, 5 bit, little-endian, data-type-policy=OVERRIDE, i-signal-type=PRIMITIVE, init-value=0, base-type=BT_KST_Sonderzustand_Anforderung, invalid-value=Invalid_KST_Sonderzustand_Anforderung_XIX_ClampControl_01_XIX_HCP3_CANFD01:31, compu {31=Cx1f_Fehler (CM_KST_Sonderzustand_Anforderung_Cx1f_Fehler), 11=Cxb_MotorWeiterlaufSchaltung (CM_KST_Sonderzustand_Anforderung_Cxb_MotorWeiterlaufSchaltung), 7=Cx7_Klemme15ViaDiagnose (CM_KST_Sonderzustand_Anforderung_Cx7_Klemme15ViaDiagnose), 10=Cxa_AnhaengerAnkuppelAssistent (CM_KST_Sonderzustand_Anforderung_Cxa_AnhaengerAnkuppelAssistent), 3=Cx3_IntelligentParkAssist (CM_KST_Sonderzustand_Anforderung_Cx3_IntelligentParkAssist), 6=Cx6_Einfrierschutz (CM_KST_Sonderzustand_Anforderung_Cx6_Einfrierschutz), 1=Cx1_RemoteStart (CM_KST_Sonderzustand_Anforderung_Cx1_RemoteStart), 4=Cx4_TrainiertesParken (CM_KST_Sonderzustand_Anforderung_Cx4_TrainiertesParken), 9=Cx9_ParkHausPilot (CM_KST_Sonderzustand_Anforderung_Cx9_ParkHausPilot), 8=Cx8_RueckwandklappenSicherungPDC (CM_KST_Sonderzustand_Anforderung_Cx8_RueckwandklappenSicherungPDC), 5=Cx5_OnlineRemoteUpdate (CM_KST_Sonderzustand_Anforderung_Cx5_OnlineRemoteUpdate), 2=Cx2_RemoteParkAssist (CM_KST_Sonderzustand_Anforderung_Cx2_RemoteParkAssist), 0=Cx0_Init (CM_KST_Sonderzustand_Anforderung_Cx0_Init)}, range raw 0..31, transfer-property=TRIGGERED-ON-CHANGE  # Hiermit wird die aktive bzw. aktuell angeforderte (s. KST_Sonderzustand_Status) Sonderfunktion identifiziert
          signal KST_WFS_Fahrfreigabe_Anforderung_XIX_ClampControl_01_XIX_HCP3_CANFD01: start 53, 2 bit, little-endian, data-type-policy=OVERRIDE, i-signal-type=PRIMITIVE, init-value=0, base-type=BT_KST_WFS_Fahrfreigabe_Anforderung, compu {2=Cx2_Eingeschraenkt (CM_KST_WFS_Fahrfreigabe_Anforderung_Cx2_Eingeschraenkt), 1=Cx1_Uneingeschraenkt (CM_KST_WFS_Fahrfreigabe_Anforderung_Cx1_Uneingeschraenkt), 0=Cx0_Keine (CM_KST_WFS_Fahrfreigabe_Anforderung_Cx0_Keine)}, range raw 0..2, transfer-property=TRIGGERED-ON-CHANGE  # Hiermit wird den Wegfahrsperren-Teilnehmern signalisiert welche Art der Fahrfreigabe von der anfordernden Sonderfunktion benötigt wird
          mapping SG_ClampControl_01_XIX_HCP3_CANFD01: i-signal-group=SG_ClampControl_01_XIX_HCP3_CANFD01, transfer-property=TRIGGERED-ON-CHANGE
          signal ISignalVoid_ClampControl_01_XIX_HCP3_CANFD01_0: start 22, 1 bit, little-endian, system signal SignalVoid_ClampControl_01_0, data-type-policy=OVERRIDE, i-signal-type=PRIMITIVE, base-type=BT_SignalVoid, transfer-property=PENDING
          signal ISignalVoid_ClampControl_01_XIX_HCP3_CANFD01_1: start 32, 2 bit, little-endian, system signal SignalVoid_ClampControl_01_1, data-type-policy=OVERRIDE, i-signal-type=PRIMITIVE, base-type=BT_SignalVoid, transfer-property=PENDING
          signal ISignalVoid_ClampControl_01_XIX_HCP3_CANFD01_2: start 35, 5 bit, little-endian, system signal SignalVoid_ClampControl_01_2, data-type-policy=OVERRIDE, i-signal-type=PRIMITIVE, base-type=BT_SignalVoid, transfer-property=PENDING
          signal ISignalVoid_ClampControl_01_XIX_HCP3_CANFD01_3: start 40, 1 bit, little-endian, system signal SignalVoid_ClampControl_01_3, data-type-policy=OVERRIDE, i-signal-type=PRIMITIVE, base-type=BT_SignalVoid, transfer-property=PENDING
          signal ISignalVoid_ClampControl_01_XIX_HCP3_CANFD01_4: start 55, 1 bit, little-endian, system signal SignalVoid_ClampControl_01_4, data-type-policy=OVERRIDE, i-signal-type=PRIMITIVE, base-type=BT_SignalVoid, transfer-property=PENDING
          signal ISignalVoid_ClampControl_01_XIX_HCP3_CANFD01_5: start 56, 8 bit, little-endian, system signal SignalVoid_ClampControl_01_5, data-type-policy=OVERRIDE, i-signal-type=PRIMITIVE, base-type=BT_SignalVoid, transfer-property=PENDING
      frame ClimateControl_01_XIX_HCP3_CANFD01: id 0x16A95503, from HCP3_IONode, frame-length=48, can-addressing-mode=EXTENDED, can-frame-rx-behavior=CAN-FD, can-frame-tx-behavior=CAN-FD
        pdu ClimateControl_01_XIX_HCP3_CANFD01: length=48, minimum-delay=0.025, transmission-mode-true-timing={cyclic-timing={time-offset=0.0, time-period=0.2}, event-controlled-timing={number-of-repetitions=5, repetition-period=0.1}}, unused-bit-pattern=0
          signal ClimateControl_01_CRC_XIX_ClimateControl_01_XIX_HCP3_CANFD01: start 0, 8 bit, little-endian, data-type-policy=OVERRIDE, i-signal-type=PRIMITIVE, init-value=0, base-type=BT_ClimateControl_01_CRC, compu {phys=raw for raw 0..255}, range phys 0..255, raw 0..255, transfer-property=TRIGGERED-WITHOUT-REPETITION
          signal ClimateControl_01_BZ_XIX_ClimateControl_01_XIX_HCP3_CANFD01: start 8, 4 bit, little-endian, data-type-policy=OVERRIDE, i-signal-type=PRIMITIVE, init-value=0, base-type=BT_ClimateControl_01_BZ, compu {phys=raw for raw 0..15}, range phys 0..15, raw 0..15, transfer-property=TRIGGERED-WITHOUT-REPETITION
          signal HSH_Taster_XIX_ClimateControl_01_XIX_HCP3_CANFD01: start 12, 2 bit, little-endian, data-type-policy=OVERRIDE, i-signal-type=PRIMITIVE, init-value=0, base-type=BT_HSH_Taster, compu {1=Cx1_short_push (CM_HSH_Taster_Cx1_short_push), 0=Cx0_nicht_betaetigt (CM_HSH_Taster_Cx0_nicht_betaetigt), 2=Cx2_long_push (CM_HSH_Taster_Cx2_long_push), 3=Cx3_tbd (CM_HSH_Taster_Cx3_tbd)}, range raw 0..3, transfer-property=TRIGGERED-WITHOUT-REPETITION  # An-/Abforderung Heckscheibenheizung über spezielles Tastersignal
          signal KL_Anf_AussenspiegelHzg_XIX_ClimateControl_01_XIX_HCP3_CANFD01: start 14, 1 bit, little-endian, data-type-policy=OVERRIDE, i-signal-type=PRIMITIVE, init-value=0, base-type=BT_KL_Anf_AussenspiegelHzg, compu {0=Cx0_nicht_angefordert (CM_KL_Anf_AussenspiegelHzg_Cx0_nicht_angefordert), 1=Cx1_angefordert (CM_KL_Anf_AussenspiegelHzg_Cx1_angefordert)}, range raw 0..1, transfer-property=TRIGGERED-WITHOUT-REPETITION  # Anforderung Außenspiegelheizung seitens Klimafunktion (z.B. bei Erweiterter VoKo)
          signal KL_ErwVK_Anf_XIX_ClimateControl_01_XIX_HCP3_CANFD01: start 15, 1 bit, little-endian, data-type-policy=OVERRIDE, i-signal-type=PRIMITIVE, init-value=0, base-type=BT_KL_ErwVK_Anf, compu {1=Cx1_angefordert (CM_KL_ErwVK_Anf_Cx1_angefordert), 0=Cx0_nicht_angefordert (CM_KL_ErwVK_Anf_Cx0_nicht_angefordert)}, range raw 0..1, transfer-property=TRIGGERED-WITHOUT-REPETITION  # Erweiterte Voko angefordertert / aktiv
          signal KL_Geblaese_Fond_Status_XIX_ClimateControl_01_XIX_HCP3_CANFD01: start 16, 4 bit, little-endian, data-type-policy=OVERRIDE, i-signal-type=PRIMITIVE, init-value=14, base-type=BT_KL_Geblaese_Fond_Status, invalid-value=Invalid_KL_Geblaese_Fond_Status_XIX_ClimateControl_01_XIX_HCP3_CANFD01:15, compu {15=Cxf_Fehler (CM_KL_Geblaese_Fond_Status_Cxf_Fehler), 10=Cxa_Geblaesestufe_100 (CM_KL_Geblaese_Fond_Status_Cxa_Geblaesestufe_100), 0=Cx0_Geblaese_aus (CM_KL_Geblaese_Fond_Status_Cx0_Geblaese_aus), 5=Cx5_Geblaesestufe_50 (CM_KL_Geblaese_Fond_Status_Cx5_Geblaesestufe_50), 6=Cx6_Geblaesestufe_60 (CM_KL_Geblaese_Fond_Status_Cx6_Geblaesestufe_60), 9=Cx9_Geblaesestufe_90 (CM_KL_Geblaese_Fond_Status_Cx9_Geblaesestufe_90), 2=Cx2_Geblaesestufe_20 (CM_KL_Geblaese_Fond_Status_Cx2_Geblaesestufe_20), 14=Cxe_Init (CM_KL_Geblaese_Fond_Status_Cxe_Init), 8=Cx8_Geblaesestufe_80 (CM_KL_Geblaese_Fond_Status_Cx8_Geblaesestufe_80), 7=Cx7_Geblaesestufe_70 (CM_KL_Geblaese_Fond_Status_Cx7_Geblaesestufe_70), 3=Cx3_Geblaesestufe_30 (CM_KL_Geblaese_Fond_Status_Cx3_Geblaesestufe_30), 1=Cx1_Geblaesestufe_10 (CM_KL_Geblaese_Fond_Status_Cx1_Geblaesestufe_10), 4=Cx4_Geblaesestufe_40 (CM_KL_Geblaese_Fond_Status_Cx4_Geblaesestufe_40)}, range raw 0..15, transfer-property=TRIGGERED-WITHOUT-REPETITION  # Status Geblaese
          signal KL_Geblaese_Status_XIX_ClimateControl_01_XIX_HCP3_CANFD01: start 20, 4 bit, little-endian, data-type-policy=OVERRIDE, i-signal-type=PRIMITIVE, init-value=14, base-type=BT_KL_Geblaese_Status, invalid-value=Invalid_KL_Geblaese_Status_XIX_ClimateControl_01_XIX_HCP3_CANFD01:15, compu {15=Cxf_Fehler (CM_KL_Geblaese_Status_Cxf_Fehler), 14=Cxe_Init (CM_KL_Geblaese_Status_Cxe_Init), 0=Cx0_Geblaese_aus (CM_KL_Geblaese_Status_Cx0_Geblaese_aus), 1=Cx1_Geblaesestufe_10 (CM_KL_Geblaese_Status_Cx1_Geblaesestufe_10), 2=Cx2_Geblaesestufe_20 (CM_KL_Geblaese_Status_Cx2_Geblaesestufe_20), 3=Cx3_Geblaesestufe_30 (CM_KL_Geblaese_Status_Cx3_Geblaesestufe_30), 4=Cx4_Geblaesestufe_40 (CM_KL_Geblaese_Status_Cx4_Geblaesestufe_40), 5=Cx5_Geblaesestufe_50 (CM_KL_Geblaese_Status_Cx5_Geblaesestufe_50), 6=Cx6_Geblaesestufe_60 (CM_KL_Geblaese_Status_Cx6_Geblaesestufe_60), 7=Cx7_Geblaesestufe_70 (CM_KL_Geblaese_Status_Cx7_Geblaesestufe_70), 8=Cx8_Geblaesestufe_80 (CM_KL_Geblaese_Status_Cx8_Geblaesestufe_80), 9=Cx9_Geblaesestufe_90 (CM_KL_Geblaese_Status_Cx9_Geblaesestufe_90), 10=Cxa_Geblaesestufe_100 (CM_KL_Geblaese_Status_Cxa_Geblaesestufe_100)}, range raw 0..15, transfer-property=TRIGGERED-WITHOUT-REPETITION  # Status Geblaese
          signal KL_Innen_Temp_XIX_ClimateControl_01_XIX_HCP3_CANFD01: start 24, 8 bit, little-endian, data-type-policy=OVERRIDE, i-signal-type=PRIMITIVE, init-value=254, base-type=BT_KL_Innen_Temp, invalid-value=Invalid_KL_Innen_Temp_XIX_ClimateControl_01_XIX_HCP3_CANFD01:255, compu {phys=raw*0.5-50 for raw 0..252, 255=Cxff_Fehler (CM_KL_Innen_Temp_Cxff_Fehler), 254=Cxfe_nicht_verfuegbar (CM_KL_Innen_Temp_Cxfe_nicht_verfuegbar), 253=Cxfd_nicht_verbaut (CM_KL_Innen_Temp_Cxfd_nicht_verbaut); unit Unit_DegreCelsi}, range phys -50..76 Unit_DegreCelsi, raw 0..255, unit=Unit_DegreCelsi, transfer-property=TRIGGERED-WITHOUT-REPETITION  # Innentemperatur
          signal KL_Restwaerme_aktiv_XIX_ClimateControl_01_XIX_HCP3_CANFD01: start 35, 1 bit, little-endian, data-type-policy=OVERRIDE, i-signal-type=PRIMITIVE, init-value=0, base-type=BT_KL_Restwaerme_aktiv, compu {0=Cx0_inaktiv (CM_KL_Restwaerme_aktiv_Cx0_inaktiv), 1=Cx1_aktiv (CM_KL_Restwaerme_aktiv_Cx1_aktiv)}, range raw 0..1, transfer-property=TRIGGERED-WITHOUT-REPETITION  # Signal zur Aktivierung/Deaktivierung der Wasserpumpe bei Restwärme; reduzierte IRÜ Empfindlichkeit
          signal KL_Solarluefter_aktiv_XIX_ClimateControl_01_XIX_HCP3_CANFD01: start 36, 1 bit, little-endian, data-type-policy=OVERRIDE, i-signal-type=PRIMITIVE, init-value=0, base-type=BT_KL_Solarluefter_aktiv, compu {0=Cx0_Solarluefter_nicht_aktiv (CM_KL_Solarluefter_aktiv_Cx0_Solarluefter_nicht_aktiv), 1=Cx1_Solarluefter_aktiv_auto (CM_KL_Solarluefter_aktiv_Cx1_Solarluefter_aktiv_auto) (Solarluefter_aktiv__auto)}, range raw 0..1, transfer-property=TRIGGERED-WITHOUT-REPETITION  # Betriebsstatus Solarluefter
          signal KL_STH_aktiv_XIX_ClimateControl_01_XIX_HCP3_CANFD01: start 37, 1 bit, little-endian, data-type-policy=OVERRIDE, i-signal-type=PRIMITIVE, init-value=0, base-type=BT_KL_STH_aktiv, compu {0=Cx0_Standheizung_nicht_aktiv (CM_KL_STH_aktiv_Cx0_Standheizung_nicht_aktiv), 1=Cx1_Standheizung_aktiv (CM_KL_STH_aktiv_Cx1_Standheizung_aktiv)}, range raw 0..1, transfer-property=TRIGGERED-WITHOUT-REPETITION  # Betriebsstatus Standheizung
          signal KL_STL_aktiv_XIX_ClimateControl_01_XIX_HCP3_CANFD01: start 46, 1 bit, little-endian, data-type-policy=OVERRIDE, i-signal-type=PRIMITIVE, init-value=0, base-type=BT_KL_STL_aktiv, compu {0=Cx0_Standlueftung_nicht_aktiv (CM_KL_STL_aktiv_Cx0_Standlueftung_nicht_aktiv), 1=Cx1_Standlueftung_aktiv (CM_KL_STL_aktiv_Cx1_Standlueftung_aktiv)}, range raw 0..1, transfer-property=TRIGGERED-WITHOUT-REPETITION  # Betriebsstatus Standlueftung
          signal KL_Thermomanagement_XIX_ClimateControl_01_XIX_HCP3_CANFD01: start 47, 2 bit, little-endian, data-type-policy=OVERRIDE, i-signal-type=PRIMITIVE, init-value=0, base-type=BT_KL_Thermomanagement, compu {3=Cx3_volle_Freigabe_TMM_kein_Heizbedarf (CM_KL_Thermomanagement_Cx3_volle_Freigabe_TMM_kein_Heizbedarf) (volle_Freigabe_TMM__kein_Heizbedarf), 1=Cx1_kleine_Freigabe_TMM (CM_KL_Thermomanagement_Cx1_kleine_Freigabe_TMM), 0=Cx0_keine_Freigabe_TMM_max_Heizbedarf (CM_KL_Thermomanagement_Cx0_keine_Freigabe_TMM_max_Heizbedarf) (keine_Freigabe_TMM__max_Heizbedarf), 2=Cx2_mittlere_Freigabe_TMM (CM_KL_Thermomanagement_Cx2_mittlere_Freigabe_TMM)}, range raw 0..3, transfer-property=TRIGGERED-WITHOUT-REPETITION  # Stufen des Thermomanagements; Bei Klemme 15 AUS und erkannten Timeout zum Klimabedienteil (z.B. Klimabedienteil während des Motorsteuergeräte-Kommunikations-Nachlaufs bereits im NM-Zustand ¿Bus Sleep¿) erfolgt keine Ansteuerung der Wasserpumpe durch die ITM Funktion. In dem konkreten Fall wird der definierte Initwert von der ITM-Funktion nicht als Ersatzwert verwendet. Parallel ist eine Ansteuerung zur Restwärmenutzung außerhalb der ITM-Funktion möglich.
          signal KL_Zuheizer_Freigabe_XIX_ClimateControl_01_XIX_HCP3_CANFD01: start 49, 1 bit, little-endian, data-type-policy=OVERRIDE, i-signal-type=PRIMITIVE, init-value=0, base-type=BT_KL_Zuheizer_Freigabe, compu {1=Cx1_Zuheizerfreigabe (CM_KL_Zuheizer_Freigabe_Cx1_Zuheizerfreigabe), 0=Cx0_keine_Freigabe_Zuheizer (CM_KL_Zuheizer_Freigabe_Cx0_keine_Freigabe_Zuheizer)}, range raw 0..1, transfer-property=TRIGGERED-WITHOUT-REPETITION  # Freigabe Zuheizer
          signal KL_Vorkond_Strategie_XIX_ClimateControl_01_XIX_HCP3_CANFD01: start 50, 4 bit, little-endian, data-type-policy=OVERRIDE, i-signal-type=PRIMITIVE, init-value=15, base-type=BT_KL_Vorkond_Strategie, compu {14=Cxe_Konditionierung_nicht_moeglich (CM_KL_Vorkond_Strategie_Cxe_Konditionierung_nicht_moeglich), 7=Cx7_Heizen_elektrisch (CM_KL_Vorkond_Strategie_Cx7_Heizen_elektrisch), 5=Cx5_Heizen (CM_KL_Vorkond_Strategie_Cx5_Heizen), 4=Cx4_Aktive_Kuehlung (CM_KL_Vorkond_Strategie_Cx4_Aktive_Kuehlung) (Aktive Kühlung), 1=Cx1_Spuelen (CM_KL_Vorkond_Strategie_Cx1_Spuelen) (Spülen), 3=Cx3_Kuehlwasserzirkulation (CM_KL_Vorkond_Strategie_Cx3_Kuehlwasserzirkulation) (Kühlwasserzirkulation), 13=Cxd_Strategie_nicht_berechnet (CM_KL_Vorkond_Strategie_Cxd_Strategie_nicht_berechnet), 0=Cx0_Aus (CM_KL_Vorkond_Strategie_Cx0_Aus), 6=Cx6_Reheat (CM_KL_Vorkond_Strategie_Cx6_Reheat), 2=Cx2_Kanalkuehlung (CM_KL_Vorkond_Strategie_Cx2_Kanalkuehlung) (Kanalkühlung), 8=Cx8_Heizen_verbrennungstechnisch (CM_KL_Vorkond_Strategie_Cx8_Heizen_verbrennungstechnisch), 15=Cxf_Init (CM_KL_Vorkond_Strategie_Cxf_Init)}, range raw 0..15, transfer-property=TRIGGERED-WITHOUT-REPETITION  # Strategie der Vorkonditionierung des Innenraums
          signal KRH_Soll_li_XIX_ClimateControl_01_XIX_HCP3_CANFD01: start 54, 2 bit, little-endian, data-type-policy=OVERRIDE, i-signal-type=PRIMITIVE, init-value=0, base-type=BT_KRH_Soll_li, compu {0=Cx0_aus (CM_KRH_Soll_li_Cx0_aus), 1=Cx1_Stufe_1 (CM_KRH_Soll_li_Cx1_Stufe_1), 2=Cx2_Stufe_2 (CM_KRH_Soll_li_Cx2_Stufe_2), 3=Cx3_Stufe_3 (CM_KRH_Soll_li_Cx3_Stufe_3)}, range raw 0..3, transfer-property=TRIGGERED-WITHOUT-REPETITION  # Ausgabe des Sollwertes für die Kopfraumheizung links.
          signal KRH_Soll_re_XIX_ClimateControl_01_XIX_HCP3_CANFD01: start 56, 2 bit, little-endian, data-type-policy=OVERRIDE, i-signal-type=PRIMITIVE, init-value=0, base-type=BT_KRH_Soll_re, compu {2=Cx2_Stufe_2 (CM_KRH_Soll_re_Cx2_Stufe_2), 1=Cx1_Stufe_1 (CM_KRH_Soll_re_Cx1_Stufe_1), 3=Cx3_Stufe_3 (CM_KRH_Soll_re_Cx3_Stufe_3), 0=Cx0_aus (CM_KRH_Soll_re_Cx0_aus)}, range raw 0..3, transfer-property=TRIGGERED-WITHOUT-REPETITION  # Ausgabe des Sollwertes für die Kopfraumheizung rechts.
          signal KL_SIL_Soll_re_XIX_ClimateControl_01_XIX_HCP3_CANFD01: start 58, 3 bit, little-endian, data-type-policy=OVERRIDE, i-signal-type=PRIMITIVE, init-value=0, base-type=BT_KL_SIL_Soll_re, compu {phys=raw for raw 0..6}, range phys 0..6, raw 0..6, transfer-property=TRIGGERED-WITHOUT-REPETITION  # Einstellung Sitzlüftung Beifahrer (0...6)
          signal KL_SIL_Soll_li_XIX_ClimateControl_01_XIX_HCP3_CANFD01: start 61, 3 bit, little-endian, data-type-policy=OVERRIDE, i-signal-type=PRIMITIVE, init-value=0, base-type=BT_KL_SIL_Soll_li, compu {phys=raw for raw 0..6}, range phys 0..6, raw 0..6, transfer-property=TRIGGERED-WITHOUT-REPETITION  # Einstellung Sitzlüftung Fahrer (0...6)
          signal KL_SIH_Soll_li_XIX_ClimateControl_01_XIX_HCP3_CANFD01: start 64, 3 bit, little-endian, data-type-policy=OVERRIDE, i-signal-type=PRIMITIVE, init-value=0, base-type=BT_KL_SIH_Soll_li, compu {phys=raw for raw 0..6}, range phys 0..6, raw 0..6, transfer-property=TRIGGERED-WITHOUT-REPETITION  # Einstellung Sitzheizung Fahrer (0...6)
          signal KL_SIH_Soll_re_XIX_ClimateControl_01_XIX_HCP3_CANFD01: start 67, 3 bit, little-endian, data-type-policy=OVERRIDE, i-signal-type=PRIMITIVE, init-value=0, base-type=BT_KL_SIH_Soll_re, compu {phys=raw for raw 0..6}, range phys 0..6, raw 0..6, transfer-property=TRIGGERED-WITHOUT-REPETITION  # Einstellung Sitzheizung Beifahrer (0...6)
          signal KL_VK_Anf_XIX_ClimateControl_01_XIX_HCP3_CANFD01: start 72, 3 bit, little-endian, data-type-policy=OVERRIDE, i-signal-type=PRIMITIVE, init-value=6, base-type=BT_KL_VK_Anf, invalid-value=Invalid_KL_VK_Anf_XIX_ClimateControl_01_XIX_HCP3_CANFD01:7, compu {7=Cx7_Fehler (CM_KL_VK_Anf_Cx7_Fehler), 1=Cx1_Startanf_via_FFB (CM_KL_VK_Anf_Cx1_Startanf_via_FFB), 3=Cx3_VK_Strategie_STH (CM_KL_VK_Anf_Cx3_VK_Strategie_STH), 2=Cx2_Startanf_via_Sofortheiztaste (CM_KL_VK_Anf_Cx2_Startanf_via_Sofortheiztaste), 0=Cx0_keine_Startanf_von_Climatronic (CM_KL_VK_Anf_Cx0_keine_Startanf_von_Climatronic), 4=Cx4_Startanf_via_ZV_FFB (CM_KL_VK_Anf_Cx4_Startanf_via_ZV_FFB), 5=Cx5_VK_Abbruch (CM_KL_VK_Anf_Cx5_VK_Abbruch), 6=Cx6_Init (CM_KL_VK_Anf_Cx6_Init)}, range raw 0..7, transfer-property=TRIGGERED-WITHOUT-REPETITION  # Starten einer Standklimatisierung ausgehend von der Climatronic Richtung Lademanagment.
          signal KL_Umluftklappe_Status_XIX_ClimateControl_01_XIX_HCP3_CANFD01: start 75, 4 bit, little-endian, data-type-policy=OVERRIDE, i-signal-type=PRIMITIVE, init-value=14, base-type=BT_KL_Umluftklappe_Status, invalid-value=Invalid_KL_Umluftklappe_Status_XIX_ClimateControl_01_XIX_HCP3_CANFD01:15, compu {15=Cxf_Fehler (CM_KL_Umluftklappe_Status_Cxf_Fehler), 8=Cx8_Teilumluft_80 (CM_KL_Umluftklappe_Status_Cx8_Teilumluft_80), 1=Cx1_Teilumluft_10 (CM_KL_Umluftklappe_Status_Cx1_Teilumluft_10), 0=Cx0_Frischluft (CM_KL_Umluftklappe_Status_Cx0_Frischluft), 9=Cx9_Teilumluft_90 (CM_KL_Umluftklappe_Status_Cx9_Teilumluft_90), 6=Cx6_Teilumluft_60 (CM_KL_Umluftklappe_Status_Cx6_Teilumluft_60), 14=Cxe_Init (CM_KL_Umluftklappe_Status_Cxe_Init), 10=Cxa_Umluft (CM_KL_Umluftklappe_Status_Cxa_Umluft), 4=Cx4_Teilumluft_40 (CM_KL_Umluftklappe_Status_Cx4_Teilumluft_40), 2=Cx2_Teilumluft_20 (CM_KL_Umluftklappe_Status_Cx2_Teilumluft_20), 7=Cx7_Teilumluft_70 (CM_KL_Umluftklappe_Status_Cx7_Teilumluft_70), 5=Cx5_Teilumluft_50 (CM_KL_Umluftklappe_Status_Cx5_Teilumluft_50), 3=Cx3_Teilumluft_30 (CM_KL_Umluftklappe_Status_Cx3_Teilumluft_30)}, range raw 0..15, transfer-property=TRIGGERED-WITHOUT-REPETITION  # Status Umluftklappe
          signal KL_FSH_Anf_XIX_ClimateControl_01_XIX_HCP3_CANFD01: start 79, 1 bit, little-endian, data-type-policy=OVERRIDE, i-signal-type=PRIMITIVE, init-value=0, base-type=BT_KL_FSH_Anf, compu {0=Cx0_nicht_angefordert (CM_KL_FSH_Anf_Cx0_nicht_angefordert), 1=Cx1_angefordert (CM_KL_FSH_Anf_Cx1_angefordert)}, range raw 0..1, transfer-property=TRIGGERED-WITHOUT-REPETITION  # Frontscheibenheizungsbedarf im Rahmen der Standklimatisierung
          signal KL_Luftfeuchte_vVerd_Front_XIX_ClimateControl_01_XIX_HCP3_CANFD01: start 80, 8 bit, little-endian, data-type-policy=OVERRIDE, i-signal-type=PRIMITIVE, init-value=254, base-type=BT_KL_Luftfeuchte_vVerd_Front, invalid-value=Invalid_KL_Luftfeuchte_vVerd_Front_XIX_ClimateControl_01_XIX_HCP3_CANFD01:255, compu {phys=raw*0.5 for raw 0..252, 255=Cxff_Fehler (CM_KL_Luftfeuchte_vVerd_Front_Cxff_Fehler), 254=Cxfe_Init (CM_KL_Luftfeuchte_vVerd_Front_Cxfe_Init), 253=Cxfd_nicht_verfuegbar (CM_KL_Luftfeuchte_vVerd_Front_Cxfd_nicht_verfuegbar); unit Unit_PerCent}, range phys 0..126 Unit_PerCent, raw 0..255, unit=Unit_PerCent, transfer-property=TRIGGERED-WITHOUT-REPETITION  # relative Luftfeuchtigkeit vor Frontverdampfer
          signal KL_ECO_Aktiv_XIX_ClimateControl_01_XIX_HCP3_CANFD01: start 88, 1 bit, little-endian, data-type-policy=OVERRIDE, i-signal-type=PRIMITIVE, init-value=0, base-type=BT_KL_ECO_Aktiv, compu {0=Cx0_inaktiv (CM_KL_ECO_Aktiv_Cx0_inaktiv), 1=Cx1_aktiv (CM_KL_ECO_Aktiv_Cx1_aktiv)}, range raw 0..1, transfer-property=TRIGGERED-WITHOUT-REPETITION  # Funktion Eco durch Kundeneingriff aktiviert
          signal KL_FSH_ansteuern_XIX_ClimateControl_01_XIX_HCP3_CANFD01: start 89, 1 bit, little-endian, data-type-policy=OVERRIDE, i-signal-type=PRIMITIVE, init-value=0, base-type=BT_KL_FSH_ansteuern, compu {1=Cx1_nicht_angefordert (CM_KL_FSH_ansteuern_Cx1_nicht_angefordert), 0=Cx0_angefordert (CM_KL_FSH_ansteuern_Cx0_angefordert)}, range raw 0..1, transfer-property=TRIGGERED-WITHOUT-REPETITION  # Anforderung zum Ansteuern der Frontscheibenheizung
          signal KL_FSH_Soll_P_XIX_ClimateControl_01_XIX_HCP3_CANFD01: start 90, 6 bit, little-endian, data-type-policy=OVERRIDE, i-signal-type=PRIMITIVE, init-value=0, base-type=BT_KL_FSH_Soll_P, invalid-value=Invalid_KL_FSH_Soll_P_XIX_ClimateControl_01_XIX_HCP3_CANFD01:63, compu {phys=raw*20 for raw 1..62, 63=Cx3f_Fehler (CM_KL_FSH_Soll_P_Cx3f_Fehler), 0=Cx0_Aus (CM_KL_FSH_Soll_P_Cx0_Aus); unit Unit_Watt}, range phys 20..1240 Unit_Watt, raw 0..63, unit=Unit_Watt, transfer-property=TRIGGERED-WITHOUT-REPETITION  # Sollwertvorgabe für Frontscheibenheizung
          signal KL_I_Geblaese_XIX_ClimateControl_01_XIX_HCP3_CANFD01: start 96, 8 bit, little-endian, data-type-policy=OVERRIDE, i-signal-type=PRIMITIVE, init-value=0, base-type=BT_KL_I_Geblaese, invalid-value=Invalid_KL_I_Geblaese_XIX_ClimateControl_01_XIX_HCP3_CANFD01:255, compu {phys=raw*0.25 for raw 0..254, 255=Cxff_Fehler (CM_KL_I_Geblaese_Cxff_Fehler); unit Unit_Amper}, range phys 0..63.5 Unit_Amper, raw 0..255, unit=Unit_Amper, transfer-property=TRIGGERED-WITHOUT-REPETITION  # Stromaufnahme Gebläse
          signal KL_Beschlagsgefahr_XIX_ClimateControl_01_XIX_HCP3_CANFD01: start 105, 1 bit, little-endian, data-type-policy=OVERRIDE, i-signal-type=PRIMITIVE, init-value=0, base-type=BT_KL_Beschlagsgefahr, compu {0=Cx0_keine_Beschlagsgefahr (CM_KL_Beschlagsgefahr_Cx0_keine_Beschlagsgefahr), 1=Cx1_Beschlagsgefahr (CM_KL_Beschlagsgefahr_Cx1_Beschlagsgefahr)}, range raw 0..1, transfer-property=TRIGGERED-WITHOUT-REPETITION  # Beschlagsgefahr auf der Frontscheibe im Bereich des Spiegelfusses. Dient zur präventiven Ansteuerung der Kamera-Scheibenheizung, um Kamera-Blindheit zu vermeiden PHEV: volle Leistungsfreigabe HV Heizer und HV EKK bei Scheibenbeschlag
          signal KL_ZR_Anforderung_XIX_ClimateControl_01_XIX_HCP3_CANFD01: start 106, 2 bit, little-endian, data-type-policy=OVERRIDE, i-signal-type=PRIMITIVE, init-value=0, base-type=BT_KL_ZR_Anforderung, compu {1=Cx1_inaktiv (CM_KL_ZR_Anforderung_Cx1_inaktiv), 2=Cx2_aktiv (CM_KL_ZR_Anforderung_Cx2_aktiv), 3=Cx3_reserviert (CM_KL_ZR_Anforderung_Cx3_reserviert), 0=Cx0_init (CM_KL_ZR_Anforderung_Cx0_init)}, range raw 0..3, transfer-property=TRIGGERED-WITHOUT-REPETITION  # Anforderung an MIB die Displays zu aktivieren
          signal KL_Kundeneingriff_Geblaese_Z1_XIX_ClimateControl_01_XIX_HCP3_CANFD01: start 108, 1 bit, little-endian, data-type-policy=OVERRIDE, i-signal-type=PRIMITIVE, init-value=0, base-type=BT_KL_Kundeneingriff_Geblaese_Z1, compu {0=Cx0_Kein_Kundeneingriff_Geblaese (CM_KL_Kundeneingriff_Geblaese_Z1_Cx0_Kein_Kundeneingriff_Geblaese), 1=Cx1_Kundeneingriff_Geblaese_aktiv (CM_KL_Kundeneingriff_Geblaese_Z1_Cx1_Kundeneingriff_Geblaese_aktiv)}, range raw 0..1, transfer-property=TRIGGERED-WITHOUT-REPETITION  # Manueller Kundeneingriff in die Geblaeseregelung
          signal KL_Kundeneingriff_Geblaese_Z2_XIX_ClimateControl_01_XIX_HCP3_CANFD01: start 109, 1 bit, little-endian, data-type-policy=OVERRIDE, i-signal-type=PRIMITIVE, init-value=0, base-type=BT_KL_Kundeneingriff_Geblaese_Z2, compu {1=Cx1_Kundeneingriff_Geblaese_aktiv (CM_KL_Kundeneingriff_Geblaese_Z2_Cx1_Kundeneingriff_Geblaese_aktiv), 0=Cx0_Kein_Kundeneingriff_Geblaese (CM_KL_Kundeneingriff_Geblaese_Z2_Cx0_Kein_Kundeneingriff_Geblaese)}, range raw 0..1, transfer-property=TRIGGERED-WITHOUT-REPETITION  # Manueller Kundeneingriff in die Geblaeseregelung
          signal KL_ECO_PRO_Aktiv_XIX_ClimateControl_01_XIX_HCP3_CANFD01: start 110, 1 bit, little-endian, data-type-policy=OVERRIDE, i-signal-type=PRIMITIVE, init-value=0, base-type=BT_KL_ECO_PRO_Aktiv, compu {0=Cx0_inaktiv (CM_KL_ECO_PRO_Aktiv_Cx0_inaktiv), 1=Cx1_aktiv (CM_KL_ECO_PRO_Aktiv_Cx1_aktiv)}, range raw 0..1, transfer-property=TRIGGERED-WITHOUT-REPETITION  # Funktion ECO-PRO durch Kundeneingriff aktiviert
          signal KL_HSH_Soll_XIX_ClimateControl_01_XIX_HCP3_CANFD01: start 111, 1 bit, little-endian, data-type-policy=OVERRIDE, i-signal-type=PRIMITIVE, init-value=0, base-type=BT_KL_HSH_Soll, compu {0=Cx0_nicht_angefordert (CM_KL_HSH_Soll_Cx0_nicht_angefordert), 1=Cx1_angefordert (CM_KL_HSH_Soll_Cx1_angefordert)}, range raw 0..1, transfer-property=TRIGGERED-WITHOUT-REPETITION  # Sollstatus Heckscheibenheizung
          signal KL_Sonnenintensitaet_XIX_ClimateControl_01_XIX_HCP3_CANFD01: start 112, 8 bit, little-endian, data-type-policy=OVERRIDE, i-signal-type=PRIMITIVE, init-value=254, base-type=BT_KL_Sonnenintensitaet, invalid-value=Invalid_KL_Sonnenintensitaet_XIX_ClimateControl_01_XIX_HCP3_CANFD01:255, compu {phys=raw*10 for raw 0..100, 255=Cxff_Fehler (CM_KL_Sonnenintensitaet_Cxff_Fehler), 254=Cxfe_Init (CM_KL_Sonnenintensitaet_Cxfe_Init); unit Unit_WattPerMeterSquar}, range phys 0..1000 Unit_WattPerMeterSquar, raw 0..255, unit=Unit_WattPerMeterSquar, transfer-property=TRIGGERED-WITHOUT-REPETITION  # gemittelte eingestrahlte Leistung in W/m2
          signal KL_Eps_Innen_XIX_ClimateControl_01_XIX_HCP3_CANFD01: start 120, 8 bit, little-endian, data-type-policy=OVERRIDE, i-signal-type=PRIMITIVE, init-value=254, base-type=BT_KL_Eps_Innen, invalid-value=Invalid_KL_Eps_Innen_XIX_ClimateControl_01_XIX_HCP3_CANFD01:255, compu {phys=raw*0.5-50 for raw 0..200, 255=Cxff_Fehler (CM_KL_Eps_Innen_Cxff_Fehler), 254=Cxfe_Init (CM_KL_Eps_Innen_Cxfe_Init); unit Unit_DegreCelsi}, range phys -50..50 Unit_DegreCelsi, raw 0..255, unit=Unit_DegreCelsi, transfer-property=TRIGGERED-WITHOUT-REPETITION  # mittlerer Wert der Klima Regelabweichung
          signal KL_Heizbedarf_XIX_ClimateControl_01_XIX_HCP3_CANFD01: start 128, 10 bit, little-endian, data-type-policy=OVERRIDE, i-signal-type=PRIMITIVE, init-value=1022, base-type=BT_KL_Heizbedarf, invalid-value=Invalid_KL_Heizbedarf_XIX_ClimateControl_01_XIX_HCP3_CANFD01:1023, compu {phys=raw*0.1 for raw 1..900, 1023=Cx3ff_Fehler (CM_KL_Heizbedarf_Cx3ff_Fehler), 1022=Cx3fe_Init (CM_KL_Heizbedarf_Cx3fe_Init), 0=Cx0_Kein_Heizbedarf (CM_KL_Heizbedarf_Cx0_Kein_Heizbedarf); unit Unit_DegreCelsi}, range phys 0.1..90 Unit_DegreCelsi, raw 0..1023, unit=Unit_DegreCelsi, transfer-property=TRIGGERED-WITHOUT-REPETITION  # Bedarf an Heizmenge für Innenraumklimatisierung
          signal KL_Kundeneingriff_Geblaese_XIX_ClimateControl_01_XIX_HCP3_CANFD01: start 138, 1 bit, little-endian, data-type-policy=OVERRIDE, i-signal-type=PRIMITIVE, init-value=0, base-type=BT_KL_Kundeneingriff_Geblaese, compu {1=Cx1_Kundeneingriff_Geblaese_aktiv (CM_KL_Kundeneingriff_Geblaese_Cx1_Kundeneingriff_Geblaese_aktiv), 0=Cx0_Kein_Kundeneingriff_Geblaese (CM_KL_Kundeneingriff_Geblaese_Cx0_Kein_Kundeneingriff_Geblaese)}, range raw 0..1, transfer-property=TRIGGERED-WITHOUT-REPETITION  # Manueller Kundeneingriff in die Geblaeseregelung
          signal KL_QBit_Sonnenintensitaet_XIX_ClimateControl_01_XIX_HCP3_CANFD01: start 139, 1 bit, little-endian, data-type-policy=OVERRIDE, i-signal-type=PRIMITIVE, init-value=1, base-type=BT_KL_QBit_Sonnenintensitaet, compu {1=Cx1_Ersatz_Init_oder_Fehlerwert (CM_KL_QBit_Sonnenintensitaet_Cx1_Ersatz_Init_oder_Fehlerwert), 0=Cx0_gueltiger_Wert (CM_KL_QBit_Sonnenintensitaet_Cx0_gueltiger_Wert)}, range raw 0..1, transfer-property=TRIGGERED-WITHOUT-REPETITION  # Gültigkeitsbit für Signal KL_Sonenintensität Gesetzt bei Ersatzwert, Init oder Fehler.
          signal KL_Status_Klimastil_XIX_ClimateControl_01_XIX_HCP3_CANFD01: start 140, 2 bit, little-endian, data-type-policy=OVERRIDE, i-signal-type=PRIMITIVE, init-value=0, base-type=BT_KL_Status_Klimastil, compu {0=Cx0_Modus_1 (CM_KL_Status_Klimastil_Cx0_Modus_1), 2=Cx2_Modus_3 (CM_KL_Status_Klimastil_Cx2_Modus_3), 3=Cx3_Modus_4 (CM_KL_Status_Klimastil_Cx3_Modus_4), 1=Cx1_Modus_2 (CM_KL_Status_Klimastil_Cx1_Modus_2)}, range raw 0..3, transfer-property=TRIGGERED-WITHOUT-REPETITION  # Signal für aktuelles Programm des KBT
          signal KL_Thermischer_Bedarf_XIX_ClimateControl_01_XIX_HCP3_CANFD01: start 142, 3 bit, little-endian, data-type-policy=OVERRIDE, i-signal-type=PRIMITIVE, init-value=6, base-type=BT_KL_Thermischer_Bedarf, invalid-value=Invalid_KL_Thermischer_Bedarf_XIX_ClimateControl_01_XIX_HCP3_CANFD01:7, compu {7=Cx7_Fehler (CM_KL_Thermischer_Bedarf_Cx7_Fehler), 2=Cx2_Nachlauf_Heizen (CM_KL_Thermischer_Bedarf_Cx2_Nachlauf_Heizen), 6=Cx6_Init (CM_KL_Thermischer_Bedarf_Cx6_Init), 3=Cx3_Lueften (CM_KL_Thermischer_Bedarf_Cx3_Lueften), 4=Cx4_Kuehlen (CM_KL_Thermischer_Bedarf_Cx4_Kuehlen), 1=Cx1_Heizen (CM_KL_Thermischer_Bedarf_Cx1_Heizen), 0=Cx0_Aus (CM_KL_Thermischer_Bedarf_Cx0_Aus)}, range raw 0..7, transfer-property=TRIGGERED-WITHOUT-REPETITION  # Temperierungsbedarf zur Innenraumklimatisierung
          signal KL_Temp_vor_Verdampfer_XIX_ClimateControl_01_XIX_HCP3_CANFD01: start 145, 7 bit, little-endian, data-type-policy=OVERRIDE, i-signal-type=PRIMITIVE, init-value=126, base-type=BT_KL_Temp_vor_Verdampfer, invalid-value=Invalid_KL_Temp_vor_Verdampfer_XIX_ClimateControl_01_XIX_HCP3_CANFD01:127, compu {phys=raw-20 for raw 0..90, 127=Cx7f_Fehler (CM_KL_Temp_vor_Verdampfer_Cx7f_Fehler), 126=Cx7e_Init (CM_KL_Temp_vor_Verdampfer_Cx7e_Init); unit Unit_DegreCelsi}, range phys -20..70 Unit_DegreCelsi, raw 0..127, unit=Unit_DegreCelsi, transfer-property=TRIGGERED-WITHOUT-REPETITION  # Ist Lufttemperatur vor Verdampfer
          signal KL_NV_Energie_Anf_XIX_ClimateControl_01_XIX_HCP3_CANFD01: start 152, 8 bit, little-endian, data-type-policy=OVERRIDE, i-signal-type=PRIMITIVE, init-value=254, base-type=BT_KL_NV_Energie_Anf, invalid-value=Invalid_KL_NV_Energie_Anf_XIX_ClimateControl_01_XIX_HCP3_CANFD01:255, compu {phys=raw*10 for raw 0..253, 255=Cxff_Fehler (CM_KL_NV_Energie_Anf_Cxff_Fehler), 254=Cxfe_Init (CM_KL_NV_Energie_Anf_Cxfe_Init); unit Unit_WattHour}, range phys 0..2530 Unit_WattHour, raw 0..255, unit=Unit_WattHour, transfer-property=TRIGGERED-WITHOUT-REPETITION  # Benötigte Energie (12V) für die Erweiterte Vorkonditionierung
          signal KL_Kuehllstg_Delta_Eingriff_XIX_ClimateControl_01_XIX_HCP3_CANFD01: start 160, 8 bit, little-endian, data-type-policy=OVERRIDE, i-signal-type=PRIMITIVE, init-value=254, base-type=BT_KL_Kuehllstg_Delta_Eingriff, invalid-value=Invalid_KL_Kuehllstg_Delta_Eingriff_XIX_ClimateControl_01_XIX_HCP3_CANFD01:255, compu {phys=raw*50-6300 for raw 0..253, 255=Cxff_Fehler (CM_KL_Kuehllstg_Delta_Eingriff_Cxff_Fehler), 254=Cxfe_Init (CM_KL_Kuehllstg_Delta_Eingriff_Cxfe_Init); unit Unit_Watt}, range phys -6300..6350 Unit_Watt, raw 0..255, unit=Unit_Watt, transfer-property=TRIGGERED-WITHOUT-REPETITION  # Durch Kundeneingriff erwartete Veränderung der Kühlleistung bei aktuellen klimatischen Bedingungen
          signal KL_Heizlstg_Delta_Eingriff_XIX_ClimateControl_01_XIX_HCP3_CANFD01: start 168, 8 bit, little-endian, data-type-policy=OVERRIDE, i-signal-type=PRIMITIVE, init-value=254, base-type=BT_KL_Heizlstg_Delta_Eingriff, invalid-value=Invalid_KL_Heizlstg_Delta_Eingriff_XIX_ClimateControl_01_XIX_HCP3_CANFD01:255, compu {phys=raw*50-6300 for raw 0..253, 255=Cxff_Fehler (CM_KL_Heizlstg_Delta_Eingriff_Cxff_Fehler), 254=Cxfe_Init (CM_KL_Heizlstg_Delta_Eingriff_Cxfe_Init); unit Unit_Watt}, range phys -6300..6350 Unit_Watt, raw 0..255, unit=Unit_Watt, transfer-property=TRIGGERED-WITHOUT-REPETITION  # Durch Kundeneingriff erwartete Veränderung der Heizleistung bei aktuellen klimatischen Bedingungen
          signal KL_Tempklappe_Fond_XIX_ClimateControl_01_XIX_HCP3_CANFD01: start 176, 8 bit, little-endian, data-type-policy=OVERRIDE, i-signal-type=PRIMITIVE, init-value=254, base-type=BT_KL_Tempklappe_Fond, invalid-value=Invalid_KL_Tempklappe_Fond_XIX_ClimateControl_01_XIX_HCP3_CANFD01:255, compu {phys=raw*0.5 for raw 0..200, 255=Cxff_Fehler (CM_KL_Tempklappe_Fond_Cxff_Fehler), 254=Cxfe_Init (CM_KL_Tempklappe_Fond_Cxfe_Init); unit Unit_PerCent}, range phys 0..100 Unit_PerCent, raw 0..255, unit=Unit_PerCent, transfer-property=TRIGGERED-WITHOUT-REPETITION  # Sollwert der Temperaturklappe Fond
          signal KL_Tempklappe_li_XIX_ClimateControl_01_XIX_HCP3_CANFD01: start 184, 8 bit, little-endian, data-type-policy=OVERRIDE, i-signal-type=PRIMITIVE, init-value=254, base-type=BT_KL_Tempklappe_li, invalid-value=Invalid_KL_Tempklappe_li_XIX_ClimateControl_01_XIX_HCP3_CANFD01:255, compu {phys=raw*0.5 for raw 0..200, 255=Cxff_Fehler (CM_KL_Tempklappe_li_Cxff_Fehler), 254=Cxfe_Init (CM_KL_Tempklappe_li_Cxfe_Init); unit Unit_PerCent}, range phys 0..100 Unit_PerCent, raw 0..255, unit=Unit_PerCent, transfer-property=TRIGGERED-WITHOUT-REPETITION  # Sollwert der Temperaturklappe links (2 zonig) Sollwert der Temperaturklappe (1-zonig)
          signal KL_Tempklappe_re_XIX_ClimateControl_01_XIX_HCP3_CANFD01: start 192, 8 bit, little-endian, data-type-policy=OVERRIDE, i-signal-type=PRIMITIVE, init-value=254, base-type=BT_KL_Tempklappe_re, invalid-value=Invalid_KL_Tempklappe_re_XIX_ClimateControl_01_XIX_HCP3_CANFD01:255, compu {phys=raw*0.5 for raw 0..200, 255=Cxff_Fehler (CM_KL_Tempklappe_re_Cxff_Fehler), 254=Cxfe_Init (CM_KL_Tempklappe_re_Cxfe_Init); unit Unit_PerCent}, range phys 0..100 Unit_PerCent, raw 0..255, unit=Unit_PerCent, transfer-property=TRIGGERED-WITHOUT-REPETITION  # Sollwert der Temperaturklappe rechts
          signal KL_Kuehlbedarf_XIX_ClimateControl_01_XIX_HCP3_CANFD01: start 200, 8 bit, little-endian, data-type-policy=OVERRIDE, i-signal-type=PRIMITIVE, init-value=254, base-type=BT_KL_Kuehlbedarf, invalid-value=Invalid_KL_Kuehlbedarf_XIX_ClimateControl_01_XIX_HCP3_CANFD01:255, compu {phys=raw*0.1 for raw 0..250, 255=Cxff_Fehler (CM_KL_Kuehlbedarf_Cxff_Fehler), 254=Cxfe_Init (CM_KL_Kuehlbedarf_Cxfe_Init), 253=Cxfd_Kein_Kuehlbedarf (CM_KL_Kuehlbedarf_Cxfd_Kein_Kuehlbedarf); unit Unit_DegreCelsi}, range phys 0..25 Unit_DegreCelsi, raw 0..255, unit=Unit_DegreCelsi, transfer-property=TRIGGERED-WITHOUT-REPETITION  # Bedarf an Kühlmenge für Innenraumklimatisierung
          signal KL_AC_Schalter_XIX_ClimateControl_01_XIX_HCP3_CANFD01: start 208, 1 bit, little-endian, data-type-policy=OVERRIDE, i-signal-type=PRIMITIVE, init-value=0, base-type=BT_KL_AC_Schalter, compu {1=Cx1_ein (CM_KL_AC_Schalter_Cx1_ein), 0=Cx0_aus (CM_KL_AC_Schalter_Cx0_aus)}, range raw 0..1, transfer-property=TRIGGERED-WITHOUT-REPETITION  # AC Schalter
          signal KL_Leistungspriorisierung_XIX_ClimateControl_01_XIX_HCP3_CANFD01: start 209, 2 bit, little-endian, data-type-policy=OVERRIDE, i-signal-type=PRIMITIVE, init-value=0, base-type=BT_KL_Leistungspriorisierung, compu {0=Cx0_keine_Priorisierung (CM_KL_Leistungspriorisierung_Cx0_keine_Priorisierung), 1=Cx1_PullDown (CM_KL_Leistungspriorisierung_Cx1_PullDown), 2=Cx2_Beschlagsgefahr (CM_KL_Leistungspriorisierung_Cx2_Beschlagsgefahr), 3=Cx3_Defrost_aktiv (CM_KL_Leistungspriorisierung_Cx3_Defrost_aktiv)}, range raw 0..3, transfer-property=TRIGGERED-WITHOUT-REPETITION  # Priorisierungsvorgaben
          signal KL_Zustand_XIX_ClimateControl_01_XIX_HCP3_CANFD01: start 211, 1 bit, little-endian, data-type-policy=OVERRIDE, i-signal-type=PRIMITIVE, init-value=0, base-type=BT_KL_Zustand, compu {0=Cx0_Aus (CM_KL_Zustand_Cx0_Aus), 1=Cx1_Ein (CM_KL_Zustand_Cx1_Ein)}, range raw 0..1, transfer-property=TRIGGERED-WITHOUT-REPETITION  # Beschreibt den Zustand des Klima-/Heizungsbedienteils. (OFF-Mode Bedienteil) PAG (MLB): Beschreibt den Zustand des Kompressors
          signal KL_Heizbedarf_Z1_XIX_ClimateControl_01_XIX_HCP3_CANFD01: start 212, 10 bit, little-endian, data-type-policy=OVERRIDE, i-signal-type=PRIMITIVE, init-value=1022, base-type=BT_KL_Heizbedarf_Z1, invalid-value=Invalid_KL_Heizbedarf_Z1_XIX_ClimateControl_01_XIX_HCP3_CANFD01:1023, compu {phys=raw*0.1 for raw 1..900, 1023=Cx3ff_Fehler (CM_KL_Heizbedarf_Z1_Cx3ff_Fehler), 0=Cx0_kein_Heizbedarf (CM_KL_Heizbedarf_Z1_Cx0_kein_Heizbedarf), 1022=Cx3fe_Init (CM_KL_Heizbedarf_Z1_Cx3fe_Init); unit Unit_DegreCelsi}, range phys 0.1..90 Unit_DegreCelsi, raw 0..1023, unit=Unit_DegreCelsi, transfer-property=TRIGGERED-WITHOUT-REPETITION  # Bedarf an Heizmenge für Innenraumklimatisierung Zone 1
          signal KL_Heizbedarf_Z2_XIX_ClimateControl_01_XIX_HCP3_CANFD01: start 222, 10 bit, little-endian, data-type-policy=OVERRIDE, i-signal-type=PRIMITIVE, init-value=1022, base-type=BT_KL_Heizbedarf_Z2, invalid-value=Invalid_KL_Heizbedarf_Z2_XIX_ClimateControl_01_XIX_HCP3_CANFD01:1023, compu {phys=raw*0.1 for raw 1..900, 1023=Cx3ff_Fehler (CM_KL_Heizbedarf_Z2_Cx3ff_Fehler), 0=Cx0_kein_Heizbedarf (CM_KL_Heizbedarf_Z2_Cx0_kein_Heizbedarf), 1022=Cx3fe_Init (CM_KL_Heizbedarf_Z2_Cx3fe_Init); unit Unit_DegreCelsi}, range phys 0.1..90 Unit_DegreCelsi, raw 0..1023, unit=Unit_DegreCelsi, transfer-property=TRIGGERED-WITHOUT-REPETITION  # Bedarf an Heizmenge für Innenraumklimatisierung Zone 2
          signal KL_Heizbedarf_Z3_XIX_ClimateControl_01_XIX_HCP3_CANFD01: start 232, 10 bit, little-endian, data-type-policy=OVERRIDE, i-signal-type=PRIMITIVE, init-value=1022, base-type=BT_KL_Heizbedarf_Z3, invalid-value=Invalid_KL_Heizbedarf_Z3_XIX_ClimateControl_01_XIX_HCP3_CANFD01:1023, compu {phys=raw*0.1 for raw 1..900, 1023=Cx3ff_Fehler (CM_KL_Heizbedarf_Z3_Cx3ff_Fehler), 0=Cx0_kein_Heizbedarf (CM_KL_Heizbedarf_Z3_Cx0_kein_Heizbedarf), 1022=Cx3fe_Init (CM_KL_Heizbedarf_Z3_Cx3fe_Init); unit Unit_DegreCelsi}, range phys 0.1..90 Unit_DegreCelsi, raw 0..1023, unit=Unit_DegreCelsi, transfer-property=TRIGGERED-WITHOUT-REPETITION  # Bedarf an Heizmenge für Innenraumklimatisierung Zone 3
          signal KL_Heizbedarf_Z4_XIX_ClimateControl_01_XIX_HCP3_CANFD01: start 242, 10 bit, little-endian, data-type-policy=OVERRIDE, i-signal-type=PRIMITIVE, init-value=1022, base-type=BT_KL_Heizbedarf_Z4, invalid-value=Invalid_KL_Heizbedarf_Z4_XIX_ClimateControl_01_XIX_HCP3_CANFD01:1023, compu {phys=raw*0.1 for raw 1..900, 1023=Cx3ff_Fehler (CM_KL_Heizbedarf_Z4_Cx3ff_Fehler), 1022=Cx3fe_Init (CM_KL_Heizbedarf_Z4_Cx3fe_Init), 0=Cx0_kein_Heizbedarf (CM_KL_Heizbedarf_Z4_Cx0_kein_Heizbedarf); unit Unit_DegreCelsi}, range phys 0.1..90 Unit_DegreCelsi, raw 0..1023, unit=Unit_DegreCelsi, transfer-property=TRIGGERED-WITHOUT-REPETITION  # Bedarf an Heizmenge für Innenraumklimatisierung Zone 4
          signal KL_AC_Aktiv_XIX_ClimateControl_01_XIX_HCP3_CANFD01: start 252, 1 bit, little-endian, data-type-policy=OVERRIDE, i-signal-type=PRIMITIVE, init-value=0, base-type=BT_KL_AC_Aktiv, compu {1=Cx1_aktiv (CM_KL_AC_Aktiv_Cx1_aktiv), 0=Cx0_inaktiv (CM_KL_AC_Aktiv_Cx0_inaktiv)}, range raw 0..1, transfer-property=TRIGGERED-WITHOUT-REPETITION  # Kundenwunsch AC
          signal KL_Luftmasse_Gesamt_Z1_XIX_ClimateControl_01_XIX_HCP3_CANFD01: start 253, 16 bit, little-endian, data-type-policy=OVERRIDE, i-signal-type=PRIMITIVE, init-value=65534, base-type=BT_KL_Luftmasse_Gesamt_Z1, invalid-value=Invalid_KL_Luftmasse_Gesamt_Z1_XIX_ClimateControl_01_XIX_HCP3_CANFD01:65535, compu {phys=raw*0.125 for raw 0..6400, 65535=Cxffff_Fehler (CM_KL_Luftmasse_Gesamt_Z1_Cxffff_Fehler), 65534=Cxfffe_Init (CM_KL_Luftmasse_Gesamt_Z1_Cxfffe_Init)}, range phys 0..800, raw 0..65535, transfer-property=TRIGGERED-WITHOUT-REPETITION  # Ist Luftmassenstrom Gesamt Klimatisierung Zone 1 (kg/h)
          signal KL_Luftmasse_Gesamt_Z2_XIX_ClimateControl_01_XIX_HCP3_CANFD01: start 269, 16 bit, little-endian, data-type-policy=OVERRIDE, i-signal-type=PRIMITIVE, init-value=65534, base-type=BT_KL_Luftmasse_Gesamt_Z2, invalid-value=Invalid_KL_Luftmasse_Gesamt_Z2_XIX_ClimateControl_01_XIX_HCP3_CANFD01:65535, compu {phys=raw*0.125 for raw 0..6400, 65535=Cxffff_Fehler (CM_KL_Luftmasse_Gesamt_Z2_Cxffff_Fehler), 65534=Cxfffe_Init (CM_KL_Luftmasse_Gesamt_Z2_Cxfffe_Init)}, range phys 0..800, raw 0..65535, transfer-property=TRIGGERED-WITHOUT-REPETITION  # Ist Luftmassenstrom Gesamt Klimatisierung Zone 2 (kg/h)
          signal KL_Luftmasse_Gesamt_Z3_XIX_ClimateControl_01_XIX_HCP3_CANFD01: start 285, 16 bit, little-endian, data-type-policy=OVERRIDE, i-signal-type=PRIMITIVE, init-value=65534, base-type=BT_KL_Luftmasse_Gesamt_Z3, invalid-value=Invalid_KL_Luftmasse_Gesamt_Z3_XIX_ClimateControl_01_XIX_HCP3_CANFD01:65535, compu {phys=raw*0.125 for raw 0..6400, 65535=Cxffff_Fehler (CM_KL_Luftmasse_Gesamt_Z3_Cxffff_Fehler), 65534=Cxfffe_Init (CM_KL_Luftmasse_Gesamt_Z3_Cxfffe_Init)}, range phys 0..800, raw 0..65535, transfer-property=TRIGGERED-WITHOUT-REPETITION  # Ist Luftmassenstrom Gesamt Klimatisierung Zone 3 (kg/h)
          signal KL_Luftmasse_Gesamt_Z4_XIX_ClimateControl_01_XIX_HCP3_CANFD01: start 301, 16 bit, little-endian, data-type-policy=OVERRIDE, i-signal-type=PRIMITIVE, init-value=65534, base-type=BT_KL_Luftmasse_Gesamt_Z4, invalid-value=Invalid_KL_Luftmasse_Gesamt_Z4_XIX_ClimateControl_01_XIX_HCP3_CANFD01:65535, compu {phys=raw*0.125 for raw 0..6400, 65535=Cxffff_Fehler (CM_KL_Luftmasse_Gesamt_Z4_Cxffff_Fehler), 65534=Cxfffe_Init (CM_KL_Luftmasse_Gesamt_Z4_Cxfffe_Init)}, range phys 0..800, raw 0..65535, transfer-property=TRIGGERED-WITHOUT-REPETITION  # Ist Luftmassenstrom Gesamt Klimatisierung Zone 4 (kg/h)
          signal KL_FSA_Taupunkt_XIX_ClimateControl_01_XIX_HCP3_CANFD01: start 317, 10 bit, little-endian, data-type-policy=OVERRIDE, i-signal-type=PRIMITIVE, init-value=1022, base-type=BT_KL_FSA_Taupunkt, invalid-value=Invalid_KL_FSA_Taupunkt_XIX_ClimateControl_01_XIX_HCP3_CANFD01:1023, compu {phys=raw*0.1-40 for raw 0..1000, 1023=Cx3ff_Fehler (CM_KL_FSA_Taupunkt_Cx3ff_Fehler), 1022=Cx3fe_Init (CM_KL_FSA_Taupunkt_Cx3fe_Init), 1021=Cx3fd_nicht_verbaut (CM_KL_FSA_Taupunkt_Cx3fd_nicht_verbaut); unit Unit_DegreCelsi}, range phys -40..60 Unit_DegreCelsi, raw 0..1023, unit=Unit_DegreCelsi, transfer-property=TRIGGERED-WITHOUT-REPETITION  # FSA_Taupunkt (geroutet)
          signal KL_FSA_Luftfeuchte_rel_XIX_ClimateControl_01_XIX_HCP3_CANFD01: start 327, 8 bit, little-endian, data-type-policy=OVERRIDE, i-signal-type=PRIMITIVE, init-value=254, base-type=BT_KL_FSA_Luftfeuchte_rel, invalid-value=Invalid_KL_FSA_Luftfeuchte_rel_XIX_ClimateControl_01_XIX_HCP3_CANFD01:255, compu {phys=raw*0.5 for raw 0..252, 255=Cxff_Fehler (CM_KL_FSA_Luftfeuchte_rel_Cxff_Fehler), 254=Cxfe_Init (CM_KL_FSA_Luftfeuchte_rel_Cxfe_Init), 253=Cxfd_nicht_verbaut (CM_KL_FSA_Luftfeuchte_rel_Cxfd_nicht_verbaut); unit Unit_PerCent}, range phys 0..126 Unit_PerCent, raw 0..255, unit=Unit_PerCent, transfer-property=TRIGGERED-WITHOUT-REPETITION  # FSA_Luftfeuchte (geroutet)
          signal KL_Kundeneingriff_Geblaese_Z3_XIX_ClimateControl_01_XIX_HCP3_CANFD01: start 335, 1 bit, little-endian, data-type-policy=OVERRIDE, i-signal-type=PRIMITIVE, init-value=0, base-type=BT_KL_Kundeneingriff_Geblaese_Z3, compu {0=Cx0_Kein_Kundeneingriff_Geblaese (CM_KL_Kundeneingriff_Geblaese_Z3_Cx0_Kein_Kundeneingriff_Geblaese), 1=Cx1_Kundeneingriff_Geblaese_aktiv (CM_KL_Kundeneingriff_Geblaese_Z3_Cx1_Kundeneingriff_Geblaese_aktiv)}, range raw 0..1, transfer-property=TRIGGERED-WITHOUT-REPETITION  # Manueller Kundeneingriff in die Geblaeseregelung
          signal KL_Kundeneingriff_Geblaese_Z4_XIX_ClimateControl_01_XIX_HCP3_CANFD01: start 336, 1 bit, little-endian, data-type-policy=OVERRIDE, i-signal-type=PRIMITIVE, init-value=0, base-type=BT_KL_Kundeneingriff_Geblaese_Z4, compu {1=Cx1_Kundeneingriff_Geblaese_aktiv (CM_KL_Kundeneingriff_Geblaese_Z4_Cx1_Kundeneingriff_Geblaese_aktiv), 0=Cx0_Kein_Kundeneingriff_Geblaese (CM_KL_Kundeneingriff_Geblaese_Z4_Cx0_Kein_Kundeneingriff_Geblaese)}, range raw 0..1, transfer-property=TRIGGERED-WITHOUT-REPETITION  # Manueller Kundeneingriff in die Geblaeseregelung
      frame DIA_LSR_1_Req_FD_XIX_HCP3_CANFD01: id 0x1C401693, from HCP3_IONode, frame-length=64, can-addressing-mode=EXTENDED, can-frame-rx-behavior=CAN-FD, can-frame-tx-behavior=CAN-FD
        n pdu DIA_LSR_1_Req_FD_XIX_HCP3_CANFD01: length=64
      frame DIA_LSR_1_Resp_FD_XIX_HCP3_CANFD01: id 0x1C421693, to HCP3_IONode, frame-length=64, can-addressing-mode=EXTENDED, can-frame-rx-behavior=CAN-FD, can-frame-tx-behavior=CAN-FD
        n pdu DIA_LSR_1_Resp_FD_XIX_HCP3_CANFD01: length=64
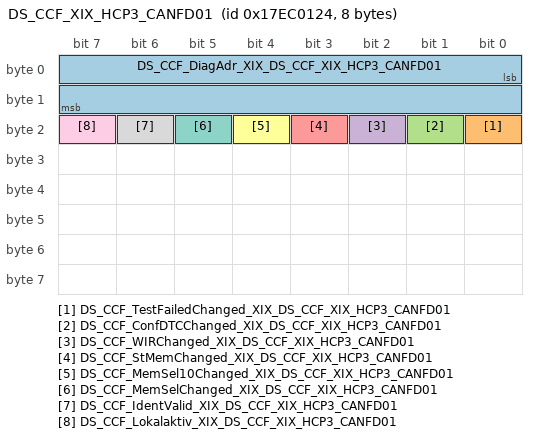
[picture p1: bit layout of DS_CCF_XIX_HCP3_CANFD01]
      frame DS_CCF_XIX_HCP3_CANFD01: id 0x17EC0124, to HCP3_IONode, frame-length=8, can-addressing-mode=EXTENDED, can-frame-rx-behavior=CAN-FD, can-frame-tx-behavior=CAN-FD
        pdu DS_CCF_XIX_HCP3_CANFD01: length=8, minimum-delay=0.08, transmission-mode-true-timing={cyclic-timing={time-offset=0.0, time-period=1.0}, event-controlled-timing={number-of-repetitions=0, repetition-period=0.0}}, unused-bit-pattern=0
          signal DS_CCF_DiagAdr_XIX_DS_CCF_XIX_HCP3_CANFD01: start 0, 16 bit, little-endian, data-type-policy=OVERRIDE, i-signal-type=PRIMITIVE, init-value=33093, base-type=BT_DS_CCF_DiagAdr, compu {phys=raw for raw 0..65535}, range phys 0..65535, raw 0..65535, transfer-property=PENDING  # Übertragung vom Diagnosestatus gem. 80114
          signal DS_CCF_TestFailedChanged_XIX_DS_CCF_XIX_HCP3_CANFD01: start 16, 1 bit, little-endian, data-type-policy=OVERRIDE, i-signal-type=PRIMITIVE, init-value=0, base-type=BT_DS_CCF_TestFailedChanged, compu {phys=raw for raw 0..1}, range phys 0..1, raw 0..1, transfer-property=TRIGGERED-ON-CHANGE-WITHOUT-REPETITION  # Übertragung vom Diagnosestatus gem. 80114
          signal DS_CCF_ConfDTCChanged_XIX_DS_CCF_XIX_HCP3_CANFD01: start 17, 1 bit, little-endian, data-type-policy=OVERRIDE, i-signal-type=PRIMITIVE, init-value=0, base-type=BT_DS_CCF_ConfDTCChanged, compu {phys=raw for raw 0..1}, range phys 0..1, raw 0..1, transfer-property=TRIGGERED-ON-CHANGE-WITHOUT-REPETITION  # Übertragung vom Diagnosestatus gem. 80114
          signal DS_CCF_WIRChanged_XIX_DS_CCF_XIX_HCP3_CANFD01: start 18, 1 bit, little-endian, data-type-policy=OVERRIDE, i-signal-type=PRIMITIVE, init-value=0, base-type=BT_DS_CCF_WIRChanged, compu {phys=raw for raw 0..1}, range phys 0..1, raw 0..1, transfer-property=TRIGGERED-ON-CHANGE-WITHOUT-REPETITION  # Übertragung vom Diagnosestatus gem. 80114
          signal DS_CCF_StMemChanged_XIX_DS_CCF_XIX_HCP3_CANFD01: start 19, 1 bit, little-endian, data-type-policy=OVERRIDE, i-signal-type=PRIMITIVE, init-value=0, base-type=BT_DS_CCF_StMemChanged, compu {phys=raw for raw 0..1}, range phys 0..1, raw 0..1, transfer-property=TRIGGERED-ON-CHANGE-WITHOUT-REPETITION  # Übertragung vom Diagnosestatus gem. 80114
          signal DS_CCF_MemSel10Changed_XIX_DS_CCF_XIX_HCP3_CANFD01: start 20, 1 bit, little-endian, data-type-policy=OVERRIDE, i-signal-type=PRIMITIVE, init-value=0, base-type=BT_DS_CCF_MemSel10Changed, compu {phys=raw for raw 0..1}, range phys 0..1, raw 0..1, transfer-property=TRIGGERED-ON-CHANGE-WITHOUT-REPETITION  # Übertragung vom Diagnosestatus gem. 80114
          signal DS_CCF_MemSelChanged_XIX_DS_CCF_XIX_HCP3_CANFD01: start 21, 1 bit, little-endian, data-type-policy=OVERRIDE, i-signal-type=PRIMITIVE, init-value=0, base-type=BT_DS_CCF_MemSelChanged, compu {phys=raw for raw 0..1}, range phys 0..1, raw 0..1, transfer-property=TRIGGERED-ON-CHANGE-WITHOUT-REPETITION  # Übertragung vom Diagnosestatus gem. 80114
          signal DS_CCF_IdentValid_XIX_DS_CCF_XIX_HCP3_CANFD01: start 22, 1 bit, little-endian, data-type-policy=OVERRIDE, i-signal-type=PRIMITIVE, init-value=1, base-type=BT_DS_CCF_IdentValid, compu {0=Cx0_Ungueltig (CM_DS_CCF_IdentValid_Cx0_Ungueltig), 1=Cx1_Gueltig (CM_DS_CCF_IdentValid_Cx1_Gueltig)}, range raw 0..1, transfer-property=TRIGGERED-ON-CHANGE-WITHOUT-REPETITION  # Signalisiert ob die Identifikationsdaten gueltig sind
          signal DS_CCF_Lokalaktiv_XIX_DS_CCF_XIX_HCP3_CANFD01: start 23, 1 bit, little-endian, data-type-policy=OVERRIDE, i-signal-type=PRIMITIVE, init-value=0, base-type=BT_DS_CCF_Lokalaktiv, compu {0=Cx0_war_nicht_lokal_aktiv (CM_DS_CCF_Lokalaktiv_Cx0_war_nicht_lokal_aktiv), 1=Cx1_war_lokal_aktiv (CM_DS_CCF_Lokalaktiv_Cx1_war_lokal_aktiv)}, range raw 0..1, transfer-property=PENDING  # Zeigt an ob das SG nach Klemme15 AUS und nach entsprechender MAX Aktivzeit noch aktiv war.
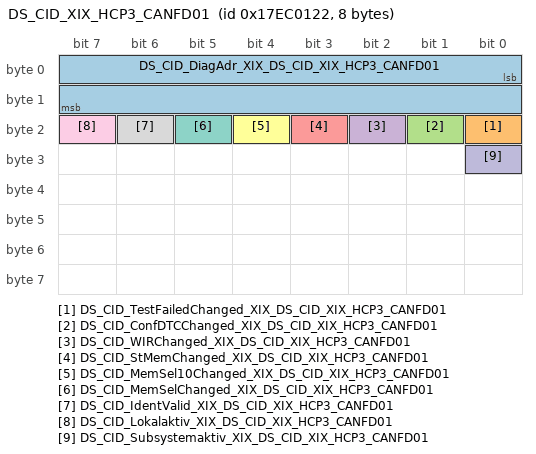
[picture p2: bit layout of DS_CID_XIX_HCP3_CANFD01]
      frame DS_CID_XIX_HCP3_CANFD01: id 0x17EC0122, to HCP3_IONode, frame-length=8, can-addressing-mode=EXTENDED, can-frame-rx-behavior=CAN-FD, can-frame-tx-behavior=CAN-FD
        pdu DS_CID_XIX_HCP3_CANFD01: length=8, minimum-delay=0.08, transmission-mode-true-timing={cyclic-timing={time-offset=0.0, time-period=1.0}, event-controlled-timing={number-of-repetitions=0, repetition-period=0.0}}, unused-bit-pattern=0
          signal DS_CID_DiagAdr_XIX_DS_CID_XIX_HCP3_CANFD01: start 0, 16 bit, little-endian, data-type-policy=OVERRIDE, i-signal-type=PRIMITIVE, init-value=33094, base-type=BT_DS_CID_DiagAdr, compu {phys=raw for raw 0..65535}, range phys 0..65535, raw 0..65535, transfer-property=PENDING  # Übertragung vom Diagnosestatus gem. 80114
          signal DS_CID_TestFailedChanged_XIX_DS_CID_XIX_HCP3_CANFD01: start 16, 1 bit, little-endian, data-type-policy=OVERRIDE, i-signal-type=PRIMITIVE, init-value=0, base-type=BT_DS_CID_TestFailedChanged, compu {phys=raw for raw 0..1}, range phys 0..1, raw 0..1, transfer-property=TRIGGERED-ON-CHANGE-WITHOUT-REPETITION  # Übertragung vom Diagnosestatus gem. 80114
          signal DS_CID_ConfDTCChanged_XIX_DS_CID_XIX_HCP3_CANFD01: start 17, 1 bit, little-endian, data-type-policy=OVERRIDE, i-signal-type=PRIMITIVE, init-value=0, base-type=BT_DS_CID_ConfDTCChanged, compu {phys=raw for raw 0..1}, range phys 0..1, raw 0..1, transfer-property=TRIGGERED-ON-CHANGE-WITHOUT-REPETITION  # Übertragung vom Diagnosestatus gem. 80114
          signal DS_CID_WIRChanged_XIX_DS_CID_XIX_HCP3_CANFD01: start 18, 1 bit, little-endian, data-type-policy=OVERRIDE, i-signal-type=PRIMITIVE, init-value=0, base-type=BT_DS_CID_WIRChanged, compu {phys=raw for raw 0..1}, range phys 0..1, raw 0..1, transfer-property=TRIGGERED-ON-CHANGE-WITHOUT-REPETITION  # Übertragung vom Diagnosestatus gem. 80114
          signal DS_CID_StMemChanged_XIX_DS_CID_XIX_HCP3_CANFD01: start 19, 1 bit, little-endian, data-type-policy=OVERRIDE, i-signal-type=PRIMITIVE, init-value=0, base-type=BT_DS_CID_StMemChanged, compu {phys=raw for raw 0..1}, range phys 0..1, raw 0..1, transfer-property=TRIGGERED-ON-CHANGE-WITHOUT-REPETITION  # Übertragung vom Diagnosestatus gem. 80114
          signal DS_CID_MemSel10Changed_XIX_DS_CID_XIX_HCP3_CANFD01: start 20, 1 bit, little-endian, data-type-policy=OVERRIDE, i-signal-type=PRIMITIVE, init-value=0, base-type=BT_DS_CID_MemSel10Changed, compu {phys=raw for raw 0..1}, range phys 0..1, raw 0..1, transfer-property=TRIGGERED-ON-CHANGE-WITHOUT-REPETITION  # Übertragung vom Diagnosestatus gem. 80114
          signal DS_CID_MemSelChanged_XIX_DS_CID_XIX_HCP3_CANFD01: start 21, 1 bit, little-endian, data-type-policy=OVERRIDE, i-signal-type=PRIMITIVE, init-value=0, base-type=BT_DS_CID_MemSelChanged, compu {phys=raw for raw 0..1}, range phys 0..1, raw 0..1, transfer-property=TRIGGERED-ON-CHANGE-WITHOUT-REPETITION  # Übertragung vom Diagnosestatus gem. 80114
          signal DS_CID_IdentValid_XIX_DS_CID_XIX_HCP3_CANFD01: start 22, 1 bit, little-endian, data-type-policy=OVERRIDE, i-signal-type=PRIMITIVE, init-value=1, base-type=BT_DS_CID_IdentValid, compu {1=Cx1_Gueltig (CM_DS_CID_IdentValid_Cx1_Gueltig), 0=Cx0_Ungueltig (CM_DS_CID_IdentValid_Cx0_Ungueltig)}, range raw 0..1, transfer-property=TRIGGERED-ON-CHANGE-WITHOUT-REPETITION  # Signalisiert ob die Identifikationsdaten gueltig sind
          signal DS_CID_Lokalaktiv_XIX_DS_CID_XIX_HCP3_CANFD01: start 23, 1 bit, little-endian, data-type-policy=OVERRIDE, i-signal-type=PRIMITIVE, init-value=0, base-type=BT_DS_CID_Lokalaktiv, compu {0=Cx0_war_nicht_lokal_aktiv (CM_DS_CID_Lokalaktiv_Cx0_war_nicht_lokal_aktiv), 1=Cx1_war_lokal_aktiv (CM_DS_CID_Lokalaktiv_Cx1_war_lokal_aktiv)}, range raw 0..1, transfer-property=PENDING  # Zeigt an ob das SG nach Klemme15 AUS und nach entsprechender MAX Aktivzeit noch aktiv war.
          signal DS_CID_Subsystemaktiv_XIX_DS_CID_XIX_HCP3_CANFD01: start 24, 1 bit, little-endian, data-type-policy=OVERRIDE, i-signal-type=PRIMITIVE, init-value=0, base-type=BT_DS_CID_Subsystemaktiv, compu {1=Cx1_war_lokal_aktiv (CM_DS_CID_Subsystemaktiv_Cx1_war_lokal_aktiv), 0=Cx0_war_nicht_lokal_aktiv (CM_DS_CID_Subsystemaktiv_Cx0_war_nicht_lokal_aktiv)}, range raw 0..1, transfer-property=PENDING  # Zeigt an ob ein Subsystem des SGs nach Klemme15 AUS und nach entsprechender MAX Aktivzeit noch aktiv war
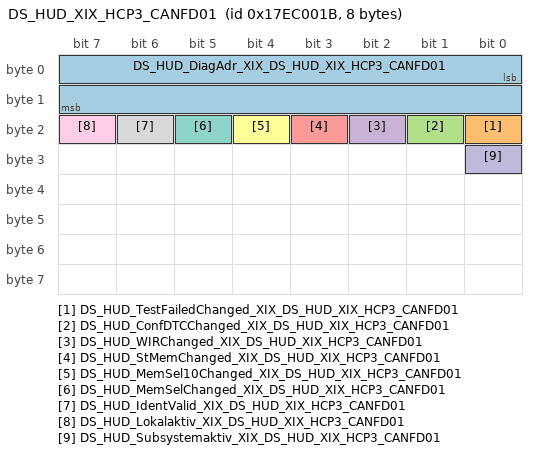
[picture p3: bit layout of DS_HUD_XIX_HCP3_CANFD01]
      frame DS_HUD_XIX_HCP3_CANFD01: id 0x17EC001B, to HCP3_IONode, frame-length=8, can-addressing-mode=EXTENDED, can-frame-rx-behavior=CAN-FD, can-frame-tx-behavior=CAN-FD
        pdu DS_HUD_XIX_HCP3_CANFD01: length=8, minimum-delay=0.08, transmission-mode-true-timing={cyclic-timing={time-offset=0.0, time-period=1.0}, event-controlled-timing={number-of-repetitions=0, repetition-period=0.0}}, unused-bit-pattern=0
          signal DS_HUD_DiagAdr_XIX_DS_HUD_XIX_HCP3_CANFD01: start 0, 16 bit, little-endian, data-type-policy=OVERRIDE, i-signal-type=PRIMITIVE, init-value=130, base-type=BT_DS_HUD_DiagAdr, compu {phys=raw for raw 0..65535}, range phys 0..65535, raw 0..65535, transfer-property=PENDING  # Übertragung vom Diagnosestatus gem. 80114
          signal DS_HUD_TestFailedChanged_XIX_DS_HUD_XIX_HCP3_CANFD01: start 16, 1 bit, little-endian, data-type-policy=OVERRIDE, i-signal-type=PRIMITIVE, init-value=0, base-type=BT_DS_HUD_TestFailedChanged, compu {phys=raw for raw 0..1}, range phys 0..1, raw 0..1, transfer-property=TRIGGERED-ON-CHANGE-WITHOUT-REPETITION  # Übertragung vom Diagnosestatus gem. 80114
          signal DS_HUD_ConfDTCChanged_XIX_DS_HUD_XIX_HCP3_CANFD01: start 17, 1 bit, little-endian, data-type-policy=OVERRIDE, i-signal-type=PRIMITIVE, init-value=0, base-type=BT_DS_HUD_ConfDTCChanged, compu {phys=raw for raw 0..1}, range phys 0..1, raw 0..1, transfer-property=TRIGGERED-ON-CHANGE-WITHOUT-REPETITION  # Übertragung vom Diagnosestatus gem. 80114
          signal DS_HUD_WIRChanged_XIX_DS_HUD_XIX_HCP3_CANFD01: start 18, 1 bit, little-endian, data-type-policy=OVERRIDE, i-signal-type=PRIMITIVE, init-value=0, base-type=BT_DS_HUD_WIRChanged, compu {phys=raw for raw 0..1}, range phys 0..1, raw 0..1, transfer-property=TRIGGERED-ON-CHANGE-WITHOUT-REPETITION  # Übertragung vom Diagnosestatus gem. 80114
          signal DS_HUD_StMemChanged_XIX_DS_HUD_XIX_HCP3_CANFD01: start 19, 1 bit, little-endian, data-type-policy=OVERRIDE, i-signal-type=PRIMITIVE, init-value=0, base-type=BT_DS_HUD_StMemChanged, compu {phys=raw for raw 0..1}, range phys 0..1, raw 0..1, transfer-property=TRIGGERED-ON-CHANGE-WITHOUT-REPETITION  # Übertragung vom Diagnosestatus gem. 80114
          signal DS_HUD_MemSel10Changed_XIX_DS_HUD_XIX_HCP3_CANFD01: start 20, 1 bit, little-endian, data-type-policy=OVERRIDE, i-signal-type=PRIMITIVE, init-value=0, base-type=BT_DS_HUD_MemSel10Changed, compu {phys=raw for raw 0..1}, range phys 0..1, raw 0..1, transfer-property=TRIGGERED-ON-CHANGE-WITHOUT-REPETITION  # Übertragung vom Diagnosestatus gem. 80114
          signal DS_HUD_MemSelChanged_XIX_DS_HUD_XIX_HCP3_CANFD01: start 21, 1 bit, little-endian, data-type-policy=OVERRIDE, i-signal-type=PRIMITIVE, init-value=0, base-type=BT_DS_HUD_MemSelChanged, compu {phys=raw for raw 0..1}, range phys 0..1, raw 0..1, transfer-property=TRIGGERED-ON-CHANGE-WITHOUT-REPETITION  # Übertragung vom Diagnosestatus gem. 80114
          signal DS_HUD_IdentValid_XIX_DS_HUD_XIX_HCP3_CANFD01: start 22, 1 bit, little-endian, data-type-policy=OVERRIDE, i-signal-type=PRIMITIVE, init-value=1, base-type=BT_DS_HUD_IdentValid, compu {1=Cx1_Gueltig (CM_DS_HUD_IdentValid_Cx1_Gueltig), 0=Cx0_Ungueltig (CM_DS_HUD_IdentValid_Cx0_Ungueltig)}, range raw 0..1, transfer-property=TRIGGERED-ON-CHANGE-WITHOUT-REPETITION  # Signalisiert ob die Identifikationsdaten gueltig sind
          signal DS_HUD_Lokalaktiv_XIX_DS_HUD_XIX_HCP3_CANFD01: start 23, 1 bit, little-endian, data-type-policy=OVERRIDE, i-signal-type=PRIMITIVE, init-value=0, base-type=BT_DS_HUD_Lokalaktiv, compu {1=Cx1_war_lokal_aktiv (CM_DS_HUD_Lokalaktiv_Cx1_war_lokal_aktiv), 0=Cx0_war_nicht_lokal_aktiv (CM_DS_HUD_Lokalaktiv_Cx0_war_nicht_lokal_aktiv)}, range raw 0..1, transfer-property=PENDING  # Zeigt an ob das SG nach Klemme15 AUS und nach entsprechender MAX Aktivzeit noch aktiv war.
          signal DS_HUD_Subsystemaktiv_XIX_DS_HUD_XIX_HCP3_CANFD01: start 24, 1 bit, little-endian, data-type-policy=OVERRIDE, i-signal-type=PRIMITIVE, init-value=0, base-type=BT_DS_HUD_Subsystemaktiv, compu {1=Cx1_war_lokal_aktiv (CM_DS_HUD_Subsystemaktiv_Cx1_war_lokal_aktiv), 0=Cx0_war_nicht_lokal_aktiv (CM_DS_HUD_Subsystemaktiv_Cx0_war_nicht_lokal_aktiv)}, range raw 0..1, transfer-property=PENDING  # Zeigt an ob ein Subsystem des SGs nach Klemme15 AUS und nach entsprechender MAX Aktivzeit noch aktiv war
